VERSION "dbc-export 1 2026.26.6.5"

NS_ :

BS_:

BU_: ADSP APB APP APS APSB BB BMS CC CMP CMPD CP DAS DI DIF DIR DPB EPAS3P EPAS3S EPASTP EPASTS EPBL EPBR ESP EVSE FC GTW HCML HCMR HVP IBST ICR IDB LS OCS1P ODIN PARK PCS PCS2 PLG PM PMF PMR PNCD PTC RADC RCM RCM2 RCM3 RCU SCCM SCM SCS SDCR TAS TCU TCU2 TPMS TRCM UDS UI UIS UMC USM V2G VC VCBATT VCBATT0 VCBATT1 VCBATT2 VCCC VCFRONT VCFRONT1 VCFRONT2 VCLEFT VCRIGHT VCSEAT2L VCSEAT2R VCSEC VEH

BO_ 785 EPAS3S_info: 8 EPAS3S
 SG_ EPAS3S_infoIndex M : 0|8@1+ (1,0) [0|255] "" Vector__XXX
 SG_ EPAS3S_infoBuildType m10 : 8|8@1+ (1,0) [0|255] "" Vector__XXX
 SG_ EPAS3S_infoComponentID m10 : 48|16@1+ (1,0) [0|65535] "" Vector__XXX
 SG_ EPAS3S_infoPcbaID m11 : 16|8@1+ (1,0) [0|255] "" Vector__XXX
 SG_ EPAS3S_infoAssemblyID m11 : 24|8@1+ (1,0) [0|255] "" Vector__XXX
 SG_ EPAS3S_infoUsageID m11 : 32|16@1+ (1,0) [0|65535] "" Vector__XXX
 SG_ EPAS3S_infoApplicationCRC m13 : 32|32@1+ (1,0) [0|4294967295] "" Vector__XXX
 SG_ EPAS3S_infoBootUdsProtoVersion m20 : 8|8@1+ (1,0) [0|255] "" Vector__XXX
 SG_ EPAS3S_infoBootloaderCRC m20 : 32|32@1+ (1,0) [0|4294967295] "" Vector__XXX
 SG_ EPAS3S_infoSubcomponent2 m23 : 32|32@1+ (1,0) [0|4294967295] "" Vector__XXX

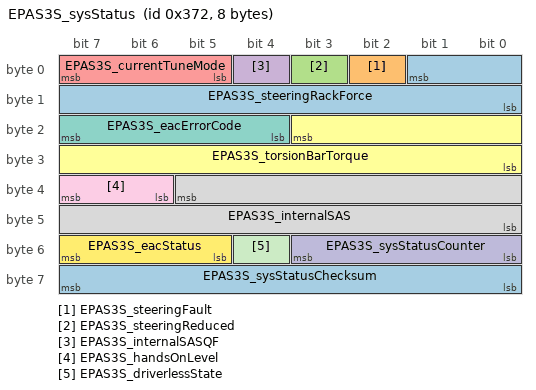
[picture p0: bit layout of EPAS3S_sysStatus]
BO_ 882 EPAS3S_sysStatus: 8 EPAS3S
 SG_ EPAS3S_steeringRackForce : 1|10@0+ (50,-25575) [-25575|25525] "N" Vector__XXX
 SG_ EPAS3S_steeringFault : 2|1@1+ (1,0) [0|1] "" Vector__XXX
 SG_ EPAS3S_steeringReduced : 3|1@1+ (1,0) [0|1] "" Vector__XXX
 SG_ EPAS3S_internalSASQF : 4|1@1+ (1,0) [0|1] "" Vector__XXX
 SG_ EPAS3S_currentTuneMode : 5|3@1+ (1,0) [0|7] "" Vector__XXX
 SG_ EPAS3S_torsionBarTorque : 19|12@0+ (0.01,-20.5) [-20.5|20.44] "Nm" Vector__XXX
 SG_ EPAS3S_eacErrorCode : 20|4@1+ (1,0) [0|14] "" Vector__XXX
 SG_ EPAS3S_internalSAS : 37|14@0+ (0.1,-819.2) [-819.2|819] "deg" Vector__XXX
 SG_ EPAS3S_handsOnLevel : 38|2@1+ (1,0) [0|3] "" Vector__XXX
 SG_ EPAS3S_sysStatusCounter : 48|4@1+ (1,0) [0|15] "" Vector__XXX
 SG_ EPAS3S_driverlessState : 52|1@1+ (1,0) [0|1] "" Vector__XXX
 SG_ EPAS3S_eacStatus : 53|3@1+ (1,0) [0|7] "" Vector__XXX
 SG_ EPAS3S_sysStatusChecksum : 56|8@1+ (1,0) [0|255] "" Vector__XXX

BO_ 1848 EPAS3S_udsResponse: 8 EPAS3S
 SG_ EPAS3S_udsResponseData : 7|64@0+ (1,0) [0|1.84467440737e+19] "" Vector__XXX

BO_ 1427 EPASTP_alertLog: 8 EPASTP
 SG_ EPASTP_alertID M : 0|9@1+ (1,0) [0|511] "" Vector__XXX
 SG_ EPASTP_alertState : 15|1@1+ (1,0) [0|1] "" Vector__XXX
 SG_ EPASTP_a001_debugInfo m1 : 16|48@1+ (1,0) [0|281474976710655] "" Vector__XXX
 SG_ EPASTP_a002_debugInfo m2 : 16|48@1+ (1,0) [0|281474976710655] "" Vector__XXX
 SG_ EPASTP_a003_debugInfo m3 : 16|48@1+ (1,0) [0|281474976710655] "" Vector__XXX
 SG_ EPASTP_a004_debugInfo m4 : 16|48@1+ (1,0) [0|281474976710655] "" Vector__XXX
 SG_ EPASTP_a005_debugInfo m5 : 16|48@1+ (1,0) [0|281474976710655] "" Vector__XXX
 SG_ EPASTP_a006_debugInfo m6 : 16|48@1+ (1,0) [0|281474976710655] "" Vector__XXX
 SG_ EPASTP_a007_debugInfo m7 : 16|48@1+ (1,0) [0|281474976710655] "" Vector__XXX
 SG_ EPASTP_a009_debugInfo m9 : 16|48@1+ (1,0) [0|281474976710655] "" Vector__XXX
 SG_ EPASTP_a010_debugInfo m10 : 16|48@1+ (1,0) [0|281474976710655] "" Vector__XXX
 SG_ EPASTP_a011_debugInfo m11 : 16|48@1+ (1,0) [0|281474976710655] "" Vector__XXX
 SG_ EPASTP_a012_debugInfo m12 : 16|48@1+ (1,0) [0|281474976710655] "" Vector__XXX
 SG_ EPASTP_a013_debugInfo m13 : 16|48@1+ (1,0) [0|281474976710655] "" Vector__XXX
 SG_ EPASTP_a014_debugInfo m14 : 16|48@1+ (1,0) [0|281474976710655] "" Vector__XXX
 SG_ EPASTP_a015_debugInfo m15 : 16|48@1+ (1,0) [0|281474976710655] "" Vector__XXX
 SG_ EPASTP_a016_debugInfo m16 : 16|48@1+ (1,0) [0|281474976710655] "" Vector__XXX
 SG_ EPASTP_a017_debugInfo m17 : 16|48@1+ (1,0) [0|281474976710655] "" Vector__XXX
 SG_ EPASTP_a018_debugInfo m18 : 16|48@1+ (1,0) [0|281474976710655] "" Vector__XXX
 SG_ EPASTP_a019_debugInfo m19 : 16|48@1+ (1,0) [0|281474976710655] "" Vector__XXX
 SG_ EPASTP_a020_debugInfo m20 : 16|48@1+ (1,0) [0|281474976710655] "" Vector__XXX
 SG_ EPASTP_a021_debugInfo m21 : 16|48@1+ (1,0) [0|281474976710655] "" Vector__XXX
 SG_ EPASTP_a022_debugInfo m22 : 16|48@1+ (1,0) [0|281474976710655] "" Vector__XXX
 SG_ EPASTP_a023_debugInfo m23 : 16|48@1+ (1,0) [0|281474976710655] "" Vector__XXX
 SG_ EPASTP_a024_debugInfo m24 : 16|48@1+ (1,0) [0|281474976710655] "" Vector__XXX
 SG_ EPASTP_a025_debugInfo m25 : 16|48@1+ (1,0) [0|281474976710655] "" Vector__XXX
 SG_ EPASTP_a026_debugInfo m26 : 16|48@1+ (1,0) [0|281474976710655] "" Vector__XXX
 SG_ EPASTP_a027_debugInfo m27 : 16|48@1+ (1,0) [0|281474976710655] "" Vector__XXX
 SG_ EPASTP_a028_debugInfo m28 : 16|48@1+ (1,0) [0|281474976710655] "" Vector__XXX
 SG_ EPASTP_a029_debugInfo m29 : 16|48@1+ (1,0) [0|281474976710655] "" Vector__XXX
 SG_ EPASTP_a030_debugInfo m30 : 16|48@1+ (1,0) [0|281474976710655] "" Vector__XXX
 SG_ EPASTP_a031_debugInfo m31 : 16|48@1+ (1,0) [0|281474976710655] "" Vector__XXX
 SG_ EPASTP_a032_debugInfo m32 : 16|48@1+ (1,0) [0|281474976710655] "" Vector__XXX
 SG_ EPASTP_a033_debugInfo m33 : 16|48@1+ (1,0) [0|281474976710655] "" Vector__XXX
 SG_ EPASTP_a034_debugInfo m34 : 16|48@1+ (1,0) [0|281474976710655] "" Vector__XXX
 SG_ EPASTP_a035_debugInfo m35 : 16|48@1+ (1,0) [0|281474976710655] "" Vector__XXX
 SG_ EPASTP_a036_debugInfo m36 : 16|48@1+ (1,0) [0|281474976710655] "" Vector__XXX
 SG_ EPASTP_a037_debugInfo m37 : 16|48@1+ (1,0) [0|281474976710655] "" Vector__XXX
 SG_ EPASTP_a038_debugInfo m38 : 16|48@1+ (1,0) [0|281474976710655] "" Vector__XXX
 SG_ EPASTP_a039_debugInfo m39 : 16|48@1+ (1,0) [0|281474976710655] "" Vector__XXX
 SG_ EPASTP_a040_debugInfo m40 : 16|48@1+ (1,0) [0|281474976710655] "" Vector__XXX
 SG_ EPASTP_a041_debugInfo m41 : 16|48@1+ (1,0) [0|281474976710655] "" Vector__XXX
 SG_ EPASTP_a042_debugInfo m42 : 16|48@1+ (1,0) [0|281474976710655] "" Vector__XXX
 SG_ EPASTP_a043_debugInfo m43 : 16|48@1+ (1,0) [0|281474976710655] "" Vector__XXX
 SG_ EPASTP_a044_debugInfo m44 : 16|48@1+ (1,0) [0|281474976710655] "" Vector__XXX
 SG_ EPASTP_a045_debugInfo m45 : 16|48@1+ (1,0) [0|281474976710655] "" Vector__XXX
 SG_ EPASTP_a046_debugInfo m46 : 16|48@1+ (1,0) [0|281474976710655] "" Vector__XXX
 SG_ EPASTP_a047_debugInfo m47 : 16|48@1+ (1,0) [0|281474976710655] "" Vector__XXX
 SG_ EPASTP_a048_debugInfo m48 : 16|48@1+ (1,0) [0|281474976710655] "" Vector__XXX
 SG_ EPASTP_a049_debugInfo m49 : 16|48@1+ (1,0) [0|281474976710655] "" Vector__XXX
 SG_ EPASTP_a050_debugInfo m50 : 16|48@1+ (1,0) [0|281474976710655] "" Vector__XXX
 SG_ EPASTP_a051_debugInfo m51 : 16|48@1+ (1,0) [0|281474976710655] "" Vector__XXX
 SG_ EPASTP_a052_debugInfo m52 : 16|48@1+ (1,0) [0|281474976710655] "" Vector__XXX
 SG_ EPASTP_a053_debugInfo m53 : 16|48@1+ (1,0) [0|281474976710655] "" Vector__XXX
 SG_ EPASTP_a054_debugInfo m54 : 16|48@1+ (1,0) [0|281474976710655] "" Vector__XXX
 SG_ EPASTP_a055_debugInfo m55 : 16|48@1+ (1,0) [0|281474976710655] "" Vector__XXX
 SG_ EPASTP_a056_debugInfo m56 : 16|48@1+ (1,0) [0|281474976710655] "" Vector__XXX
 SG_ EPASTP_a057_debugInfo m57 : 16|48@1+ (1,0) [0|281474976710655] "" Vector__XXX
 SG_ EPASTP_a058_debugInfo m58 : 16|48@1+ (1,0) [0|281474976710655] "" Vector__XXX
 SG_ EPASTP_a059_debugInfo m59 : 16|48@1+ (1,0) [0|281474976710655] "" Vector__XXX
 SG_ EPASTP_a060_debugInfo m60 : 16|48@1+ (1,0) [0|281474976710655] "" Vector__XXX
 SG_ EPASTP_a061_debugInfo m61 : 16|48@1+ (1,0) [0|281474976710655] "" Vector__XXX
 SG_ EPASTP_a062_debugInfo m62 : 16|48@1+ (1,0) [0|281474976710655] "" Vector__XXX
 SG_ EPASTP_a063_debugInfo m63 : 16|48@1+ (1,0) [0|281474976710655] "" Vector__XXX
 SG_ EPASTP_a064_debugInfo m64 : 16|48@1+ (1,0) [0|281474976710655] "" Vector__XXX
 SG_ EPASTP_a065_debugInfo m65 : 16|48@1+ (1,0) [0|281474976710655] "" Vector__XXX
 SG_ EPASTP_a066_debugInfo m66 : 16|48@1+ (1,0) [0|281474976710655] "" Vector__XXX
 SG_ EPASTP_a067_debugInfo m67 : 16|48@1+ (1,0) [0|281474976710655] "" Vector__XXX
 SG_ EPASTP_a068_debugInfo m68 : 16|48@1+ (1,0) [0|281474976710655] "" Vector__XXX
 SG_ EPASTP_a069_debugInfo m69 : 16|48@1+ (1,0) [0|281474976710655] "" Vector__XXX
 SG_ EPASTP_a070_debugInfo m70 : 16|48@1+ (1,0) [0|281474976710655] "" Vector__XXX
 SG_ EPASTP_a071_debugInfo m71 : 16|48@1+ (1,0) [0|281474976710655] "" Vector__XXX
 SG_ EPASTP_a072_debugInfo m72 : 16|48@1+ (1,0) [0|281474976710655] "" Vector__XXX
 SG_ EPASTP_a073_debugInfo m73 : 16|48@1+ (1,0) [0|281474976710655] "" Vector__XXX
 SG_ EPASTP_a074_debugInfo m74 : 16|48@1+ (1,0) [0|281474976710655] "" Vector__XXX
 SG_ EPASTP_a075_debugInfo m75 : 16|48@1+ (1,0) [0|281474976710655] "" Vector__XXX
 SG_ EPASTP_a076_debugInfo m76 : 16|48@1+ (1,0) [0|281474976710655] "" Vector__XXX
 SG_ EPASTP_a077_debugInfo m77 : 16|48@1+ (1,0) [0|281474976710655] "" Vector__XXX
 SG_ EPASTP_a078_debugInfo m78 : 16|48@1+ (1,0) [0|281474976710655] "" Vector__XXX
 SG_ EPASTP_a079_debugInfo m79 : 16|48@1+ (1,0) [0|281474976710655] "" Vector__XXX
 SG_ EPASTP_a080_debugInfo m80 : 16|48@1+ (1,0) [0|281474976710655] "" Vector__XXX
 SG_ EPASTP_a081_debugInfo m81 : 16|48@1+ (1,0) [0|281474976710655] "" Vector__XXX
 SG_ EPASTP_a082_debugInfo m82 : 16|48@1+ (1,0) [0|281474976710655] "" Vector__XXX
 SG_ EPASTP_a083_debugInfo m83 : 16|48@1+ (1,0) [0|281474976710655] "" Vector__XXX
 SG_ EPASTP_a084_debugInfo m84 : 16|48@1+ (1,0) [0|281474976710655] "" Vector__XXX
 SG_ EPASTP_a085_debugInfo m85 : 16|48@1+ (1,0) [0|281474976710655] "" Vector__XXX
 SG_ EPASTP_a086_debugInfo m86 : 16|48@1+ (1,0) [0|281474976710655] "" Vector__XXX
 SG_ EPASTP_a087_debugInfo m87 : 16|48@1+ (1,0) [0|281474976710655] "" Vector__XXX
 SG_ EPASTP_a088_debugInfo m88 : 16|48@1+ (1,0) [0|281474976710655] "" Vector__XXX
 SG_ EPASTP_a089_debugInfo m89 : 16|48@1+ (1,0) [0|281474976710655] "" Vector__XXX
 SG_ EPASTP_a090_debugInfo m90 : 16|48@1+ (1,0) [0|281474976710655] "" Vector__XXX
 SG_ EPASTP_a091_debugInfo m91 : 16|48@1+ (1,0) [0|281474976710655] "" Vector__XXX
 SG_ EPASTP_a092_debugInfo m92 : 16|48@1+ (1,0) [0|281474976710655] "" Vector__XXX
 SG_ EPASTP_a093_debugInfo m93 : 16|48@1+ (1,0) [0|281474976710655] "" Vector__XXX
 SG_ EPASTP_a094_debugInfo m94 : 16|48@1+ (1,0) [0|281474976710655] "" Vector__XXX
 SG_ EPASTP_a095_debugInfo m95 : 16|48@1+ (1,0) [0|281474976710655] "" Vector__XXX
 SG_ EPASTP_a096_debugInfo m96 : 16|48@1+ (1,0) [0|281474976710655] "" Vector__XXX
 SG_ EPASTP_a097_debugInfo m97 : 16|48@1+ (1,0) [0|281474976710655] "" Vector__XXX
 SG_ EPASTP_a098_debugInfo m98 : 16|48@1+ (1,0) [0|281474976710655] "" Vector__XXX
 SG_ EPASTP_a099_debugInfo m99 : 16|48@1+ (1,0) [0|281474976710655] "" Vector__XXX
 SG_ EPASTP_a100_debugInfo m100 : 16|48@1+ (1,0) [0|281474976710655] "" Vector__XXX
 SG_ EPASTP_a101_debugInfo m101 : 16|48@1+ (1,0) [0|281474976710655] "" Vector__XXX
 SG_ EPASTP_a102_debugInfo m102 : 16|48@1+ (1,0) [0|281474976710655] "" Vector__XXX
 SG_ EPASTP_a103_debugInfo m103 : 16|48@1+ (1,0) [0|281474976710655] "" Vector__XXX
 SG_ EPASTP_a104_debugInfo m104 : 16|48@1+ (1,0) [0|281474976710655] "" Vector__XXX
 SG_ EPASTP_a105_debugInfo m105 : 16|48@1+ (1,0) [0|281474976710655] "" Vector__XXX
 SG_ EPASTP_a106_debugInfo m106 : 16|48@1+ (1,0) [0|281474976710655] "" Vector__XXX
 SG_ EPASTP_a107_debugInfo m107 : 16|48@1+ (1,0) [0|281474976710655] "" Vector__XXX
 SG_ EPASTP_a108_debugInfo m108 : 16|48@1+ (1,0) [0|281474976710655] "" Vector__XXX
 SG_ EPASTP_a109_debugInfo m109 : 16|48@1+ (1,0) [0|281474976710655] "" Vector__XXX
 SG_ EPASTP_a110_debugInfo m110 : 16|48@1+ (1,0) [0|281474976710655] "" Vector__XXX
 SG_ EPASTP_a111_debugInfo m111 : 16|48@1+ (1,0) [0|281474976710655] "" Vector__XXX
 SG_ EPASTP_a112_debugInfo m112 : 16|48@1+ (1,0) [0|281474976710655] "" Vector__XXX
 SG_ EPASTP_a113_debugInfo m113 : 16|48@1+ (1,0) [0|281474976710655] "" Vector__XXX
 SG_ EPASTP_a114_debugInfo m114 : 16|48@1+ (1,0) [0|281474976710655] "" Vector__XXX
 SG_ EPASTP_a115_debugInfo m115 : 16|48@1+ (1,0) [0|281474976710655] "" Vector__XXX
 SG_ EPASTP_a116_debugInfo m116 : 16|48@1+ (1,0) [0|281474976710655] "" Vector__XXX
 SG_ EPASTP_a117_debugInfo m117 : 16|48@1+ (1,0) [0|281474976710655] "" Vector__XXX
 SG_ EPASTP_a118_debugInfo m118 : 16|48@1+ (1,0) [0|281474976710655] "" Vector__XXX
 SG_ EPASTP_a119_debugInfo m119 : 16|48@1+ (1,0) [0|281474976710655] "" Vector__XXX
 SG_ EPASTP_a120_debugInfo m120 : 16|48@1+ (1,0) [0|281474976710655] "" Vector__XXX
 SG_ EPASTP_a121_debugInfo m121 : 16|48@1+ (1,0) [0|281474976710655] "" Vector__XXX
 SG_ EPASTP_a122_debugInfo m122 : 16|48@1+ (1,0) [0|281474976710655] "" Vector__XXX
 SG_ EPASTP_a123_debugInfo m123 : 16|48@1+ (1,0) [0|281474976710655] "" Vector__XXX
 SG_ EPASTP_a124_debugInfo m124 : 16|48@1+ (1,0) [0|281474976710655] "" Vector__XXX
 SG_ EPASTP_a125_debugInfo m125 : 16|48@1+ (1,0) [0|281474976710655] "" Vector__XXX
 SG_ EPASTP_a126_debugInfo m126 : 16|48@1+ (1,0) [0|281474976710655] "" Vector__XXX
 SG_ EPASTP_a127_debugInfo m127 : 16|48@1+ (1,0) [0|281474976710655] "" Vector__XXX
 SG_ EPASTP_a128_debugInfo m128 : 16|48@1+ (1,0) [0|281474976710655] "" Vector__XXX
 SG_ EPASTP_a129_debugInfo m129 : 16|48@1+ (1,0) [0|281474976710655] "" Vector__XXX
 SG_ EPASTP_a130_debugInfo m130 : 16|48@1+ (1,0) [0|281474976710655] "" Vector__XXX
 SG_ EPASTP_a131_debugInfo m131 : 16|48@1+ (1,0) [0|281474976710655] "" Vector__XXX
 SG_ EPASTP_a132_debugInfo m132 : 16|48@1+ (1,0) [0|281474976710655] "" Vector__XXX
 SG_ EPASTP_a133_debugInfo m133 : 16|48@1+ (1,0) [0|281474976710655] "" Vector__XXX
 SG_ EPASTP_a134_debugInfo m134 : 16|48@1+ (1,0) [0|281474976710655] "" Vector__XXX
 SG_ EPASTP_a135_debugInfo m135 : 16|48@1+ (1,0) [0|281474976710655] "" Vector__XXX
 SG_ EPASTP_a136_debugInfo m136 : 16|48@1+ (1,0) [0|281474976710655] "" Vector__XXX
 SG_ EPASTP_a137_debugInfo m137 : 16|48@1+ (1,0) [0|281474976710655] "" Vector__XXX
 SG_ EPASTP_a138_debugInfo m138 : 16|48@1+ (1,0) [0|281474976710655] "" Vector__XXX
 SG_ EPASTP_a139_debugInfo m139 : 16|48@1+ (1,0) [0|281474976710655] "" Vector__XXX
 SG_ EPASTP_a140_debugInfo m140 : 16|48@1+ (1,0) [0|281474976710655] "" Vector__XXX
 SG_ EPASTP_a141_debugInfo m141 : 16|48@1+ (1,0) [0|281474976710655] "" Vector__XXX
 SG_ EPASTP_a142_debugInfo m142 : 16|48@1+ (1,0) [0|281474976710655] "" Vector__XXX
 SG_ EPASTP_a143_debugInfo m143 : 16|48@1+ (1,0) [0|281474976710655] "" Vector__XXX
 SG_ EPASTP_a144_debugInfo m144 : 16|48@1+ (1,0) [0|281474976710655] "" Vector__XXX
 SG_ EPASTP_a145_debugInfo m145 : 16|48@1+ (1,0) [0|281474976710655] "" Vector__XXX
 SG_ EPASTP_a146_debugInfo m146 : 16|48@1+ (1,0) [0|281474976710655] "" Vector__XXX
 SG_ EPASTP_a147_debugInfo m147 : 16|48@1+ (1,0) [0|281474976710655] "" Vector__XXX
 SG_ EPASTP_a148_debugInfo m148 : 16|48@1+ (1,0) [0|281474976710655] "" Vector__XXX
 SG_ EPASTP_a149_debugInfo m149 : 16|48@1+ (1,0) [0|281474976710655] "" Vector__XXX
 SG_ EPASTP_a150_debugInfo m150 : 16|48@1+ (1,0) [0|281474976710655] "" Vector__XXX
 SG_ EPASTP_a152_debugInfo m152 : 16|48@1+ (1,0) [0|281474976710655] "" Vector__XXX
 SG_ EPASTP_a153_debugInfo m153 : 16|48@1+ (1,0) [0|281474976710655] "" Vector__XXX
 SG_ EPASTP_a154_debugInfo m154 : 16|48@1+ (1,0) [0|281474976710655] "" Vector__XXX
 SG_ EPASTP_a155_debugInfo m155 : 16|48@1+ (1,0) [0|281474976710655] "" Vector__XXX
 SG_ EPASTP_a156_debugInfo m156 : 16|48@1+ (1,0) [0|281474976710655] "" Vector__XXX
 SG_ EPASTP_a157_debugInfo m157 : 16|48@1+ (1,0) [0|281474976710655] "" Vector__XXX
 SG_ EPASTP_a158_debugInfo m158 : 16|48@1+ (1,0) [0|281474976710655] "" Vector__XXX
 SG_ EPASTP_a159_debugInfo m159 : 16|48@1+ (1,0) [0|281474976710655] "" Vector__XXX
 SG_ EPASTP_a160_debugInfo m160 : 16|48@1+ (1,0) [0|281474976710655] "" Vector__XXX
 SG_ EPASTP_a161_debugInfo m161 : 16|48@1+ (1,0) [0|281474976710655] "" Vector__XXX
 SG_ EPASTP_a162_debugInfo m162 : 16|48@1+ (1,0) [0|281474976710655] "" Vector__XXX
 SG_ EPASTP_a163_debugInfo m163 : 16|48@1+ (1,0) [0|281474976710655] "" Vector__XXX
 SG_ EPASTP_a164_debugInfo m164 : 16|48@1+ (1,0) [0|281474976710655] "" Vector__XXX
 SG_ EPASTP_a165_debugInfo m165 : 16|48@1+ (1,0) [0|281474976710655] "" Vector__XXX
 SG_ EPASTP_a166_debugInfo m166 : 16|48@1+ (1,0) [0|281474976710655] "" Vector__XXX
 SG_ EPASTP_a167_debugInfo m167 : 16|48@1+ (1,0) [0|281474976710655] "" Vector__XXX
 SG_ EPASTP_a168_debugInfo m168 : 16|48@1+ (1,0) [0|281474976710655] "" Vector__XXX
 SG_ EPASTP_a169_debugInfo m169 : 16|48@1+ (1,0) [0|281474976710655] "" Vector__XXX
 SG_ EPASTP_a170_debugInfo m170 : 16|48@1+ (1,0) [0|281474976710655] "" Vector__XXX
 SG_ EPASTP_a171_debugInfo m171 : 16|48@1+ (1,0) [0|281474976710655] "" Vector__XXX
 SG_ EPASTP_a172_debugInfo m172 : 16|48@1+ (1,0) [0|281474976710655] "" Vector__XXX
 SG_ EPASTP_a173_debugInfo m173 : 16|48@1+ (1,0) [0|281474976710655] "" Vector__XXX
 SG_ EPASTP_a174_debugInfo m174 : 16|48@1+ (1,0) [0|281474976710655] "" Vector__XXX
 SG_ EPASTP_a175_debugInfo m175 : 16|48@1+ (1,0) [0|281474976710655] "" Vector__XXX
 SG_ EPASTP_a176_debugInfo m176 : 16|48@1+ (1,0) [0|281474976710655] "" Vector__XXX
 SG_ EPASTP_a177_debugInfo m177 : 16|48@1+ (1,0) [0|281474976710655] "" Vector__XXX
 SG_ EPASTP_a178_debugInfo m178 : 16|48@1+ (1,0) [0|281474976710655] "" Vector__XXX
 SG_ EPASTP_a179_debugInfo m179 : 16|48@1+ (1,0) [0|281474976710655] "" Vector__XXX
 SG_ EPASTP_a180_debugInfo m180 : 16|48@1+ (1,0) [0|281474976710655] "" Vector__XXX
 SG_ EPASTP_a181_debugInfo m181 : 16|48@1+ (1,0) [0|281474976710655] "" Vector__XXX
 SG_ EPASTP_a182_debugInfo m182 : 16|48@1+ (1,0) [0|281474976710655] "" Vector__XXX
 SG_ EPASTP_a183_debugInfo m183 : 16|48@1+ (1,0) [0|281474976710655] "" Vector__XXX
 SG_ EPASTP_a184_debugInfo m184 : 16|48@1+ (1,0) [0|281474976710655] "" Vector__XXX
 SG_ EPASTP_a185_debugInfo m185 : 16|48@1+ (1,0) [0|281474976710655] "" Vector__XXX
 SG_ EPASTP_a186_debugInfo m186 : 16|48@1+ (1,0) [0|281474976710655] "" Vector__XXX
 SG_ EPASTP_a188_debugInfo m188 : 16|48@1+ (1,0) [0|281474976710655] "" Vector__XXX
 SG_ EPASTP_a189_debugInfo m189 : 16|48@1+ (1,0) [0|281474976710655] "" Vector__XXX
 SG_ EPASTP_a190_debugInfo m190 : 16|48@1+ (1,0) [0|281474976710655] "" Vector__XXX
 SG_ EPASTP_a191_debugInfo m191 : 16|48@1+ (1,0) [0|281474976710655] "" Vector__XXX
 SG_ EPASTP_a192_debugInfo m192 : 16|48@1+ (1,0) [0|281474976710655] "" Vector__XXX
 SG_ EPASTP_a193_debugInfo m193 : 16|48@1+ (1,0) [0|281474976710655] "" Vector__XXX
 SG_ EPASTP_a194_debugInfo m194 : 16|48@1+ (1,0) [0|281474976710655] "" Vector__XXX
 SG_ EPASTP_a195_debugInfo m195 : 16|48@1+ (1,0) [0|281474976710655] "" Vector__XXX
 SG_ EPASTP_a196_debugInfo m196 : 16|48@1+ (1,0) [0|281474976710655] "" Vector__XXX
 SG_ EPASTP_a197_debugInfo m197 : 16|48@1+ (1,0) [0|281474976710655] "" Vector__XXX
 SG_ EPASTP_a198_debugInfo m198 : 16|48@1+ (1,0) [0|281474976710655] "" Vector__XXX
 SG_ EPASTP_a199_debugInfo m199 : 16|48@1+ (1,0) [0|281474976710655] "" Vector__XXX
 SG_ EPASTP_a200_debugInfo m200 : 16|48@1+ (1,0) [0|281474976710655] "" Vector__XXX
 SG_ EPASTP_a201_debugInfo m201 : 16|48@1+ (1,0) [0|281474976710655] "" Vector__XXX
 SG_ EPASTP_a202_debugInfo m202 : 16|48@1+ (1,0) [0|281474976710655] "" Vector__XXX
 SG_ EPASTP_a203_debugInfo m203 : 16|48@1+ (1,0) [0|281474976710655] "" Vector__XXX
 SG_ EPASTP_a204_debugInfo m204 : 16|48@1+ (1,0) [0|281474976710655] "" Vector__XXX
 SG_ EPASTP_a205_debugInfo m205 : 16|48@1+ (1,0) [0|281474976710655] "" Vector__XXX
 SG_ EPASTP_a206_debugInfo m206 : 16|48@1+ (1,0) [0|281474976710655] "" Vector__XXX
 SG_ EPASTP_a207_debugInfo m207 : 16|48@1+ (1,0) [0|281474976710655] "" Vector__XXX
 SG_ EPASTP_a208_debugInfo m208 : 16|48@1+ (1,0) [0|281474976710655] "" Vector__XXX
 SG_ EPASTP_a209_debugInfo m209 : 16|48@1+ (1,0) [0|281474976710655] "" Vector__XXX
 SG_ EPASTP_a210_debugInfo m210 : 16|48@1+ (1,0) [0|281474976710655] "" Vector__XXX
 SG_ EPASTP_a211_debugInfo m211 : 16|48@1+ (1,0) [0|281474976710655] "" Vector__XXX
 SG_ EPASTP_a212_debugInfo m212 : 16|48@1+ (1,0) [0|281474976710655] "" Vector__XXX
 SG_ EPASTP_a213_debugInfo m213 : 16|48@1+ (1,0) [0|281474976710655] "" Vector__XXX
 SG_ EPASTP_a214_debugInfo m214 : 16|48@1+ (1,0) [0|281474976710655] "" Vector__XXX
 SG_ EPASTP_a215_debugInfo m215 : 16|48@1+ (1,0) [0|281474976710655] "" Vector__XXX
 SG_ EPASTP_a216_debugInfo m216 : 16|48@1+ (1,0) [0|281474976710655] "" Vector__XXX
 SG_ EPASTP_a217_debugInfo m217 : 16|48@1+ (1,0) [0|281474976710655] "" Vector__XXX
 SG_ EPASTP_a218_debugInfo m218 : 16|48@1+ (1,0) [0|281474976710655] "" Vector__XXX
 SG_ EPASTP_a219_debugInfo m219 : 16|48@1+ (1,0) [0|281474976710655] "" Vector__XXX
 SG_ EPASTP_a221_debugInfo m221 : 16|48@1+ (1,0) [0|281474976710655] "" Vector__XXX
 SG_ EPASTP_a222_debugInfo m222 : 16|48@1+ (1,0) [0|281474976710655] "" Vector__XXX
 SG_ EPASTP_a223_debugInfo m223 : 16|48@1+ (1,0) [0|281474976710655] "" Vector__XXX
 SG_ EPASTP_a224_debugInfo m224 : 16|48@1+ (1,0) [0|281474976710655] "" Vector__XXX
 SG_ EPASTP_a225_debugInfo m225 : 16|48@1+ (1,0) [0|281474976710655] "" Vector__XXX
 SG_ EPASTP_a226_debugInfo m226 : 16|48@1+ (1,0) [0|281474976710655] "" Vector__XXX
 SG_ EPASTP_a227_debugInfo m227 : 16|48@1+ (1,0) [0|281474976710655] "" Vector__XXX
 SG_ EPASTP_a228_debugInfo m228 : 16|48@1+ (1,0) [0|281474976710655] "" Vector__XXX
 SG_ EPASTP_a229_debugInfo m229 : 16|48@1+ (1,0) [0|281474976710655] "" Vector__XXX
 SG_ EPASTP_a230_debugInfo m230 : 16|48@1+ (1,0) [0|281474976710655] "" Vector__XXX
 SG_ EPASTP_a231_debugInfo m231 : 16|48@1+ (1,0) [0|281474976710655] "" Vector__XXX
 SG_ EPASTP_a232_debugInfo m232 : 16|48@1+ (1,0) [0|281474976710655] "" Vector__XXX
 SG_ EPASTP_a233_debugInfo m233 : 16|48@1+ (1,0) [0|281474976710655] "" Vector__XXX
 SG_ EPASTP_a234_debugInfo m234 : 16|48@1+ (1,0) [0|281474976710655] "" Vector__XXX
 SG_ EPASTP_a235_debugInfo m235 : 16|48@1+ (1,0) [0|281474976710655] "" Vector__XXX
 SG_ EPASTP_a236_debugInfo m236 : 16|48@1+ (1,0) [0|281474976710655] "" Vector__XXX
 SG_ EPASTP_a237_debugInfo m237 : 16|48@1+ (1,0) [0|281474976710655] "" Vector__XXX
 SG_ EPASTP_a238_debugInfo m238 : 16|48@1+ (1,0) [0|281474976710655] "" Vector__XXX
 SG_ EPASTP_a239_debugInfo m239 : 16|48@1+ (1,0) [0|281474976710655] "" Vector__XXX
 SG_ EPASTP_a240_debugInfo m240 : 16|48@1+ (1,0) [0|281474976710655] "" Vector__XXX
 SG_ EPASTP_a241_debugInfo m241 : 16|48@1+ (1,0) [0|281474976710655] "" Vector__XXX
 SG_ EPASTP_a242_debugInfo m242 : 16|48@1+ (1,0) [0|281474976710655] "" Vector__XXX
 SG_ EPASTP_a243_debugInfo m243 : 16|48@1+ (1,0) [0|281474976710655] "" Vector__XXX
 SG_ EPASTP_a244_debugInfo m244 : 16|48@1+ (1,0) [0|281474976710655] "" Vector__XXX
 SG_ EPASTP_a245_debugInfo m245 : 16|48@1+ (1,0) [0|281474976710655] "" Vector__XXX
 SG_ EPASTP_a246_debugInfo m246 : 16|48@1+ (1,0) [0|281474976710655] "" Vector__XXX
 SG_ EPASTP_a247_debugInfo m247 : 16|48@1+ (1,0) [0|281474976710655] "" Vector__XXX
 SG_ EPASTP_a248_debugInfo m248 : 16|48@1+ (1,0) [0|281474976710655] "" Vector__XXX
 SG_ EPASTP_a249_debugInfo m249 : 16|48@1+ (1,0) [0|281474976710655] "" Vector__XXX
 SG_ EPASTP_a250_debugInfo m250 : 16|48@1+ (1,0) [0|281474976710655] "" Vector__XXX
 SG_ EPASTP_a252_debugInfo m252 : 16|48@1+ (1,0) [0|281474976710655] "" Vector__XXX
 SG_ EPASTP_a253_debugInfo m253 : 16|48@1+ (1,0) [0|281474976710655] "" Vector__XXX
 SG_ EPASTP_a254_debugInfo m254 : 16|48@1+ (1,0) [0|281474976710655] "" Vector__XXX
 SG_ EPASTP_a255_debugInfo m255 : 16|48@1+ (1,0) [0|281474976710655] "" Vector__XXX
 SG_ EPASTP_a256_debugInfo m256 : 16|48@1+ (1,0) [0|281474976710655] "" Vector__XXX
 SG_ EPASTP_a257_debugInfo m257 : 16|48@1+ (1,0) [0|281474976710655] "" Vector__XXX
 SG_ EPASTP_a258_debugInfo m258 : 16|48@1+ (1,0) [0|281474976710655] "" Vector__XXX
 SG_ EPASTP_a259_debugInfo m259 : 16|48@1+ (1,0) [0|281474976710655] "" Vector__XXX
 SG_ EPASTP_a260_debugInfo m260 : 16|48@1+ (1,0) [0|281474976710655] "" Vector__XXX
 SG_ EPASTP_a261_debugInfo m261 : 16|48@1+ (1,0) [0|281474976710655] "" Vector__XXX
 SG_ EPASTP_a262_debugInfo m262 : 16|48@1+ (1,0) [0|281474976710655] "" Vector__XXX
 SG_ EPASTP_a263_debugInfo m263 : 16|48@1+ (1,0) [0|281474976710655] "" Vector__XXX
 SG_ EPASTP_a264_degradedECU m264 : 16|8@1+ (1,0) [0|255] "" Vector__XXX
 SG_ EPASTP_a264_vehicleSpeed m264 : 24|16@1+ (0.1,0) [0|6553.5] "kph" Vector__XXX
 SG_ EPASTP_a264_powerRatio m264 : 40|8@1+ (1,0) [0|255] "percent" Vector__XXX
 SG_ EPASTP_a264_ownSideDegradationRe m264 : 48|8@1+ (1,0) [0|255] "" Vector__XXX
 SG_ EPASTP_a264_otherSideDegradation m264 : 56|8@1+ (1,0) [0|255] "" Vector__XXX
 SG_ EPASTP_a265_degradedECU m265 : 16|8@1+ (1,0) [0|255] "" Vector__XXX
 SG_ EPASTP_a265_vehicleSpeed m265 : 24|16@1+ (0.1,0) [0|6553.5] "kph" Vector__XXX
 SG_ EPASTP_a265_rawMcuTemperature m265 : 40|16@1+ (1,-100) [-100|65435] "C" Vector__XXX
 SG_ EPASTP_a265_degradedCurrentLimit m265 : 56|8@1+ (1,0) [0|255] "A" Vector__XXX
 SG_ EPASTP_a266_cdpAssistFactor m266 : 16|8@1+ (1,0) [0|255] "percent" Vector__XXX
 SG_ EPASTP_a266_vehicleSpeed m266 : 24|16@1+ (0.1,0) [0|6553.5] "kph" Vector__XXX
 SG_ EPASTP_a267_vehicleSpeed m267 : 16|16@1+ (0.1,0) [0|6553.5] "kph" Vector__XXX
 SG_ EPASTP_a267_velocityEstimatorSta m267 : 32|8@1+ (1,0) [0|255] "" Vector__XXX
 SG_ EPASTP_a269_vehicleSpeed m269 : 16|16@1+ (0.1,0) [0|6553.5] "kph" Vector__XXX
 SG_ EPASTP_a270_debugInfo m270 : 16|48@1+ (1,0) [0|281474976710655] "" Vector__XXX

BO_ 919 EPASTP_alertMatrix: 8 EPASTP
 SG_ EPASTP_matrixIndex M : 0|4@1+ (1,0) [0|15] "" Vector__XXX
 SG_ EPASTP_a001_adcCalibrationOrInit m0 : 4|1@1+ (1,0) [0|1] "" Vector__XXX
 SG_ EPASTP_a002_adcMuxErr m0 : 5|1@1+ (1,0) [0|1] "" Vector__XXX
 SG_ EPASTP_a003_pspInvalidParamset m0 : 6|1@1+ (1,0) [0|1] "" Vector__XXX
 SG_ EPASTP_a004_scpInputMia m0 : 7|1@1+ (1,0) [0|1] "" Vector__XXX
 SG_ EPASTP_a005_scpUnknownResetSourc m0 : 8|1@1+ (1,0) [0|1] "" Vector__XXX
 SG_ EPASTP_a006_swrhResetByInvalidEr m0 : 9|1@1+ (1,0) [0|1] "" Vector__XXX
 SG_ EPASTP_a007_tsmcCoreTempDiff m0 : 10|1@1+ (1,0) [0|1] "" Vector__XXX
 SG_ EPASTP_a008_psdcPlatformShutdown m0 : 11|1@1+ (1,0) [0|1] "" Vector__XXX
 SG_ EPASTP_a009_mcusscLbistPermanent m0 : 12|1@1+ (1,0) [0|1] "" Vector__XXX
 SG_ EPASTP_a010_svcIncompatibleSwVer m0 : 13|1@1+ (1,0) [0|1] "" Vector__XXX
 SG_ EPASTP_a011_mcusscMonbistErr m0 : 14|1@1+ (1,0) [0|1] "" Vector__XXX
 SG_ EPASTP_a012_mcusscMbistEccErr m0 : 15|1@1+ (1,0) [0|1] "" Vector__XXX
 SG_ EPASTP_a013_mcusscSffMonitoringF m0 : 16|1@1+ (1,0) [0|1] "" Vector__XXX
 SG_ EPASTP_a014_mcusscSffMonitoringM m0 : 17|1@1+ (1,0) [0|1] "" Vector__XXX
 SG_ EPASTP_a015_mcusscCsErrorCheckFa m0 : 18|1@1+ (1,0) [0|1] "" Vector__XXX
 SG_ EPASTP_a016_mcufcCsErrorCheckFai m0 : 19|1@1+ (1,0) [0|1] "" Vector__XXX
 SG_ EPASTP_a017_stmdStmPlausibilityC m0 : 20|1@1+ (1,0) [0|1] "" Vector__XXX
 SG_ EPASTP_a018_exchCsErrorCheck m0 : 21|1@1+ (1,0) [0|1] "" Vector__XXX
 SG_ EPASTP_a019_rsthHwResetInfoCorru m0 : 22|1@1+ (1,0) [0|1] "" Vector__XXX
 SG_ EPASTP_a020_mcusscEolEcuIdIntegr m0 : 23|1@1+ (1,0) [0|1] "" Vector__XXX
 SG_ EPASTP_a021_osehCsErrorCheck m0 : 24|1@1+ (1,0) [0|1] "" Vector__XXX
 SG_ EPASTP_a022_swrhSwResetInfoCorru m0 : 25|1@1+ (1,0) [0|1] "" Vector__XXX
 SG_ EPASTP_a023_btarcCorruptionCheck m0 : 26|1@1+ (1,0) [0|1] "" Vector__XXX
 SG_ EPASTP_a024_srhCsErrorCheckFail m0 : 27|1@1+ (1,0) [0|1] "" Vector__XXX
 SG_ EPASTP_a025_btarcCorruptionCheck m0 : 28|1@1+ (1,0) [0|1] "" Vector__XXX
 SG_ EPASTP_a026_mrccCsErrorCheckFail m0 : 29|1@1+ (1,0) [0|1] "" Vector__XXX
 SG_ EPASTP_a027_mcusscDmuHfErr m0 : 30|1@1+ (1,0) [0|1] "" Vector__XXX
 SG_ EPASTP_a028_smuhNonInitDataCorru m0 : 31|1@1+ (1,0) [0|1] "" Vector__XXX
 SG_ EPASTP_a029_smuhSmuCoreCntErrorT m0 : 32|1@1+ (1,0) [0|1] "" Vector__XXX
 SG_ EPASTP_a030_rsthClockReset m0 : 33|1@1+ (1,0) [0|1] "" Vector__XXX
 SG_ EPASTP_a031_pmsProductionModeFai m0 : 34|1@1+ (1,0) [0|1] "" Vector__XXX
 SG_ EPASTP_a032_eolpEolCheckFailed m0 : 35|1@1+ (1,0) [0|1] "" Vector__XXX
 SG_ EPASTP_a033_icsvcPswVersionMisma m0 : 36|1@1+ (1,0) [0|1] "" Vector__XXX
 SG_ EPASTP_a034_sbchReadbackRegFail m0 : 37|1@1+ (1,0) [0|1] "" Vector__XXX
 SG_ EPASTP_a035_sbchChipIdFail m0 : 38|1@1+ (1,0) [0|1] "" Vector__XXX
 SG_ EPASTP_a036_sbcmSbcBistFailed m0 : 39|1@1+ (1,0) [0|1] "" Vector__XXX
 SG_ EPASTP_a037_epmV5P2Fail m0 : 40|1@1+ (1,0) [0|1] "" Vector__XXX
 SG_ EPASTP_a038_csohCh1CsErrorErrAtR m0 : 41|1@1+ (1,0) [0|1] "" Vector__XXX
 SG_ EPASTP_a039_csohCh2CsErrorErrAtR m0 : 42|1@1+ (1,0) [0|1] "" Vector__XXX
 SG_ EPASTP_a040_swrhLimitedResetRetr m0 : 43|1@1+ (1,0) [0|1] "" Vector__XXX
 SG_ EPASTP_a041_imcmCoreConfiguratio m0 : 44|1@1+ (1,0) [0|1] "" Vector__XXX
 SG_ EPASTP_a042_wdhWdTestFail m0 : 45|1@1+ (1,0) [0|1] "" Vector__XXX
 SG_ EPASTP_a043_sbcmWdStateDisabled m0 : 46|1@1+ (1,0) [0|1] "" Vector__XXX
 SG_ EPASTP_a044_sbcmSbcEepromFail m0 : 47|1@1+ (1,0) [0|1] "" Vector__XXX
 SG_ EPASTP_a045_psumSbcBandgapVoltEr m0 : 48|1@1+ (1,0) [0|1] "" Vector__XXX
 SG_ EPASTP_a046_mcusscOscillatorNotR m0 : 49|1@1+ (1,0) [0|1] "" Vector__XXX
 SG_ EPASTP_a047_epmVregVoltFail m0 : 50|1@1+ (1,0) [0|1] "" Vector__XXX
 SG_ EPASTP_a048_epmVcpVoltFail m0 : 51|1@1+ (1,0) [0|1] "" Vector__XXX
 SG_ EPASTP_a049_epmLgFail m0 : 52|1@1+ (1,0) [0|1] "" Vector__XXX
 SG_ EPASTP_a050_erlErr m0 : 53|1@1+ (1,0) [0|1] "" Vector__XXX
 SG_ EPASTP_a051_ermMessageErr m0 : 54|1@1+ (1,0) [0|1] "" Vector__XXX
 SG_ EPASTP_a052_ermSdcInputBufferOve m0 : 55|1@1+ (1,0) [0|1] "" Vector__XXX
 SG_ EPASTP_a053_adcUnexpectedNumOfDa m0 : 56|1@1+ (1,0) [0|1] "" Vector__XXX
 SG_ EPASTP_a054_adcUnexpectedData m0 : 57|1@1+ (1,0) [0|1] "" Vector__XXX
 SG_ EPASTP_a055_amExtendedGduTest m0 : 58|1@1+ (1,0) [0|1] "" Vector__XXX
 SG_ EPASTP_a056_amGduConfigCsErrorCh m0 : 59|1@1+ (1,0) [0|1] "" Vector__XXX
 SG_ EPASTP_a057_amGduVds m0 : 60|1@1+ (1,0) [0|1] "" Vector__XXX
 SG_ EPASTP_a058_amIntVgsUndervtgErr m0 : 61|1@1+ (1,0) [0|1] "" Vector__XXX
 SG_ EPASTP_a059_amStartupTestFailed m0 : 62|1@1+ (1,0) [0|1] "" Vector__XXX
 SG_ EPASTP_a060_amGduFail m0 : 63|1@1+ (1,0) [0|1] "" Vector__XXX
 SG_ EPASTP_a061_amIntSerialErr m1 : 4|1@1+ (1,0) [0|1] "" Vector__XXX
 SG_ EPASTP_a062_amPhaseBridgeCheck m1 : 5|1@1+ (1,0) [0|1] "" Vector__XXX
 SG_ EPASTP_a063_amIntRegulatorErr m1 : 6|1@1+ (1,0) [0|1] "" Vector__XXX
 SG_ EPASTP_a064_amBridgeShort m1 : 7|1@1+ (1,0) [0|1] "" Vector__XXX
 SG_ EPASTP_a065_amGduJuncTemp m1 : 8|1@1+ (1,0) [0|1] "" Vector__XXX
 SG_ EPASTP_a066_amVoltQfErr m1 : 9|1@1+ (1,0) [0|1] "" Vector__XXX
 SG_ EPASTP_a067_tspmPowermoduleTempI m1 : 10|1@1+ (1,0) [0|1] "" Vector__XXX
 SG_ EPASTP_a068_rsthCoreRedundancyEr m1 : 11|1@1+ (1,0) [0|1] "" Vector__XXX
 SG_ EPASTP_a069_rsthCoreTempOutOfRan m1 : 12|1@1+ (1,0) [0|1] "" Vector__XXX
 SG_ EPASTP_a070_rsthInternalLowVolt m1 : 13|1@1+ (1,0) [0|1] "" Vector__XXX
 SG_ EPASTP_a071_rsthInternalHighVolt m1 : 14|1@1+ (1,0) [0|1] "" Vector__XXX
 SG_ EPASTP_a072_rsthFlashUncorrEccOr m1 : 15|1@1+ (1,0) [0|1] "" Vector__XXX
 SG_ EPASTP_a073_rsthOtherEdcEcc m1 : 16|1@1+ (1,0) [0|1] "" Vector__XXX
 SG_ EPASTP_a074_rsthUnexpectedAlarm m1 : 17|1@1+ (1,0) [0|1] "" Vector__XXX
 SG_ EPASTP_a075_rsthUnusedOtherModul m1 : 18|1@1+ (1,0) [0|1] "" Vector__XXX
 SG_ EPASTP_a076_exchGeneralException m1 : 19|1@1+ (1,0) [0|1] "" Vector__XXX
 SG_ EPASTP_a077_dmDeadlineViolation m1 : 20|1@1+ (1,0) [0|1] "" Vector__XXX
 SG_ EPASTP_a078_dmDeadlineViolation m1 : 21|1@1+ (1,0) [0|1] "" Vector__XXX
 SG_ EPASTP_a079_gduhComErr m1 : 22|1@1+ (1,0) [0|1] "" Vector__XXX
 SG_ EPASTP_a080_pwmTimerSyncCheck m1 : 23|1@1+ (1,0) [0|1] "" Vector__XXX
 SG_ EPASTP_a081_exchFloatingPointExc m1 : 24|1@1+ (1,0) [0|1] "" Vector__XXX
 SG_ EPASTP_a082_adcTriggerTimeChk m1 : 25|1@1+ (1,0) [0|1] "" Vector__XXX
 SG_ EPASTP_a083_tdaDclinkcapacitorTe m1 : 26|1@1+ (1,0) [0|1] "" Vector__XXX
 SG_ EPASTP_a084_adcTriggerCheck m1 : 27|1@1+ (1,0) [0|1] "" Vector__XXX
 SG_ EPASTP_a085_amGduSwitchOffTestBy m1 : 28|1@1+ (1,0) [0|1] "" Vector__XXX
 SG_ EPASTP_a086_rsthRamUncorrEcc m1 : 29|1@1+ (1,0) [0|1] "" Vector__XXX
 SG_ EPASTP_a087_rsthFlashConfigErr m1 : 30|1@1+ (1,0) [0|1] "" Vector__XXX
 SG_ EPASTP_a088_tedMainboardTempChec m1 : 31|1@1+ (1,0) [0|1] "" Vector__XXX
 SG_ EPASTP_a089_tedRevercebattfetjun m1 : 32|1@1+ (1,0) [0|1] "" Vector__XXX
 SG_ EPASTP_a090_etsmWarning m1 : 33|1@1+ (1,0) [0|1] "" Vector__XXX
 SG_ EPASTP_a091_bvpBattVoltCrossChkF m1 : 34|1@1+ (1,0) [0|1] "" Vector__XXX
 SG_ EPASTP_a092_amGduSwitchOffTestBy m1 : 35|1@1+ (1,0) [0|1] "" Vector__XXX
 SG_ EPASTP_a093_sctpTsuSingleStaticF m1 : 36|1@1+ (1,0) [0|1] "" Vector__XXX
 SG_ EPASTP_a094_sctpTsuMultipleStati m1 : 37|1@1+ (1,0) [0|1] "" Vector__XXX
 SG_ EPASTP_a095_mdModelBasedMotorInt m1 : 38|1@1+ (1,0) [0|1] "" Vector__XXX
 SG_ EPASTP_a096_rppRpsSingleStaticFa m1 : 39|1@1+ (1,0) [0|1] "" Vector__XXX
 SG_ EPASTP_a097_rppRpsMultipleStatic m1 : 40|1@1+ (1,0) [0|1] "" Vector__XXX
 SG_ EPASTP_a098_invErr m1 : 41|1@1+ (1,0) [0|1] "" Vector__XXX
 SG_ EPASTP_a099_mcdTorqueMismatchFau m1 : 42|1@1+ (1,0) [0|1] "" Vector__XXX
 SG_ EPASTP_a100_amVbrgLssFault m1 : 43|1@1+ (1,0) [0|1] "" Vector__XXX
 SG_ EPASTP_a101_sdrvSpcIdMismatch m1 : 44|1@1+ (1,0) [0|1] "" Vector__XXX
 SG_ EPASTP_a102_amPhasecurrentQosErr m1 : 45|1@1+ (1,0) [0|1] "" Vector__XXX
 SG_ EPASTP_a103_exhaUnusedInterruptC m1 : 46|1@1+ (1,0) [0|1] "" Vector__XXX
 SG_ EPASTP_a104_exhaBusMpuException m1 : 47|1@1+ (1,0) [0|1] "" Vector__XXX
 SG_ EPASTP_a105_exhaSriBusErrExcepti m1 : 48|1@1+ (1,0) [0|1] "" Vector__XXX
 SG_ EPASTP_a106_exhaSpbBusErrExcepti m1 : 49|1@1+ (1,0) [0|1] "" Vector__XXX
 SG_ EPASTP_a107_exhaOtherNmiExceptio m1 : 50|1@1+ (1,0) [0|1] "" Vector__XXX
 SG_ EPASTP_a108_exhaInternalProtecti m1 : 51|1@1+ (1,0) [0|1] "" Vector__XXX
 SG_ EPASTP_a109_exhaSysBusOrPeriphEr m1 : 52|1@1+ (1,0) [0|1] "" Vector__XXX
 SG_ EPASTP_a110_amPhaseRelaySwitchOf m1 : 53|1@1+ (1,0) [0|1] "" Vector__XXX
 SG_ EPASTP_a111_amCurrentSensingDisc m1 : 54|1@1+ (1,0) [0|1] "" Vector__XXX
 SG_ EPASTP_a112_rsthSafetyFlipflopEr m1 : 55|1@1+ (1,0) [0|1] "" Vector__XXX
 SG_ EPASTP_a113_rsthUncorrectableEnd m1 : 56|1@1+ (1,0) [0|1] "" Vector__XXX
 SG_ EPASTP_a114_osehOsErr m1 : 57|1@1+ (1,0) [0|1] "" Vector__XXX
 SG_ EPASTP_a115_mcusscLbistSingleFai m1 : 58|1@1+ (1,0) [0|1] "" Vector__XXX
 SG_ EPASTP_a116_mrccStartupRegCsErro m1 : 59|1@1+ (1,0) [0|1] "" Vector__XXX
 SG_ EPASTP_a117_mrccStartupRegCsErro m1 : 60|1@1+ (1,0) [0|1] "" Vector__XXX
 SG_ EPASTP_a118_mcusscFlashCsErrorEr m1 : 61|1@1+ (1,0) [0|1] "" Vector__XXX
 SG_ EPASTP_a119_mcusscFlashEccCritic m1 : 62|1@1+ (1,0) [0|1] "" Vector__XXX
 SG_ EPASTP_a120_mcusscFlashEccLatent m1 : 63|1@1+ (1,0) [0|1] "" Vector__XXX
 SG_ EPASTP_a121_mcusscMbistEccErr m2 : 4|1@1+ (1,0) [0|1] "" Vector__XXX
 SG_ EPASTP_a122_pcpBridgeFetShort m2 : 5|1@1+ (1,0) [0|1] "" Vector__XXX
 SG_ EPASTP_a123_imcmCommErr m2 : 6|1@1+ (1,0) [0|1] "" Vector__XXX
 SG_ EPASTP_a124_mcusscMbistEccTransi m2 : 7|1@1+ (1,0) [0|1] "" Vector__XXX
 SG_ EPASTP_a125_mcusscMbistMiaErr m2 : 8|1@1+ (1,0) [0|1] "" Vector__XXX
 SG_ EPASTP_a126_mcusscMonbistMiaErr m2 : 9|1@1+ (1,0) [0|1] "" Vector__XXX
 SG_ EPASTP_a127_exchAdditionalExcept m2 : 10|1@1+ (1,0) [0|1] "" Vector__XXX
 SG_ EPASTP_a128_exchExceptionStopRes m2 : 11|1@1+ (1,0) [0|1] "" Vector__XXX
 SG_ EPASTP_a129_exchAdditionalExcept m2 : 12|1@1+ (1,0) [0|1] "" Vector__XXX
 SG_ EPASTP_a130_mrccConfigCsErrorErr m2 : 13|1@1+ (1,0) [0|1] "" Vector__XXX
 SG_ EPASTP_a131_exchGuardedResetAfte m2 : 14|1@1+ (1,0) [0|1] "" Vector__XXX
 SG_ EPASTP_a132_mcusscNotSupportedMc m2 : 15|1@1+ (1,0) [0|1] "" Vector__XXX
 SG_ EPASTP_a133_mcusscLbistEcuIdIsNo m2 : 16|1@1+ (1,0) [0|1] "" Vector__XXX
 SG_ EPASTP_a134_osehGuardedResetAfte m2 : 17|1@1+ (1,0) [0|1] "" Vector__XXX
 SG_ EPASTP_a135_tmpsfetjCalculationO m2 : 18|1@1+ (1,0) [0|1] "" Vector__XXX
 SG_ EPASTP_a136_ftElectricalAngleQf m2 : 19|1@1+ (1,0) [0|1] "" Vector__XXX
 SG_ EPASTP_a137_osehErrWithoutImmedi m2 : 20|1@1+ (1,0) [0|1] "" Vector__XXX
 SG_ EPASTP_a138_osehAdditionalErrWit m2 : 21|1@1+ (1,0) [0|1] "" Vector__XXX
 SG_ EPASTP_a139_osehAdditionalOsErr m2 : 22|1@1+ (1,0) [0|1] "" Vector__XXX
 SG_ EPASTP_a140_imcmConfigurationErr m2 : 23|1@1+ (1,0) [0|1] "" Vector__XXX
 SG_ EPASTP_a141_amFetShortTest m2 : 24|1@1+ (1,0) [0|1] "" Vector__XXX
 SG_ EPASTP_a142_tedEmifilterDmcTempC m2 : 25|1@1+ (1,0) [0|1] "" Vector__XXX
 SG_ EPASTP_a143_tedEmifilterCmcTempC m2 : 26|1@1+ (1,0) [0|1] "" Vector__XXX
 SG_ EPASTP_a144_mriCoreRaminitFailed m2 : 27|1@1+ (1,0) [0|1] "" Vector__XXX
 SG_ EPASTP_a145_mriPeripheralRaminit m2 : 28|1@1+ (1,0) [0|1] "" Vector__XXX
 SG_ EPASTP_a146_btarcRcCircuitCheck m2 : 29|1@1+ (1,0) [0|1] "" Vector__XXX
 SG_ EPASTP_a147_amDcLinkShortedFail m2 : 30|1@1+ (1,0) [0|1] "" Vector__XXX
 SG_ EPASTP_a148_mrccExitFromStandbyD m2 : 31|1@1+ (1,0) [0|1] "" Vector__XXX
 SG_ EPASTP_a149_amReversibleEmergenc m2 : 32|1@1+ (1,0) [0|1] "" Vector__XXX
 SG_ EPASTP_a150_amExternalEmergencyO m2 : 33|1@1+ (1,0) [0|1] "" Vector__XXX
 SG_ EPASTP_a151_amPermanentEmergency m2 : 34|1@1+ (1,0) [0|1] "" Vector__XXX
 SG_ EPASTP_a152_exchFlashEccExceptio m2 : 35|1@1+ (1,0) [0|1] "" Vector__XXX
 SG_ EPASTP_a153_sdsmBlockSelectorInv m2 : 36|1@1+ (1,0) [0|1] "" Vector__XXX
 SG_ EPASTP_a154_sdsmCsErrorInvalidPr m2 : 37|1@1+ (1,0) [0|1] "" Vector__XXX
 SG_ EPASTP_a155_sdsmDataInvalidAll m2 : 38|1@1+ (1,0) [0|1] "" Vector__XXX
 SG_ EPASTP_a156_amIntSerialErrSafety m2 : 39|1@1+ (1,0) [0|1] "" Vector__XXX
 SG_ EPASTP_a157_mcudcpInvalidEcuId m2 : 40|1@1+ (1,0) [0|1] "" Vector__XXX
 SG_ EPASTP_a158_amGduFailDuringRecov m2 : 41|1@1+ (1,0) [0|1] "" Vector__XXX
 SG_ EPASTP_a159_exchFlashWordlineTra m2 : 42|1@1+ (1,0) [0|1] "" Vector__XXX
 SG_ EPASTP_a160_rsthCpu1UnexpectedAl m2 : 43|1@1+ (1,0) [0|1] "" Vector__XXX
 SG_ EPASTP_a161_tdaRelayfetjunctionT m2 : 44|1@1+ (1,0) [0|1] "" Vector__XXX
 SG_ EPASTP_a162_tdaBridgefetjunction m2 : 45|1@1+ (1,0) [0|1] "" Vector__XXX
 SG_ EPASTP_a163_tdaPowermoduleTempCh m2 : 46|1@1+ (1,0) [0|1] "" Vector__XXX
 SG_ EPASTP_a164_tdaBattfetjunctionTe m2 : 47|1@1+ (1,0) [0|1] "" Vector__XXX
 SG_ EPASTP_a165_tdaDcbusshuntTempChe m2 : 48|1@1+ (1,0) [0|1] "" Vector__XXX
 SG_ EPASTP_a166_tdaPhasecurrentshunt m2 : 49|1@1+ (1,0) [0|1] "" Vector__XXX
 SG_ EPASTP_a167_iccd1ErrQueueOverflo m2 : 50|1@1+ (1,0) [0|1] "" Vector__XXX
 SG_ EPASTP_a168_c1csInvalidC1App m2 : 51|1@1+ (1,0) [0|1] "" Vector__XXX
 SG_ EPASTP_a169_scpSafetyReset m2 : 52|1@1+ (1,0) [0|1] "" Vector__XXX
 SG_ EPASTP_a170_pmpDcvoltAge m2 : 53|1@1+ (1,0) [0|1] "" Vector__XXX
 SG_ EPASTP_a171_pmpKgvalueAge m2 : 54|1@1+ (1,0) [0|1] "" Vector__XXX
 SG_ EPASTP_a172_pmpElangMotorcurrent m2 : 55|1@1+ (1,0) [0|1] "" Vector__XXX
 SG_ EPASTP_a173_pmpRotorspeedAge m2 : 56|1@1+ (1,0) [0|1] "" Vector__XXX
 SG_ EPASTP_a174_pmpPhasecurrentAge m2 : 57|1@1+ (1,0) [0|1] "" Vector__XXX
 SG_ EPASTP_a175_exchFlashStoredConfi m2 : 58|1@1+ (1,0) [0|1] "" Vector__XXX
 SG_ EPASTP_a176_exchCpu1ExceptionRes m2 : 59|1@1+ (1,0) [0|1] "" Vector__XXX
 SG_ EPASTP_a177_etsrInvalidated m2 : 60|1@1+ (1,0) [0|1] "" Vector__XXX
 SG_ EPASTP_a178_exchWdtException m2 : 61|1@1+ (1,0) [0|1] "" Vector__XXX
 SG_ EPASTP_a179_tedMotorcoilTempChec m2 : 62|1@1+ (1,0) [0|1] "" Vector__XXX
 SG_ EPASTP_a180_dmDeadlineViolationC m2 : 63|1@1+ (1,0) [0|1] "" Vector__XXX
 SG_ EPASTP_a181_dmDeadlineViolationC m3 : 4|1@1+ (1,0) [0|1] "" Vector__XXX
 SG_ EPASTP_a182_mcdInputMia m3 : 5|1@1+ (1,0) [0|1] "" Vector__XXX
 SG_ EPASTP_a183_sbchCommErrSbcToMcu m3 : 6|1@1+ (1,0) [0|1] "" Vector__XXX
 SG_ EPASTP_a184_sbcmCommBufferOverfl m3 : 7|1@1+ (1,0) [0|1] "" Vector__XXX
 SG_ EPASTP_a185_sbcscpQAWatchdogRese m3 : 8|1@1+ (1,0) [0|1] "" Vector__XXX
 SG_ EPASTP_a186_wdhCommBufferOverflo m3 : 9|1@1+ (1,0) [0|1] "" Vector__XXX
 SG_ EPASTP_a187_epmVoltFail m3 : 10|1@1+ (1,0) [0|1] "" Vector__XXX
 SG_ EPASTP_a188_epmCommBufferOverflo m3 : 11|1@1+ (1,0) [0|1] "" Vector__XXX
 SG_ EPASTP_a189_sbchCommErrMcuToSbc m3 : 12|1@1+ (1,0) [0|1] "" Vector__XXX
 SG_ EPASTP_a190_sbchCommBufferOverfl m3 : 13|1@1+ (1,0) [0|1] "" Vector__XXX
 SG_ EPASTP_a191_sbcscpVcp2VucVoltFai m3 : 14|1@1+ (1,0) [0|1] "" Vector__XXX
 SG_ EPASTP_a192_osumC0CsaNearFull m3 : 15|1@1+ (1,0) [0|1] "" Vector__XXX
 SG_ EPASTP_a193_osumC0StackNearFull m3 : 16|1@1+ (1,0) [0|1] "" Vector__XXX
 SG_ EPASTP_a194_amNvdataLoss m3 : 17|1@1+ (1,0) [0|1] "" Vector__XXX
 SG_ EPASTP_a195_imcmCommErrC1 m3 : 18|1@1+ (1,0) [0|1] "" Vector__XXX
 SG_ EPASTP_a196_topEolTasOffsetInval m3 : 19|1@1+ (1,0) [0|1] "" Vector__XXX
 SG_ EPASTP_a197_difpDifactorInvalid m3 : 20|1@1+ (1,0) [0|1] "" Vector__XXX
 SG_ EPASTP_a198_osumC1CsaNearFull m3 : 21|1@1+ (1,0) [0|1] "" Vector__XXX
 SG_ EPASTP_a199_osumC1StackNearFull m3 : 22|1@1+ (1,0) [0|1] "" Vector__XXX
 SG_ EPASTP_a200_ammInputBufferOverfl m3 : 23|1@1+ (1,0) [0|1] "" Vector__XXX
 SG_ EPASTP_a201_ammOutputBufferOverf m3 : 24|1@1+ (1,0) [0|1] "" Vector__XXX
 SG_ EPASTP_a202_ohnvmpStoredOffsetLo m3 : 25|1@1+ (1,0) [0|1] "" Vector__XXX
 SG_ EPASTP_a203_ctcInterfaceErr m3 : 26|1@1+ (1,0) [0|1] "" Vector__XXX
 SG_ EPASTP_a204_fdpPrevTrqErr m3 : 27|1@1+ (1,0) [0|1] "" Vector__XXX
 SG_ EPASTP_a205_fdrOclFail m3 : 28|1@1+ (1,0) [0|1] "" Vector__XXX
 SG_ EPASTP_a206_fdrOclPartialBlockin m3 : 29|1@1+ (1,0) [0|1] "" Vector__XXX
 SG_ EPASTP_a207_fdrOclFreezing m3 : 30|1@1+ (1,0) [0|1] "" Vector__XXX
 SG_ EPASTP_a208_fdrLowSeverityBlocki m3 : 31|1@1+ (1,0) [0|1] "" Vector__XXX
 SG_ EPASTP_a209_fdrLowSeverityFreezi m3 : 32|1@1+ (1,0) [0|1] "" Vector__XXX
 SG_ EPASTP_a210_fdrTotalBlocking m3 : 33|1@1+ (1,0) [0|1] "" Vector__XXX
 SG_ EPASTP_a211_frmInternalErr m3 : 34|1@1+ (1,0) [0|1] "" Vector__XXX
 SG_ EPASTP_a212_frmDataLost m3 : 35|1@1+ (1,0) [0|1] "" Vector__XXX
 SG_ EPASTP_a213_frmHighFrictionDetec m3 : 36|1@1+ (1,0) [0|1] "" Vector__XXX
 SG_ EPASTP_a214_velInterfaceErr m3 : 37|1@1+ (1,0) [0|1] "" Vector__XXX
 SG_ EPASTP_a215_vsgSafeViolErr m3 : 38|1@1+ (1,0) [0|1] "" Vector__XXX
 SG_ EPASTP_a216_isdgImproperShutdown m3 : 39|1@1+ (1,0) [0|1] "" Vector__XXX
 SG_ EPASTP_a217_msdMasterSilentErr m3 : 40|1@1+ (1,0) [0|1] "" Vector__XXX
 SG_ EPASTP_a218_aadApplicationStateE m3 : 41|1@1+ (1,0) [0|1] "" Vector__XXX
 SG_ EPASTP_a219_frhFastRestartFailed m3 : 42|1@1+ (1,0) [0|1] "" Vector__XXX
 SG_ EPASTP_a221_apsCntError m3 : 43|1@1+ (1,0) [0|1] "" Vector__XXX
 SG_ EPASTP_a222_apsCsError m3 : 44|1@1+ (1,0) [0|1] "" Vector__XXX
 SG_ EPASTP_a223_apsMia m3 : 45|1@1+ (1,0) [0|1] "" Vector__XXX
 SG_ EPASTP_a224_dasCntError m3 : 46|1@1+ (1,0) [0|1] "" Vector__XXX
 SG_ EPASTP_a225_dasCsError m3 : 47|1@1+ (1,0) [0|1] "" Vector__XXX
 SG_ EPASTP_a226_dasMia m3 : 48|1@1+ (1,0) [0|1] "" Vector__XXX
 SG_ EPASTP_a227_dirTorqueCntError m3 : 49|1@1+ (1,0) [0|1] "" Vector__XXX
 SG_ EPASTP_a228_dirTorqueCsError m3 : 50|1@1+ (1,0) [0|1] "" Vector__XXX
 SG_ EPASTP_a229_dirTorqueMia m3 : 51|1@1+ (1,0) [0|1] "" Vector__XXX
 SG_ EPASTP_a230_diSpdCntError m3 : 52|1@1+ (1,0) [0|1] "" Vector__XXX
 SG_ EPASTP_a231_diSpdCsError m3 : 53|1@1+ (1,0) [0|1] "" Vector__XXX
 SG_ EPASTP_a232_diSpdMia m3 : 54|1@1+ (1,0) [0|1] "" Vector__XXX
 SG_ EPASTP_a233_ecu2StatCntError m3 : 55|1@1+ (1,0) [0|1] "" Vector__XXX
 SG_ EPASTP_a234_ecu2StatCsError m3 : 56|1@1+ (1,0) [0|1] "" Vector__XXX
 SG_ EPASTP_a235_ecu2StatMia m3 : 57|1@1+ (1,0) [0|1] "" Vector__XXX
 SG_ EPASTP_a236_espWrCntError m3 : 58|1@1+ (1,0) [0|1] "" Vector__XXX
 SG_ EPASTP_a237_espWrCsError m3 : 59|1@1+ (1,0) [0|1] "" Vector__XXX
 SG_ EPASTP_a238_espWrMia m3 : 60|1@1+ (1,0) [0|1] "" Vector__XXX
 SG_ EPASTP_a239_espWsCntError m3 : 61|1@1+ (1,0) [0|1] "" Vector__XXX
 SG_ EPASTP_a240_espWsCsError m3 : 62|1@1+ (1,0) [0|1] "" Vector__XXX
 SG_ EPASTP_a241_espWsMia m3 : 63|1@1+ (1,0) [0|1] "" Vector__XXX
 SG_ EPASTP_a242_gtwConfigMia m4 : 4|1@1+ (1,0) [0|1] "" Vector__XXX
 SG_ EPASTP_a243_rcmCntError m4 : 5|1@1+ (1,0) [0|1] "" Vector__XXX
 SG_ EPASTP_a244_rcmCsError m4 : 6|1@1+ (1,0) [0|1] "" Vector__XXX
 SG_ EPASTP_a245_rcmMia m4 : 7|1@1+ (1,0) [0|1] "" Vector__XXX
 SG_ EPASTP_a246_sccmCntError m4 : 8|1@1+ (1,0) [0|1] "" Vector__XXX
 SG_ EPASTP_a247_sccmCsError m4 : 9|1@1+ (1,0) [0|1] "" Vector__XXX
 SG_ EPASTP_a248_sccmMia m4 : 10|1@1+ (1,0) [0|1] "" Vector__XXX
 SG_ EPASTP_a249_uiTuneReqCntError m4 : 11|1@1+ (1,0) [0|1] "" Vector__XXX
 SG_ EPASTP_a250_uiTuneReqCsError m4 : 12|1@1+ (1,0) [0|1] "" Vector__XXX
 SG_ EPASTP_a251_uiTuneReqMia m4 : 13|1@1+ (1,0) [0|1] "" Vector__XXX
 SG_ EPASTP_a252_vcFrontCntError m4 : 14|1@1+ (1,0) [0|1] "" Vector__XXX
 SG_ EPASTP_a253_vcFrontCsError m4 : 15|1@1+ (1,0) [0|1] "" Vector__XXX
 SG_ EPASTP_a254_vcFrontMia m4 : 16|1@1+ (1,0) [0|1] "" Vector__XXX
 SG_ EPASTP_a255_pmState2Mia m4 : 17|1@1+ (1,0) [0|1] "" Vector__XXX
 SG_ EPASTP_a256_dcvmOverVolt m4 : 18|1@1+ (1,0) [0|1] "" Vector__XXX
 SG_ EPASTP_a257_dcvmUnderVolt m4 : 19|1@1+ (1,0) [0|1] "" Vector__XXX
 SG_ EPASTP_a258_pspInvalidProjectPar m4 : 20|1@1+ (1,0) [0|1] "" Vector__XXX
 SG_ EPASTP_a259_scoCanBusOff m4 : 21|1@1+ (1,0) [0|1] "" Vector__XXX
 SG_ EPASTP_a260_scoPrivateBusOff m4 : 22|1@1+ (1,0) [0|1] "" Vector__XXX
 SG_ EPASTP_a261_sccmStatusError m4 : 23|1@1+ (1,0) [0|1] "" Vector__XXX
 SG_ EPASTP_a262_yawRateStatus m4 : 24|1@1+ (1,0) [0|1] "" Vector__XXX
 SG_ EPASTP_a263_espWsStatus m4 : 25|1@1+ (1,0) [0|1] "" Vector__XXX
 SG_ EPASTP_a264_assistTorqueLimited m4 : 26|1@1+ (1,0) [0|1] "" Vector__XXX
 SG_ EPASTP_a265_overheatProtect m4 : 27|1@1+ (1,0) [0|1] "" Vector__XXX
 SG_ EPASTP_a266_overloadProtect m4 : 28|1@1+ (1,0) [0|1] "" Vector__XXX
 SG_ EPASTP_a267_safeSpeedAssist m4 : 29|1@1+ (1,0) [0|1] "" Vector__XXX
 SG_ EPASTP_a268_eacCancelled m4 : 30|1@1+ (1,0) [0|1] "" Vector__XXX
 SG_ EPASTP_a269_assistTorqueDisabled m4 : 31|1@1+ (1,0) [0|1] "" Vector__XXX
 SG_ EPASTP_a270_oscillationCompTrqLi m4 : 32|1@1+ (1,0) [0|1] "" Vector__XXX

BO_ 1428 EPASTS_alertLog: 8 EPASTS
 SG_ EPASTS_alertID M : 0|9@1+ (1,0) [0|511] "" Vector__XXX
 SG_ EPASTS_alertState : 15|1@1+ (1,0) [0|1] "" Vector__XXX
 SG_ EPASTS_a001_debugInfo m1 : 16|48@1+ (1,0) [0|281474976710655] "" Vector__XXX
 SG_ EPASTS_a002_debugInfo m2 : 16|48@1+ (1,0) [0|281474976710655] "" Vector__XXX
 SG_ EPASTS_a003_debugInfo m3 : 16|48@1+ (1,0) [0|281474976710655] "" Vector__XXX
 SG_ EPASTS_a004_debugInfo m4 : 16|48@1+ (1,0) [0|281474976710655] "" Vector__XXX
 SG_ EPASTS_a005_debugInfo m5 : 16|48@1+ (1,0) [0|281474976710655] "" Vector__XXX
 SG_ EPASTS_a006_debugInfo m6 : 16|48@1+ (1,0) [0|281474976710655] "" Vector__XXX
 SG_ EPASTS_a007_debugInfo m7 : 16|48@1+ (1,0) [0|281474976710655] "" Vector__XXX
 SG_ EPASTS_a009_debugInfo m9 : 16|48@1+ (1,0) [0|281474976710655] "" Vector__XXX
 SG_ EPASTS_a010_debugInfo m10 : 16|48@1+ (1,0) [0|281474976710655] "" Vector__XXX
 SG_ EPASTS_a011_debugInfo m11 : 16|48@1+ (1,0) [0|281474976710655] "" Vector__XXX
 SG_ EPASTS_a012_debugInfo m12 : 16|48@1+ (1,0) [0|281474976710655] "" Vector__XXX
 SG_ EPASTS_a013_debugInfo m13 : 16|48@1+ (1,0) [0|281474976710655] "" Vector__XXX
 SG_ EPASTS_a014_debugInfo m14 : 16|48@1+ (1,0) [0|281474976710655] "" Vector__XXX
 SG_ EPASTS_a015_debugInfo m15 : 16|48@1+ (1,0) [0|281474976710655] "" Vector__XXX
 SG_ EPASTS_a016_debugInfo m16 : 16|48@1+ (1,0) [0|281474976710655] "" Vector__XXX
 SG_ EPASTS_a017_debugInfo m17 : 16|48@1+ (1,0) [0|281474976710655] "" Vector__XXX
 SG_ EPASTS_a018_debugInfo m18 : 16|48@1+ (1,0) [0|281474976710655] "" Vector__XXX
 SG_ EPASTS_a019_debugInfo m19 : 16|48@1+ (1,0) [0|281474976710655] "" Vector__XXX
 SG_ EPASTS_a020_debugInfo m20 : 16|48@1+ (1,0) [0|281474976710655] "" Vector__XXX
 SG_ EPASTS_a021_debugInfo m21 : 16|48@1+ (1,0) [0|281474976710655] "" Vector__XXX
 SG_ EPASTS_a022_debugInfo m22 : 16|48@1+ (1,0) [0|281474976710655] "" Vector__XXX
 SG_ EPASTS_a023_debugInfo m23 : 16|48@1+ (1,0) [0|281474976710655] "" Vector__XXX
 SG_ EPASTS_a024_debugInfo m24 : 16|48@1+ (1,0) [0|281474976710655] "" Vector__XXX
 SG_ EPASTS_a025_debugInfo m25 : 16|48@1+ (1,0) [0|281474976710655] "" Vector__XXX
 SG_ EPASTS_a026_debugInfo m26 : 16|48@1+ (1,0) [0|281474976710655] "" Vector__XXX
 SG_ EPASTS_a027_debugInfo m27 : 16|48@1+ (1,0) [0|281474976710655] "" Vector__XXX
 SG_ EPASTS_a028_debugInfo m28 : 16|48@1+ (1,0) [0|281474976710655] "" Vector__XXX
 SG_ EPASTS_a029_debugInfo m29 : 16|48@1+ (1,0) [0|281474976710655] "" Vector__XXX
 SG_ EPASTS_a030_debugInfo m30 : 16|48@1+ (1,0) [0|281474976710655] "" Vector__XXX
 SG_ EPASTS_a031_debugInfo m31 : 16|48@1+ (1,0) [0|281474976710655] "" Vector__XXX
 SG_ EPASTS_a032_debugInfo m32 : 16|48@1+ (1,0) [0|281474976710655] "" Vector__XXX
 SG_ EPASTS_a033_debugInfo m33 : 16|48@1+ (1,0) [0|281474976710655] "" Vector__XXX
 SG_ EPASTS_a034_debugInfo m34 : 16|48@1+ (1,0) [0|281474976710655] "" Vector__XXX
 SG_ EPASTS_a035_debugInfo m35 : 16|48@1+ (1,0) [0|281474976710655] "" Vector__XXX
 SG_ EPASTS_a036_debugInfo m36 : 16|48@1+ (1,0) [0|281474976710655] "" Vector__XXX
 SG_ EPASTS_a037_debugInfo m37 : 16|48@1+ (1,0) [0|281474976710655] "" Vector__XXX
 SG_ EPASTS_a038_debugInfo m38 : 16|48@1+ (1,0) [0|281474976710655] "" Vector__XXX
 SG_ EPASTS_a039_debugInfo m39 : 16|48@1+ (1,0) [0|281474976710655] "" Vector__XXX
 SG_ EPASTS_a040_debugInfo m40 : 16|48@1+ (1,0) [0|281474976710655] "" Vector__XXX
 SG_ EPASTS_a041_debugInfo m41 : 16|48@1+ (1,0) [0|281474976710655] "" Vector__XXX
 SG_ EPASTS_a042_debugInfo m42 : 16|48@1+ (1,0) [0|281474976710655] "" Vector__XXX
 SG_ EPASTS_a043_debugInfo m43 : 16|48@1+ (1,0) [0|281474976710655] "" Vector__XXX
 SG_ EPASTS_a044_debugInfo m44 : 16|48@1+ (1,0) [0|281474976710655] "" Vector__XXX
 SG_ EPASTS_a045_debugInfo m45 : 16|48@1+ (1,0) [0|281474976710655] "" Vector__XXX
 SG_ EPASTS_a046_debugInfo m46 : 16|48@1+ (1,0) [0|281474976710655] "" Vector__XXX
 SG_ EPASTS_a047_debugInfo m47 : 16|48@1+ (1,0) [0|281474976710655] "" Vector__XXX
 SG_ EPASTS_a048_debugInfo m48 : 16|48@1+ (1,0) [0|281474976710655] "" Vector__XXX
 SG_ EPASTS_a049_debugInfo m49 : 16|48@1+ (1,0) [0|281474976710655] "" Vector__XXX
 SG_ EPASTS_a050_debugInfo m50 : 16|48@1+ (1,0) [0|281474976710655] "" Vector__XXX
 SG_ EPASTS_a051_debugInfo m51 : 16|48@1+ (1,0) [0|281474976710655] "" Vector__XXX
 SG_ EPASTS_a052_debugInfo m52 : 16|48@1+ (1,0) [0|281474976710655] "" Vector__XXX
 SG_ EPASTS_a053_debugInfo m53 : 16|48@1+ (1,0) [0|281474976710655] "" Vector__XXX
 SG_ EPASTS_a054_debugInfo m54 : 16|48@1+ (1,0) [0|281474976710655] "" Vector__XXX
 SG_ EPASTS_a055_debugInfo m55 : 16|48@1+ (1,0) [0|281474976710655] "" Vector__XXX
 SG_ EPASTS_a056_debugInfo m56 : 16|48@1+ (1,0) [0|281474976710655] "" Vector__XXX
 SG_ EPASTS_a057_debugInfo m57 : 16|48@1+ (1,0) [0|281474976710655] "" Vector__XXX
 SG_ EPASTS_a058_debugInfo m58 : 16|48@1+ (1,0) [0|281474976710655] "" Vector__XXX
 SG_ EPASTS_a059_debugInfo m59 : 16|48@1+ (1,0) [0|281474976710655] "" Vector__XXX
 SG_ EPASTS_a060_debugInfo m60 : 16|48@1+ (1,0) [0|281474976710655] "" Vector__XXX
 SG_ EPASTS_a061_debugInfo m61 : 16|48@1+ (1,0) [0|281474976710655] "" Vector__XXX
 SG_ EPASTS_a062_debugInfo m62 : 16|48@1+ (1,0) [0|281474976710655] "" Vector__XXX
 SG_ EPASTS_a063_debugInfo m63 : 16|48@1+ (1,0) [0|281474976710655] "" Vector__XXX
 SG_ EPASTS_a064_debugInfo m64 : 16|48@1+ (1,0) [0|281474976710655] "" Vector__XXX
 SG_ EPASTS_a065_debugInfo m65 : 16|48@1+ (1,0) [0|281474976710655] "" Vector__XXX
 SG_ EPASTS_a066_debugInfo m66 : 16|48@1+ (1,0) [0|281474976710655] "" Vector__XXX
 SG_ EPASTS_a067_debugInfo m67 : 16|48@1+ (1,0) [0|281474976710655] "" Vector__XXX
 SG_ EPASTS_a068_debugInfo m68 : 16|48@1+ (1,0) [0|281474976710655] "" Vector__XXX
 SG_ EPASTS_a069_debugInfo m69 : 16|48@1+ (1,0) [0|281474976710655] "" Vector__XXX
 SG_ EPASTS_a070_debugInfo m70 : 16|48@1+ (1,0) [0|281474976710655] "" Vector__XXX
 SG_ EPASTS_a071_debugInfo m71 : 16|48@1+ (1,0) [0|281474976710655] "" Vector__XXX
 SG_ EPASTS_a072_debugInfo m72 : 16|48@1+ (1,0) [0|281474976710655] "" Vector__XXX
 SG_ EPASTS_a073_debugInfo m73 : 16|48@1+ (1,0) [0|281474976710655] "" Vector__XXX
 SG_ EPASTS_a074_debugInfo m74 : 16|48@1+ (1,0) [0|281474976710655] "" Vector__XXX
 SG_ EPASTS_a075_debugInfo m75 : 16|48@1+ (1,0) [0|281474976710655] "" Vector__XXX
 SG_ EPASTS_a076_debugInfo m76 : 16|48@1+ (1,0) [0|281474976710655] "" Vector__XXX
 SG_ EPASTS_a077_debugInfo m77 : 16|48@1+ (1,0) [0|281474976710655] "" Vector__XXX
 SG_ EPASTS_a078_debugInfo m78 : 16|48@1+ (1,0) [0|281474976710655] "" Vector__XXX
 SG_ EPASTS_a079_debugInfo m79 : 16|48@1+ (1,0) [0|281474976710655] "" Vector__XXX
 SG_ EPASTS_a080_debugInfo m80 : 16|48@1+ (1,0) [0|281474976710655] "" Vector__XXX
 SG_ EPASTS_a081_debugInfo m81 : 16|48@1+ (1,0) [0|281474976710655] "" Vector__XXX
 SG_ EPASTS_a082_debugInfo m82 : 16|48@1+ (1,0) [0|281474976710655] "" Vector__XXX
 SG_ EPASTS_a083_debugInfo m83 : 16|48@1+ (1,0) [0|281474976710655] "" Vector__XXX
 SG_ EPASTS_a084_debugInfo m84 : 16|48@1+ (1,0) [0|281474976710655] "" Vector__XXX
 SG_ EPASTS_a085_debugInfo m85 : 16|48@1+ (1,0) [0|281474976710655] "" Vector__XXX
 SG_ EPASTS_a086_debugInfo m86 : 16|48@1+ (1,0) [0|281474976710655] "" Vector__XXX
 SG_ EPASTS_a087_debugInfo m87 : 16|48@1+ (1,0) [0|281474976710655] "" Vector__XXX
 SG_ EPASTS_a088_debugInfo m88 : 16|48@1+ (1,0) [0|281474976710655] "" Vector__XXX
 SG_ EPASTS_a089_debugInfo m89 : 16|48@1+ (1,0) [0|281474976710655] "" Vector__XXX
 SG_ EPASTS_a090_debugInfo m90 : 16|48@1+ (1,0) [0|281474976710655] "" Vector__XXX
 SG_ EPASTS_a091_debugInfo m91 : 16|48@1+ (1,0) [0|281474976710655] "" Vector__XXX
 SG_ EPASTS_a092_debugInfo m92 : 16|48@1+ (1,0) [0|281474976710655] "" Vector__XXX
 SG_ EPASTS_a093_debugInfo m93 : 16|48@1+ (1,0) [0|281474976710655] "" Vector__XXX
 SG_ EPASTS_a094_debugInfo m94 : 16|48@1+ (1,0) [0|281474976710655] "" Vector__XXX
 SG_ EPASTS_a095_debugInfo m95 : 16|48@1+ (1,0) [0|281474976710655] "" Vector__XXX
 SG_ EPASTS_a096_debugInfo m96 : 16|48@1+ (1,0) [0|281474976710655] "" Vector__XXX
 SG_ EPASTS_a097_debugInfo m97 : 16|48@1+ (1,0) [0|281474976710655] "" Vector__XXX
 SG_ EPASTS_a098_debugInfo m98 : 16|48@1+ (1,0) [0|281474976710655] "" Vector__XXX
 SG_ EPASTS_a099_debugInfo m99 : 16|48@1+ (1,0) [0|281474976710655] "" Vector__XXX
 SG_ EPASTS_a100_debugInfo m100 : 16|48@1+ (1,0) [0|281474976710655] "" Vector__XXX
 SG_ EPASTS_a101_debugInfo m101 : 16|48@1+ (1,0) [0|281474976710655] "" Vector__XXX
 SG_ EPASTS_a102_debugInfo m102 : 16|48@1+ (1,0) [0|281474976710655] "" Vector__XXX
 SG_ EPASTS_a103_debugInfo m103 : 16|48@1+ (1,0) [0|281474976710655] "" Vector__XXX
 SG_ EPASTS_a104_debugInfo m104 : 16|48@1+ (1,0) [0|281474976710655] "" Vector__XXX
 SG_ EPASTS_a105_debugInfo m105 : 16|48@1+ (1,0) [0|281474976710655] "" Vector__XXX
 SG_ EPASTS_a106_debugInfo m106 : 16|48@1+ (1,0) [0|281474976710655] "" Vector__XXX
 SG_ EPASTS_a107_debugInfo m107 : 16|48@1+ (1,0) [0|281474976710655] "" Vector__XXX
 SG_ EPASTS_a108_debugInfo m108 : 16|48@1+ (1,0) [0|281474976710655] "" Vector__XXX
 SG_ EPASTS_a109_debugInfo m109 : 16|48@1+ (1,0) [0|281474976710655] "" Vector__XXX
 SG_ EPASTS_a110_debugInfo m110 : 16|48@1+ (1,0) [0|281474976710655] "" Vector__XXX
 SG_ EPASTS_a111_debugInfo m111 : 16|48@1+ (1,0) [0|281474976710655] "" Vector__XXX
 SG_ EPASTS_a112_debugInfo m112 : 16|48@1+ (1,0) [0|281474976710655] "" Vector__XXX
 SG_ EPASTS_a113_debugInfo m113 : 16|48@1+ (1,0) [0|281474976710655] "" Vector__XXX
 SG_ EPASTS_a114_debugInfo m114 : 16|48@1+ (1,0) [0|281474976710655] "" Vector__XXX
 SG_ EPASTS_a115_debugInfo m115 : 16|48@1+ (1,0) [0|281474976710655] "" Vector__XXX
 SG_ EPASTS_a116_debugInfo m116 : 16|48@1+ (1,0) [0|281474976710655] "" Vector__XXX
 SG_ EPASTS_a117_debugInfo m117 : 16|48@1+ (1,0) [0|281474976710655] "" Vector__XXX
 SG_ EPASTS_a118_debugInfo m118 : 16|48@1+ (1,0) [0|281474976710655] "" Vector__XXX
 SG_ EPASTS_a119_debugInfo m119 : 16|48@1+ (1,0) [0|281474976710655] "" Vector__XXX
 SG_ EPASTS_a120_debugInfo m120 : 16|48@1+ (1,0) [0|281474976710655] "" Vector__XXX
 SG_ EPASTS_a121_debugInfo m121 : 16|48@1+ (1,0) [0|281474976710655] "" Vector__XXX
 SG_ EPASTS_a122_debugInfo m122 : 16|48@1+ (1,0) [0|281474976710655] "" Vector__XXX
 SG_ EPASTS_a123_debugInfo m123 : 16|48@1+ (1,0) [0|281474976710655] "" Vector__XXX
 SG_ EPASTS_a124_debugInfo m124 : 16|48@1+ (1,0) [0|281474976710655] "" Vector__XXX
 SG_ EPASTS_a125_debugInfo m125 : 16|48@1+ (1,0) [0|281474976710655] "" Vector__XXX
 SG_ EPASTS_a126_debugInfo m126 : 16|48@1+ (1,0) [0|281474976710655] "" Vector__XXX
 SG_ EPASTS_a127_debugInfo m127 : 16|48@1+ (1,0) [0|281474976710655] "" Vector__XXX
 SG_ EPASTS_a128_debugInfo m128 : 16|48@1+ (1,0) [0|281474976710655] "" Vector__XXX
 SG_ EPASTS_a129_debugInfo m129 : 16|48@1+ (1,0) [0|281474976710655] "" Vector__XXX
 SG_ EPASTS_a130_debugInfo m130 : 16|48@1+ (1,0) [0|281474976710655] "" Vector__XXX
 SG_ EPASTS_a131_debugInfo m131 : 16|48@1+ (1,0) [0|281474976710655] "" Vector__XXX
 SG_ EPASTS_a132_debugInfo m132 : 16|48@1+ (1,0) [0|281474976710655] "" Vector__XXX
 SG_ EPASTS_a133_debugInfo m133 : 16|48@1+ (1,0) [0|281474976710655] "" Vector__XXX
 SG_ EPASTS_a134_debugInfo m134 : 16|48@1+ (1,0) [0|281474976710655] "" Vector__XXX
 SG_ EPASTS_a135_debugInfo m135 : 16|48@1+ (1,0) [0|281474976710655] "" Vector__XXX
 SG_ EPASTS_a136_debugInfo m136 : 16|48@1+ (1,0) [0|281474976710655] "" Vector__XXX
 SG_ EPASTS_a137_debugInfo m137 : 16|48@1+ (1,0) [0|281474976710655] "" Vector__XXX
 SG_ EPASTS_a138_debugInfo m138 : 16|48@1+ (1,0) [0|281474976710655] "" Vector__XXX
 SG_ EPASTS_a139_debugInfo m139 : 16|48@1+ (1,0) [0|281474976710655] "" Vector__XXX
 SG_ EPASTS_a140_debugInfo m140 : 16|48@1+ (1,0) [0|281474976710655] "" Vector__XXX
 SG_ EPASTS_a141_debugInfo m141 : 16|48@1+ (1,0) [0|281474976710655] "" Vector__XXX
 SG_ EPASTS_a142_debugInfo m142 : 16|48@1+ (1,0) [0|281474976710655] "" Vector__XXX
 SG_ EPASTS_a143_debugInfo m143 : 16|48@1+ (1,0) [0|281474976710655] "" Vector__XXX
 SG_ EPASTS_a144_debugInfo m144 : 16|48@1+ (1,0) [0|281474976710655] "" Vector__XXX
 SG_ EPASTS_a145_debugInfo m145 : 16|48@1+ (1,0) [0|281474976710655] "" Vector__XXX
 SG_ EPASTS_a146_debugInfo m146 : 16|48@1+ (1,0) [0|281474976710655] "" Vector__XXX
 SG_ EPASTS_a147_debugInfo m147 : 16|48@1+ (1,0) [0|281474976710655] "" Vector__XXX
 SG_ EPASTS_a148_debugInfo m148 : 16|48@1+ (1,0) [0|281474976710655] "" Vector__XXX
 SG_ EPASTS_a149_debugInfo m149 : 16|48@1+ (1,0) [0|281474976710655] "" Vector__XXX
 SG_ EPASTS_a150_debugInfo m150 : 16|48@1+ (1,0) [0|281474976710655] "" Vector__XXX
 SG_ EPASTS_a152_debugInfo m152 : 16|48@1+ (1,0) [0|281474976710655] "" Vector__XXX
 SG_ EPASTS_a153_debugInfo m153 : 16|48@1+ (1,0) [0|281474976710655] "" Vector__XXX
 SG_ EPASTS_a154_debugInfo m154 : 16|48@1+ (1,0) [0|281474976710655] "" Vector__XXX
 SG_ EPASTS_a155_debugInfo m155 : 16|48@1+ (1,0) [0|281474976710655] "" Vector__XXX
 SG_ EPASTS_a156_debugInfo m156 : 16|48@1+ (1,0) [0|281474976710655] "" Vector__XXX
 SG_ EPASTS_a157_debugInfo m157 : 16|48@1+ (1,0) [0|281474976710655] "" Vector__XXX
 SG_ EPASTS_a158_debugInfo m158 : 16|48@1+ (1,0) [0|281474976710655] "" Vector__XXX
 SG_ EPASTS_a159_debugInfo m159 : 16|48@1+ (1,0) [0|281474976710655] "" Vector__XXX
 SG_ EPASTS_a160_debugInfo m160 : 16|48@1+ (1,0) [0|281474976710655] "" Vector__XXX
 SG_ EPASTS_a161_debugInfo m161 : 16|48@1+ (1,0) [0|281474976710655] "" Vector__XXX
 SG_ EPASTS_a162_debugInfo m162 : 16|48@1+ (1,0) [0|281474976710655] "" Vector__XXX
 SG_ EPASTS_a163_debugInfo m163 : 16|48@1+ (1,0) [0|281474976710655] "" Vector__XXX
 SG_ EPASTS_a164_debugInfo m164 : 16|48@1+ (1,0) [0|281474976710655] "" Vector__XXX
 SG_ EPASTS_a165_debugInfo m165 : 16|48@1+ (1,0) [0|281474976710655] "" Vector__XXX
 SG_ EPASTS_a166_debugInfo m166 : 16|48@1+ (1,0) [0|281474976710655] "" Vector__XXX
 SG_ EPASTS_a167_debugInfo m167 : 16|48@1+ (1,0) [0|281474976710655] "" Vector__XXX
 SG_ EPASTS_a168_debugInfo m168 : 16|48@1+ (1,0) [0|281474976710655] "" Vector__XXX
 SG_ EPASTS_a169_debugInfo m169 : 16|48@1+ (1,0) [0|281474976710655] "" Vector__XXX
 SG_ EPASTS_a170_debugInfo m170 : 16|48@1+ (1,0) [0|281474976710655] "" Vector__XXX
 SG_ EPASTS_a171_debugInfo m171 : 16|48@1+ (1,0) [0|281474976710655] "" Vector__XXX
 SG_ EPASTS_a172_debugInfo m172 : 16|48@1+ (1,0) [0|281474976710655] "" Vector__XXX
 SG_ EPASTS_a173_debugInfo m173 : 16|48@1+ (1,0) [0|281474976710655] "" Vector__XXX
 SG_ EPASTS_a174_debugInfo m174 : 16|48@1+ (1,0) [0|281474976710655] "" Vector__XXX
 SG_ EPASTS_a175_debugInfo m175 : 16|48@1+ (1,0) [0|281474976710655] "" Vector__XXX
 SG_ EPASTS_a176_debugInfo m176 : 16|48@1+ (1,0) [0|281474976710655] "" Vector__XXX
 SG_ EPASTS_a177_debugInfo m177 : 16|48@1+ (1,0) [0|281474976710655] "" Vector__XXX
 SG_ EPASTS_a178_debugInfo m178 : 16|48@1+ (1,0) [0|281474976710655] "" Vector__XXX
 SG_ EPASTS_a179_debugInfo m179 : 16|48@1+ (1,0) [0|281474976710655] "" Vector__XXX
 SG_ EPASTS_a180_debugInfo m180 : 16|48@1+ (1,0) [0|281474976710655] "" Vector__XXX
 SG_ EPASTS_a181_debugInfo m181 : 16|48@1+ (1,0) [0|281474976710655] "" Vector__XXX
 SG_ EPASTS_a182_debugInfo m182 : 16|48@1+ (1,0) [0|281474976710655] "" Vector__XXX
 SG_ EPASTS_a183_debugInfo m183 : 16|48@1+ (1,0) [0|281474976710655] "" Vector__XXX
 SG_ EPASTS_a184_debugInfo m184 : 16|48@1+ (1,0) [0|281474976710655] "" Vector__XXX
 SG_ EPASTS_a185_debugInfo m185 : 16|48@1+ (1,0) [0|281474976710655] "" Vector__XXX
 SG_ EPASTS_a186_debugInfo m186 : 16|48@1+ (1,0) [0|281474976710655] "" Vector__XXX
 SG_ EPASTS_a188_debugInfo m188 : 16|48@1+ (1,0) [0|281474976710655] "" Vector__XXX
 SG_ EPASTS_a189_debugInfo m189 : 16|48@1+ (1,0) [0|281474976710655] "" Vector__XXX
 SG_ EPASTS_a190_debugInfo m190 : 16|48@1+ (1,0) [0|281474976710655] "" Vector__XXX
 SG_ EPASTS_a191_debugInfo m191 : 16|48@1+ (1,0) [0|281474976710655] "" Vector__XXX
 SG_ EPASTS_a192_debugInfo m192 : 16|48@1+ (1,0) [0|281474976710655] "" Vector__XXX
 SG_ EPASTS_a193_debugInfo m193 : 16|48@1+ (1,0) [0|281474976710655] "" Vector__XXX
 SG_ EPASTS_a194_debugInfo m194 : 16|48@1+ (1,0) [0|281474976710655] "" Vector__XXX
 SG_ EPASTS_a195_debugInfo m195 : 16|48@1+ (1,0) [0|281474976710655] "" Vector__XXX
 SG_ EPASTS_a196_debugInfo m196 : 16|48@1+ (1,0) [0|281474976710655] "" Vector__XXX
 SG_ EPASTS_a197_debugInfo m197 : 16|48@1+ (1,0) [0|281474976710655] "" Vector__XXX
 SG_ EPASTS_a198_debugInfo m198 : 16|48@1+ (1,0) [0|281474976710655] "" Vector__XXX
 SG_ EPASTS_a199_debugInfo m199 : 16|48@1+ (1,0) [0|281474976710655] "" Vector__XXX
 SG_ EPASTS_a200_debugInfo m200 : 16|48@1+ (1,0) [0|281474976710655] "" Vector__XXX
 SG_ EPASTS_a201_debugInfo m201 : 16|48@1+ (1,0) [0|281474976710655] "" Vector__XXX
 SG_ EPASTS_a202_debugInfo m202 : 16|48@1+ (1,0) [0|281474976710655] "" Vector__XXX
 SG_ EPASTS_a203_debugInfo m203 : 16|48@1+ (1,0) [0|281474976710655] "" Vector__XXX
 SG_ EPASTS_a204_debugInfo m204 : 16|48@1+ (1,0) [0|281474976710655] "" Vector__XXX
 SG_ EPASTS_a205_debugInfo m205 : 16|48@1+ (1,0) [0|281474976710655] "" Vector__XXX
 SG_ EPASTS_a206_debugInfo m206 : 16|48@1+ (1,0) [0|281474976710655] "" Vector__XXX
 SG_ EPASTS_a207_debugInfo m207 : 16|48@1+ (1,0) [0|281474976710655] "" Vector__XXX
 SG_ EPASTS_a208_debugInfo m208 : 16|48@1+ (1,0) [0|281474976710655] "" Vector__XXX
 SG_ EPASTS_a209_debugInfo m209 : 16|48@1+ (1,0) [0|281474976710655] "" Vector__XXX
 SG_ EPASTS_a210_debugInfo m210 : 16|48@1+ (1,0) [0|281474976710655] "" Vector__XXX
 SG_ EPASTS_a211_debugInfo m211 : 16|48@1+ (1,0) [0|281474976710655] "" Vector__XXX
 SG_ EPASTS_a212_debugInfo m212 : 16|48@1+ (1,0) [0|281474976710655] "" Vector__XXX
 SG_ EPASTS_a213_debugInfo m213 : 16|48@1+ (1,0) [0|281474976710655] "" Vector__XXX
 SG_ EPASTS_a214_debugInfo m214 : 16|48@1+ (1,0) [0|281474976710655] "" Vector__XXX
 SG_ EPASTS_a215_debugInfo m215 : 16|48@1+ (1,0) [0|281474976710655] "" Vector__XXX
 SG_ EPASTS_a216_debugInfo m216 : 16|48@1+ (1,0) [0|281474976710655] "" Vector__XXX
 SG_ EPASTS_a217_debugInfo m217 : 16|48@1+ (1,0) [0|281474976710655] "" Vector__XXX
 SG_ EPASTS_a218_debugInfo m218 : 16|48@1+ (1,0) [0|281474976710655] "" Vector__XXX
 SG_ EPASTS_a219_debugInfo m219 : 16|48@1+ (1,0) [0|281474976710655] "" Vector__XXX
 SG_ EPASTS_a220_debugInfo m220 : 16|48@1+ (1,0) [0|281474976710655] "" Vector__XXX
 SG_ EPASTS_a221_debugInfo m221 : 16|48@1+ (1,0) [0|281474976710655] "" Vector__XXX
 SG_ EPASTS_a222_debugInfo m222 : 16|48@1+ (1,0) [0|281474976710655] "" Vector__XXX
 SG_ EPASTS_a223_debugInfo m223 : 16|48@1+ (1,0) [0|281474976710655] "" Vector__XXX
 SG_ EPASTS_a224_debugInfo m224 : 16|48@1+ (1,0) [0|281474976710655] "" Vector__XXX
 SG_ EPASTS_a225_debugInfo m225 : 16|48@1+ (1,0) [0|281474976710655] "" Vector__XXX
 SG_ EPASTS_a226_debugInfo m226 : 16|48@1+ (1,0) [0|281474976710655] "" Vector__XXX
 SG_ EPASTS_a227_debugInfo m227 : 16|48@1+ (1,0) [0|281474976710655] "" Vector__XXX
 SG_ EPASTS_a228_debugInfo m228 : 16|48@1+ (1,0) [0|281474976710655] "" Vector__XXX
 SG_ EPASTS_a229_debugInfo m229 : 16|48@1+ (1,0) [0|281474976710655] "" Vector__XXX
 SG_ EPASTS_a230_debugInfo m230 : 16|48@1+ (1,0) [0|281474976710655] "" Vector__XXX
 SG_ EPASTS_a231_debugInfo m231 : 16|48@1+ (1,0) [0|281474976710655] "" Vector__XXX
 SG_ EPASTS_a232_debugInfo m232 : 16|48@1+ (1,0) [0|281474976710655] "" Vector__XXX
 SG_ EPASTS_a233_debugInfo m233 : 16|48@1+ (1,0) [0|281474976710655] "" Vector__XXX
 SG_ EPASTS_a234_debugInfo m234 : 16|48@1+ (1,0) [0|281474976710655] "" Vector__XXX
 SG_ EPASTS_a235_debugInfo m235 : 16|48@1+ (1,0) [0|281474976710655] "" Vector__XXX
 SG_ EPASTS_a236_debugInfo m236 : 16|48@1+ (1,0) [0|281474976710655] "" Vector__XXX
 SG_ EPASTS_a237_debugInfo m237 : 16|48@1+ (1,0) [0|281474976710655] "" Vector__XXX
 SG_ EPASTS_a238_debugInfo m238 : 16|48@1+ (1,0) [0|281474976710655] "" Vector__XXX
 SG_ EPASTS_a239_debugInfo m239 : 16|48@1+ (1,0) [0|281474976710655] "" Vector__XXX
 SG_ EPASTS_a240_debugInfo m240 : 16|48@1+ (1,0) [0|281474976710655] "" Vector__XXX
 SG_ EPASTS_a241_debugInfo m241 : 16|48@1+ (1,0) [0|281474976710655] "" Vector__XXX
 SG_ EPASTS_a242_debugInfo m242 : 16|48@1+ (1,0) [0|281474976710655] "" Vector__XXX
 SG_ EPASTS_a243_debugInfo m243 : 16|48@1+ (1,0) [0|281474976710655] "" Vector__XXX
 SG_ EPASTS_a244_debugInfo m244 : 16|48@1+ (1,0) [0|281474976710655] "" Vector__XXX
 SG_ EPASTS_a245_debugInfo m245 : 16|48@1+ (1,0) [0|281474976710655] "" Vector__XXX
 SG_ EPASTS_a246_debugInfo m246 : 16|48@1+ (1,0) [0|281474976710655] "" Vector__XXX
 SG_ EPASTS_a247_debugInfo m247 : 16|48@1+ (1,0) [0|281474976710655] "" Vector__XXX
 SG_ EPASTS_a248_debugInfo m248 : 16|48@1+ (1,0) [0|281474976710655] "" Vector__XXX
 SG_ EPASTS_a249_debugInfo m249 : 16|48@1+ (1,0) [0|281474976710655] "" Vector__XXX
 SG_ EPASTS_a250_debugInfo m250 : 16|48@1+ (1,0) [0|281474976710655] "" Vector__XXX
 SG_ EPASTS_a252_debugInfo m252 : 16|48@1+ (1,0) [0|281474976710655] "" Vector__XXX
 SG_ EPASTS_a253_debugInfo m253 : 16|48@1+ (1,0) [0|281474976710655] "" Vector__XXX
 SG_ EPASTS_a254_debugInfo m254 : 16|48@1+ (1,0) [0|281474976710655] "" Vector__XXX
 SG_ EPASTS_a255_debugInfo m255 : 16|48@1+ (1,0) [0|281474976710655] "" Vector__XXX
 SG_ EPASTS_a256_debugInfo m256 : 16|48@1+ (1,0) [0|281474976710655] "" Vector__XXX
 SG_ EPASTS_a257_debugInfo m257 : 16|48@1+ (1,0) [0|281474976710655] "" Vector__XXX
 SG_ EPASTS_a258_debugInfo m258 : 16|48@1+ (1,0) [0|281474976710655] "" Vector__XXX
 SG_ EPASTS_a259_debugInfo m259 : 16|48@1+ (1,0) [0|281474976710655] "" Vector__XXX
 SG_ EPASTS_a260_debugInfo m260 : 16|48@1+ (1,0) [0|281474976710655] "" Vector__XXX
 SG_ EPASTS_a261_debugInfo m261 : 16|48@1+ (1,0) [0|281474976710655] "" Vector__XXX
 SG_ EPASTS_a262_debugInfo m262 : 16|48@1+ (1,0) [0|281474976710655] "" Vector__XXX
 SG_ EPASTS_a263_debugInfo m263 : 16|48@1+ (1,0) [0|281474976710655] "" Vector__XXX
 SG_ EPASTS_a264_degradedECU m264 : 16|8@1+ (1,0) [0|255] "" Vector__XXX
 SG_ EPASTS_a264_vehicleSpeed m264 : 24|16@1+ (0.1,0) [0|6553.5] "kph" Vector__XXX
 SG_ EPASTS_a264_powerRatio m264 : 40|8@1+ (1,0) [0|255] "percent" Vector__XXX
 SG_ EPASTS_a264_ownSideDegradationRe m264 : 48|8@1+ (1,0) [0|255] "" Vector__XXX
 SG_ EPASTS_a264_otherSideDegradation m264 : 56|8@1+ (1,0) [0|255] "" Vector__XXX
 SG_ EPASTS_a265_degradedECU m265 : 16|8@1+ (1,0) [0|255] "" Vector__XXX
 SG_ EPASTS_a265_vehicleSpeed m265 : 24|16@1+ (0.1,0) [0|6553.5] "kph" Vector__XXX
 SG_ EPASTS_a265_rawMcuTemperature m265 : 40|16@1+ (1,-100) [-100|65435] "C" Vector__XXX
 SG_ EPASTS_a265_degradedCurrentLimit m265 : 56|8@1+ (1,0) [0|255] "A" Vector__XXX
 SG_ EPASTS_a266_cdpAssistFactor m266 : 16|8@1+ (1,0) [0|255] "percent" Vector__XXX
 SG_ EPASTS_a266_vehicleSpeed m266 : 24|16@1+ (0.1,0) [0|6553.5] "kph" Vector__XXX
 SG_ EPASTS_a267_vehicleSpeed m267 : 16|16@1+ (0.1,0) [0|6553.5] "kph" Vector__XXX
 SG_ EPASTS_a267_velocityEstimatorSta m267 : 32|8@1+ (1,0) [0|255] "" Vector__XXX
 SG_ EPASTS_a269_vehicleSpeed m269 : 16|16@1+ (0.1,0) [0|6553.5] "kph" Vector__XXX
 SG_ EPASTS_a270_debugInfo m270 : 16|48@1+ (1,0) [0|281474976710655] "" Vector__XXX

BO_TX_BU_ 785 : EPAS3S;
BO_TX_BU_ 882 : EPAS3S;
BO_TX_BU_ 1848 : EPAS3S;
BO_TX_BU_ 1427 : EPASTP;
BO_TX_BU_ 919 : EPASTP;
BO_TX_BU_ 1428 : EPASTS;
CM_ BO_ 785 "Electric power steering (secondary) message: info";
CM_ SG_ 785 EPAS3S_infoIndex "Electric power steering (secondary): info index";
CM_ SG_ 785 EPAS3S_infoBuildType "Electric power steering (secondary): info build type";
CM_ SG_ 785 EPAS3S_infoComponentID "Electric power steering (secondary): info component ID";
CM_ SG_ 785 EPAS3S_infoPcbaID "Electric power steering (secondary): info pcba ID";
CM_ SG_ 785 EPAS3S_infoAssemblyID "Electric power steering (secondary): info assembly ID";
CM_ SG_ 785 EPAS3S_infoUsageID "Electric power steering (secondary): info usage ID";
CM_ SG_ 785 EPAS3S_infoApplicationCRC "Electric power steering (secondary): info application CRC";
CM_ SG_ 785 EPAS3S_infoBootUdsProtoVersion "Electric power steering (secondary): info boot uds proto version";
CM_ SG_ 785 EPAS3S_infoBootloaderCRC "Electric power steering (secondary): info bootloader CRC";
CM_ SG_ 785 EPAS3S_infoSubcomponent2 "Electric power steering (secondary): info subcomponent2";
CM_ BO_ 882 "Electric power steering (secondary) message: sys status";
CM_ SG_ 882 EPAS3S_steeringRackForce "The real time, estimated force applied by the steering rack to the tie rods; raw 1023 = signal not available (SNA)";
CM_ SG_ 882 EPAS3S_steeringFault "Electric power steering (secondary): steering fault";
CM_ SG_ 882 EPAS3S_steeringReduced "Electric power steering (secondary): steering reduced";
CM_ SG_ 882 EPAS3S_internalSASQF "This signal identifies the validity of the EPAS3P_internalSAS signal.";
CM_ SG_ 882 EPAS3S_currentTuneMode "Electric power steering (secondary): current tune mode";
CM_ SG_ 882 EPAS3S_torsionBarTorque "The measurement of the steering wheel torque input. If the value is positive the steering wheel torque is applied in the clockwise direction; raw 4095 = signal not available (SNA)";
CM_ SG_ 882 EPAS3S_eacErrorCode "Electric power steering (secondary): eac error code; raw 15 = signal not available (SNA)";
CM_ SG_ 882 EPAS3S_internalSAS "The measurement of the steering wheel angle that is calculated by electronic power steering assist steering. Clockwise positive.";
CM_ SG_ 882 EPAS3S_handsOnLevel "Electric power steering (secondary): hands on level";
CM_ SG_ 882 EPAS3S_sysStatusCounter "Electric power steering (secondary): sys status counter";
CM_ SG_ 882 EPAS3S_driverlessState "Electric power steering (secondary): driverless state";
CM_ SG_ 882 EPAS3S_eacStatus "Electric power steering (secondary): eac status";
CM_ SG_ 882 EPAS3S_sysStatusChecksum "Electric power steering (secondary): sys status checksum";
CM_ BO_ 1848 "Electric power steering (secondary) message: uds response";
CM_ SG_ 1848 EPAS3S_udsResponseData "Electric power steering (secondary): uds response data";
CM_ BO_ 1427 "EPASTP ECU message: alert log";
CM_ SG_ 1427 EPASTP_alertID "EPASTP ECU: alert ID";
CM_ SG_ 1427 EPASTP_alertState "EPASTP ECU: alert state";
CM_ SG_ 1427 EPASTP_a001_debugInfo "EPASTP ECU: a001 debug info";
CM_ SG_ 1427 EPASTP_a002_debugInfo "EPASTP ECU: a002 debug info";
CM_ SG_ 1427 EPASTP_a003_debugInfo "EPASTP ECU: a003 debug info";
CM_ SG_ 1427 EPASTP_a004_debugInfo "EPASTP ECU: a004 debug info";
CM_ SG_ 1427 EPASTP_a005_debugInfo "EPASTP ECU: a005 debug info";
CM_ SG_ 1427 EPASTP_a006_debugInfo "EPASTP ECU: a006 debug info";
CM_ SG_ 1427 EPASTP_a007_debugInfo "EPASTP ECU: a007 debug info";
CM_ SG_ 1427 EPASTP_a009_debugInfo "EPASTP ECU: a009 debug info";
CM_ SG_ 1427 EPASTP_a010_debugInfo "EPASTP ECU: a010 debug info";
CM_ SG_ 1427 EPASTP_a011_debugInfo "EPASTP ECU: a011 debug info";
CM_ SG_ 1427 EPASTP_a012_debugInfo "EPASTP ECU: a012 debug info";
CM_ SG_ 1427 EPASTP_a013_debugInfo "EPASTP ECU: a013 debug info";
CM_ SG_ 1427 EPASTP_a014_debugInfo "EPASTP ECU: a014 debug info";
CM_ SG_ 1427 EPASTP_a015_debugInfo "EPASTP ECU: a015 debug info";
CM_ SG_ 1427 EPASTP_a016_debugInfo "EPASTP ECU: a016 debug info";
CM_ SG_ 1427 EPASTP_a017_debugInfo "EPASTP ECU: a017 debug info";
CM_ SG_ 1427 EPASTP_a018_debugInfo "EPASTP ECU: a018 debug info";
CM_ SG_ 1427 EPASTP_a019_debugInfo "EPASTP ECU: a019 debug info";
CM_ SG_ 1427 EPASTP_a020_debugInfo "EPASTP ECU: a020 debug info";
CM_ SG_ 1427 EPASTP_a021_debugInfo "EPASTP ECU: a021 debug info";
CM_ SG_ 1427 EPASTP_a022_debugInfo "EPASTP ECU: a022 debug info";
CM_ SG_ 1427 EPASTP_a023_debugInfo "EPASTP ECU: a023 debug info";
CM_ SG_ 1427 EPASTP_a024_debugInfo "EPASTP ECU: a024 debug info";
CM_ SG_ 1427 EPASTP_a025_debugInfo "EPASTP ECU: a025 debug info";
CM_ SG_ 1427 EPASTP_a026_debugInfo "EPASTP ECU: a026 debug info";
CM_ SG_ 1427 EPASTP_a027_debugInfo "EPASTP ECU: a027 debug info";
CM_ SG_ 1427 EPASTP_a028_debugInfo "EPASTP ECU: a028 debug info";
CM_ SG_ 1427 EPASTP_a029_debugInfo "EPASTP ECU: a029 debug info";
CM_ SG_ 1427 EPASTP_a030_debugInfo "EPASTP ECU: a030 debug info";
CM_ SG_ 1427 EPASTP_a031_debugInfo "EPASTP ECU: a031 debug info";
CM_ SG_ 1427 EPASTP_a032_debugInfo "EPASTP ECU: a032 debug info";
CM_ SG_ 1427 EPASTP_a033_debugInfo "EPASTP ECU: a033 debug info";
CM_ SG_ 1427 EPASTP_a034_debugInfo "EPASTP ECU: a034 debug info";
CM_ SG_ 1427 EPASTP_a035_debugInfo "EPASTP ECU: a035 debug info";
CM_ SG_ 1427 EPASTP_a036_debugInfo "EPASTP ECU: a036 debug info";
CM_ SG_ 1427 EPASTP_a037_debugInfo "EPASTP ECU: a037 debug info";
CM_ SG_ 1427 EPASTP_a038_debugInfo "EPASTP ECU: a038 debug info";
CM_ SG_ 1427 EPASTP_a039_debugInfo "EPASTP ECU: a039 debug info";
CM_ SG_ 1427 EPASTP_a040_debugInfo "EPASTP ECU: a040 debug info";
CM_ SG_ 1427 EPASTP_a041_debugInfo "EPASTP ECU: a041 debug info";
CM_ SG_ 1427 EPASTP_a042_debugInfo "EPASTP ECU: a042 debug info";
CM_ SG_ 1427 EPASTP_a043_debugInfo "EPASTP ECU: a043 debug info";
CM_ SG_ 1427 EPASTP_a044_debugInfo "EPASTP ECU: a044 debug info";
CM_ SG_ 1427 EPASTP_a045_debugInfo "EPASTP ECU: a045 debug info";
CM_ SG_ 1427 EPASTP_a046_debugInfo "EPASTP ECU: a046 debug info";
CM_ SG_ 1427 EPASTP_a047_debugInfo "EPASTP ECU: a047 debug info";
CM_ SG_ 1427 EPASTP_a048_debugInfo "EPASTP ECU: a048 debug info";
CM_ SG_ 1427 EPASTP_a049_debugInfo "EPASTP ECU: a049 debug info";
CM_ SG_ 1427 EPASTP_a050_debugInfo "EPASTP ECU: a050 debug info";
CM_ SG_ 1427 EPASTP_a051_debugInfo "EPASTP ECU: a051 debug info";
CM_ SG_ 1427 EPASTP_a052_debugInfo "EPASTP ECU: a052 debug info";
CM_ SG_ 1427 EPASTP_a053_debugInfo "EPASTP ECU: a053 debug info";
CM_ SG_ 1427 EPASTP_a054_debugInfo "EPASTP ECU: a054 debug info";
CM_ SG_ 1427 EPASTP_a055_debugInfo "EPASTP ECU: a055 debug info";
CM_ SG_ 1427 EPASTP_a056_debugInfo "EPASTP ECU: a056 debug info";
CM_ SG_ 1427 EPASTP_a057_debugInfo "EPASTP ECU: a057 debug info";
CM_ SG_ 1427 EPASTP_a058_debugInfo "EPASTP ECU: a058 debug info";
CM_ SG_ 1427 EPASTP_a059_debugInfo "EPASTP ECU: a059 debug info";
CM_ SG_ 1427 EPASTP_a060_debugInfo "EPASTP ECU: a060 debug info";
CM_ SG_ 1427 EPASTP_a061_debugInfo "EPASTP ECU: a061 debug info";
CM_ SG_ 1427 EPASTP_a062_debugInfo "EPASTP ECU: a062 debug info";
CM_ SG_ 1427 EPASTP_a063_debugInfo "EPASTP ECU: a063 debug info";
CM_ SG_ 1427 EPASTP_a064_debugInfo "EPASTP ECU: a064 debug info";
CM_ SG_ 1427 EPASTP_a065_debugInfo "EPASTP ECU: a065 debug info";
CM_ SG_ 1427 EPASTP_a066_debugInfo "EPASTP ECU: a066 debug info";
CM_ SG_ 1427 EPASTP_a067_debugInfo "EPASTP ECU: a067 debug info";
CM_ SG_ 1427 EPASTP_a068_debugInfo "EPASTP ECU: a068 debug info";
CM_ SG_ 1427 EPASTP_a069_debugInfo "EPASTP ECU: a069 debug info";
CM_ SG_ 1427 EPASTP_a070_debugInfo "EPASTP ECU: a070 debug info";
CM_ SG_ 1427 EPASTP_a071_debugInfo "EPASTP ECU: a071 debug info";
CM_ SG_ 1427 EPASTP_a072_debugInfo "EPASTP ECU: a072 debug info";
CM_ SG_ 1427 EPASTP_a073_debugInfo "EPASTP ECU: a073 debug info";
CM_ SG_ 1427 EPASTP_a074_debugInfo "EPASTP ECU: a074 debug info";
CM_ SG_ 1427 EPASTP_a075_debugInfo "EPASTP ECU: a075 debug info";
CM_ SG_ 1427 EPASTP_a076_debugInfo "EPASTP ECU: a076 debug info";
CM_ SG_ 1427 EPASTP_a077_debugInfo "EPASTP ECU: a077 debug info";
CM_ SG_ 1427 EPASTP_a078_debugInfo "EPASTP ECU: a078 debug info";
CM_ SG_ 1427 EPASTP_a079_debugInfo "EPASTP ECU: a079 debug info";
CM_ SG_ 1427 EPASTP_a080_debugInfo "EPASTP ECU: a080 debug info";
CM_ SG_ 1427 EPASTP_a081_debugInfo "EPASTP ECU: a081 debug info";
CM_ SG_ 1427 EPASTP_a082_debugInfo "EPASTP ECU: a082 debug info";
CM_ SG_ 1427 EPASTP_a083_debugInfo "EPASTP ECU: a083 debug info";
CM_ SG_ 1427 EPASTP_a084_debugInfo "EPASTP ECU: a084 debug info";
CM_ SG_ 1427 EPASTP_a085_debugInfo "EPASTP ECU: a085 debug info";
CM_ SG_ 1427 EPASTP_a086_debugInfo "EPASTP ECU: a086 debug info";
CM_ SG_ 1427 EPASTP_a087_debugInfo "EPASTP ECU: a087 debug info";
CM_ SG_ 1427 EPASTP_a088_debugInfo "EPASTP ECU: a088 debug info";
CM_ SG_ 1427 EPASTP_a089_debugInfo "EPASTP ECU: a089 debug info";
CM_ SG_ 1427 EPASTP_a090_debugInfo "EPASTP ECU: a090 debug info";
CM_ SG_ 1427 EPASTP_a091_debugInfo "EPASTP ECU: a091 debug info";
CM_ SG_ 1427 EPASTP_a092_debugInfo "EPASTP ECU: a092 debug info";
CM_ SG_ 1427 EPASTP_a093_debugInfo "EPASTP ECU: a093 debug info";
CM_ SG_ 1427 EPASTP_a094_debugInfo "EPASTP ECU: a094 debug info";
CM_ SG_ 1427 EPASTP_a095_debugInfo "EPASTP ECU: a095 debug info";
CM_ SG_ 1427 EPASTP_a096_debugInfo "EPASTP ECU: a096 debug info";
CM_ SG_ 1427 EPASTP_a097_debugInfo "EPASTP ECU: a097 debug info";
CM_ SG_ 1427 EPASTP_a098_debugInfo "EPASTP ECU: a098 debug info";
CM_ SG_ 1427 EPASTP_a099_debugInfo "EPASTP ECU: a099 debug info";
CM_ SG_ 1427 EPASTP_a100_debugInfo "EPASTP ECU: a100 debug info";
CM_ SG_ 1427 EPASTP_a101_debugInfo "EPASTP ECU: a101 debug info";
CM_ SG_ 1427 EPASTP_a102_debugInfo "EPASTP ECU: a102 debug info";
CM_ SG_ 1427 EPASTP_a103_debugInfo "EPASTP ECU: a103 debug info";
CM_ SG_ 1427 EPASTP_a104_debugInfo "EPASTP ECU: a104 debug info";
CM_ SG_ 1427 EPASTP_a105_debugInfo "EPASTP ECU: a105 debug info";
CM_ SG_ 1427 EPASTP_a106_debugInfo "EPASTP ECU: a106 debug info";
CM_ SG_ 1427 EPASTP_a107_debugInfo "EPASTP ECU: a107 debug info";
CM_ SG_ 1427 EPASTP_a108_debugInfo "EPASTP ECU: a108 debug info";
CM_ SG_ 1427 EPASTP_a109_debugInfo "EPASTP ECU: a109 debug info";
CM_ SG_ 1427 EPASTP_a110_debugInfo "EPASTP ECU: a110 debug info";
CM_ SG_ 1427 EPASTP_a111_debugInfo "EPASTP ECU: a111 debug info";
CM_ SG_ 1427 EPASTP_a112_debugInfo "EPASTP ECU: a112 debug info";
CM_ SG_ 1427 EPASTP_a113_debugInfo "EPASTP ECU: a113 debug info";
CM_ SG_ 1427 EPASTP_a114_debugInfo "EPASTP ECU: a114 debug info";
CM_ SG_ 1427 EPASTP_a115_debugInfo "EPASTP ECU: a115 debug info";
CM_ SG_ 1427 EPASTP_a116_debugInfo "EPASTP ECU: a116 debug info";
CM_ SG_ 1427 EPASTP_a117_debugInfo "EPASTP ECU: a117 debug info";
CM_ SG_ 1427 EPASTP_a118_debugInfo "EPASTP ECU: a118 debug info";
CM_ SG_ 1427 EPASTP_a119_debugInfo "EPASTP ECU: a119 debug info";
CM_ SG_ 1427 EPASTP_a120_debugInfo "EPASTP ECU: a120 debug info";
CM_ SG_ 1427 EPASTP_a121_debugInfo "EPASTP ECU: a121 debug info";
CM_ SG_ 1427 EPASTP_a122_debugInfo "EPASTP ECU: a122 debug info";
CM_ SG_ 1427 EPASTP_a123_debugInfo "EPASTP ECU: a123 debug info";
CM_ SG_ 1427 EPASTP_a124_debugInfo "EPASTP ECU: a124 debug info";
CM_ SG_ 1427 EPASTP_a125_debugInfo "EPASTP ECU: a125 debug info";
CM_ SG_ 1427 EPASTP_a126_debugInfo "EPASTP ECU: a126 debug info";
CM_ SG_ 1427 EPASTP_a127_debugInfo "EPASTP ECU: a127 debug info";
CM_ SG_ 1427 EPASTP_a128_debugInfo "EPASTP ECU: a128 debug info";
CM_ SG_ 1427 EPASTP_a129_debugInfo "EPASTP ECU: a129 debug info";
CM_ SG_ 1427 EPASTP_a130_debugInfo "EPASTP ECU: a130 debug info";
CM_ SG_ 1427 EPASTP_a131_debugInfo "EPASTP ECU: a131 debug info";
CM_ SG_ 1427 EPASTP_a132_debugInfo "EPASTP ECU: a132 debug info";
CM_ SG_ 1427 EPASTP_a133_debugInfo "EPASTP ECU: a133 debug info";
CM_ SG_ 1427 EPASTP_a134_debugInfo "EPASTP ECU: a134 debug info";
CM_ SG_ 1427 EPASTP_a135_debugInfo "EPASTP ECU: a135 debug info";
CM_ SG_ 1427 EPASTP_a136_debugInfo "EPASTP ECU: a136 debug info";
CM_ SG_ 1427 EPASTP_a137_debugInfo "EPASTP ECU: a137 debug info";
CM_ SG_ 1427 EPASTP_a138_debugInfo "EPASTP ECU: a138 debug info";
CM_ SG_ 1427 EPASTP_a139_debugInfo "EPASTP ECU: a139 debug info";
CM_ SG_ 1427 EPASTP_a140_debugInfo "EPASTP ECU: a140 debug info";
CM_ SG_ 1427 EPASTP_a141_debugInfo "EPASTP ECU: a141 debug info";
CM_ SG_ 1427 EPASTP_a142_debugInfo "EPASTP ECU: a142 debug info";
CM_ SG_ 1427 EPASTP_a143_debugInfo "EPASTP ECU: a143 debug info";
CM_ SG_ 1427 EPASTP_a144_debugInfo "EPASTP ECU: a144 debug info";
CM_ SG_ 1427 EPASTP_a145_debugInfo "EPASTP ECU: a145 debug info";
CM_ SG_ 1427 EPASTP_a146_debugInfo "EPASTP ECU: a146 debug info";
CM_ SG_ 1427 EPASTP_a147_debugInfo "EPASTP ECU: a147 debug info";
CM_ SG_ 1427 EPASTP_a148_debugInfo "EPASTP ECU: a148 debug info";
CM_ SG_ 1427 EPASTP_a149_debugInfo "EPASTP ECU: a149 debug info";
CM_ SG_ 1427 EPASTP_a150_debugInfo "EPASTP ECU: a150 debug info";
CM_ SG_ 1427 EPASTP_a152_debugInfo "EPASTP ECU: a152 debug info";
CM_ SG_ 1427 EPASTP_a153_debugInfo "EPASTP ECU: a153 debug info";
CM_ SG_ 1427 EPASTP_a154_debugInfo "EPASTP ECU: a154 debug info";
CM_ SG_ 1427 EPASTP_a155_debugInfo "EPASTP ECU: a155 debug info";
CM_ SG_ 1427 EPASTP_a156_debugInfo "EPASTP ECU: a156 debug info";
CM_ SG_ 1427 EPASTP_a157_debugInfo "EPASTP ECU: a157 debug info";
CM_ SG_ 1427 EPASTP_a158_debugInfo "EPASTP ECU: a158 debug info";
CM_ SG_ 1427 EPASTP_a159_debugInfo "EPASTP ECU: a159 debug info";
CM_ SG_ 1427 EPASTP_a160_debugInfo "EPASTP ECU: a160 debug info";
CM_ SG_ 1427 EPASTP_a161_debugInfo "EPASTP ECU: a161 debug info";
CM_ SG_ 1427 EPASTP_a162_debugInfo "EPASTP ECU: a162 debug info";
CM_ SG_ 1427 EPASTP_a163_debugInfo "EPASTP ECU: a163 debug info";
CM_ SG_ 1427 EPASTP_a164_debugInfo "EPASTP ECU: a164 debug info";
CM_ SG_ 1427 EPASTP_a165_debugInfo "EPASTP ECU: a165 debug info";
CM_ SG_ 1427 EPASTP_a166_debugInfo "EPASTP ECU: a166 debug info";
CM_ SG_ 1427 EPASTP_a167_debugInfo "EPASTP ECU: a167 debug info";
CM_ SG_ 1427 EPASTP_a168_debugInfo "EPASTP ECU: a168 debug info";
CM_ SG_ 1427 EPASTP_a169_debugInfo "EPASTP ECU: a169 debug info";
CM_ SG_ 1427 EPASTP_a170_debugInfo "EPASTP ECU: a170 debug info";
CM_ SG_ 1427 EPASTP_a171_debugInfo "EPASTP ECU: a171 debug info";
CM_ SG_ 1427 EPASTP_a172_debugInfo "EPASTP ECU: a172 debug info";
CM_ SG_ 1427 EPASTP_a173_debugInfo "EPASTP ECU: a173 debug info";
CM_ SG_ 1427 EPASTP_a174_debugInfo "EPASTP ECU: a174 debug info";
CM_ SG_ 1427 EPASTP_a175_debugInfo "EPASTP ECU: a175 debug info";
CM_ SG_ 1427 EPASTP_a176_debugInfo "EPASTP ECU: a176 debug info";
CM_ SG_ 1427 EPASTP_a177_debugInfo "EPASTP ECU: a177 debug info";
CM_ SG_ 1427 EPASTP_a178_debugInfo "EPASTP ECU: a178 debug info";
CM_ SG_ 1427 EPASTP_a179_debugInfo "EPASTP ECU: a179 debug info";
CM_ SG_ 1427 EPASTP_a180_debugInfo "EPASTP ECU: a180 debug info";
CM_ SG_ 1427 EPASTP_a181_debugInfo "EPASTP ECU: a181 debug info";
CM_ SG_ 1427 EPASTP_a182_debugInfo "EPASTP ECU: a182 debug info";
CM_ SG_ 1427 EPASTP_a183_debugInfo "EPASTP ECU: a183 debug info";
CM_ SG_ 1427 EPASTP_a184_debugInfo "EPASTP ECU: a184 debug info";
CM_ SG_ 1427 EPASTP_a185_debugInfo "EPASTP ECU: a185 debug info";
CM_ SG_ 1427 EPASTP_a186_debugInfo "EPASTP ECU: a186 debug info";
CM_ SG_ 1427 EPASTP_a188_debugInfo "EPASTP ECU: a188 debug info";
CM_ SG_ 1427 EPASTP_a189_debugInfo "EPASTP ECU: a189 debug info";
CM_ SG_ 1427 EPASTP_a190_debugInfo "EPASTP ECU: a190 debug info";
CM_ SG_ 1427 EPASTP_a191_debugInfo "EPASTP ECU: a191 debug info";
CM_ SG_ 1427 EPASTP_a192_debugInfo "EPASTP ECU: a192 debug info";
CM_ SG_ 1427 EPASTP_a193_debugInfo "EPASTP ECU: a193 debug info";
CM_ SG_ 1427 EPASTP_a194_debugInfo "EPASTP ECU: a194 debug info";
CM_ SG_ 1427 EPASTP_a195_debugInfo "EPASTP ECU: a195 debug info";
CM_ SG_ 1427 EPASTP_a196_debugInfo "EPASTP ECU: a196 debug info";
CM_ SG_ 1427 EPASTP_a197_debugInfo "EPASTP ECU: a197 debug info";
CM_ SG_ 1427 EPASTP_a198_debugInfo "EPASTP ECU: a198 debug info";
CM_ SG_ 1427 EPASTP_a199_debugInfo "EPASTP ECU: a199 debug info";
CM_ SG_ 1427 EPASTP_a200_debugInfo "EPASTP ECU: a200 debug info";
CM_ SG_ 1427 EPASTP_a201_debugInfo "EPASTP ECU: a201 debug info";
CM_ SG_ 1427 EPASTP_a202_debugInfo "EPASTP ECU: a202 debug info";
CM_ SG_ 1427 EPASTP_a203_debugInfo "EPASTP ECU: a203 debug info";
CM_ SG_ 1427 EPASTP_a204_debugInfo "EPASTP ECU: a204 debug info";
CM_ SG_ 1427 EPASTP_a205_debugInfo "EPASTP ECU: a205 debug info";
CM_ SG_ 1427 EPASTP_a206_debugInfo "EPASTP ECU: a206 debug info";
CM_ SG_ 1427 EPASTP_a207_debugInfo "EPASTP ECU: a207 debug info";
CM_ SG_ 1427 EPASTP_a208_debugInfo "EPASTP ECU: a208 debug info";
CM_ SG_ 1427 EPASTP_a209_debugInfo "EPASTP ECU: a209 debug info";
CM_ SG_ 1427 EPASTP_a210_debugInfo "EPASTP ECU: a210 debug info";
CM_ SG_ 1427 EPASTP_a211_debugInfo "EPASTP ECU: a211 debug info";
CM_ SG_ 1427 EPASTP_a212_debugInfo "EPASTP ECU: a212 debug info";
CM_ SG_ 1427 EPASTP_a213_debugInfo "EPASTP ECU: a213 debug info";
CM_ SG_ 1427 EPASTP_a214_debugInfo "EPASTP ECU: a214 debug info";
CM_ SG_ 1427 EPASTP_a215_debugInfo "EPASTP ECU: a215 debug info";
CM_ SG_ 1427 EPASTP_a216_debugInfo "EPASTP ECU: a216 debug info";
CM_ SG_ 1427 EPASTP_a217_debugInfo "EPASTP ECU: a217 debug info";
CM_ SG_ 1427 EPASTP_a218_debugInfo "EPASTP ECU: a218 debug info";
CM_ SG_ 1427 EPASTP_a219_debugInfo "EPASTP ECU: a219 debug info";
CM_ SG_ 1427 EPASTP_a221_debugInfo "EPASTP ECU: a221 debug info";
CM_ SG_ 1427 EPASTP_a222_debugInfo "EPASTP ECU: a222 debug info";
CM_ SG_ 1427 EPASTP_a223_debugInfo "EPASTP ECU: a223 debug info";
CM_ SG_ 1427 EPASTP_a224_debugInfo "EPASTP ECU: a224 debug info";
CM_ SG_ 1427 EPASTP_a225_debugInfo "EPASTP ECU: a225 debug info";
CM_ SG_ 1427 EPASTP_a226_debugInfo "EPASTP ECU: a226 debug info";
CM_ SG_ 1427 EPASTP_a227_debugInfo "EPASTP ECU: a227 debug info";
CM_ SG_ 1427 EPASTP_a228_debugInfo "EPASTP ECU: a228 debug info";
CM_ SG_ 1427 EPASTP_a229_debugInfo "EPASTP ECU: a229 debug info";
CM_ SG_ 1427 EPASTP_a230_debugInfo "EPASTP ECU: a230 debug info";
CM_ SG_ 1427 EPASTP_a231_debugInfo "EPASTP ECU: a231 debug info";
CM_ SG_ 1427 EPASTP_a232_debugInfo "EPASTP ECU: a232 debug info";
CM_ SG_ 1427 EPASTP_a233_debugInfo "EPASTP ECU: a233 debug info";
CM_ SG_ 1427 EPASTP_a234_debugInfo "EPASTP ECU: a234 debug info";
CM_ SG_ 1427 EPASTP_a235_debugInfo "EPASTP ECU: a235 debug info";
CM_ SG_ 1427 EPASTP_a236_debugInfo "EPASTP ECU: a236 debug info";
CM_ SG_ 1427 EPASTP_a237_debugInfo "EPASTP ECU: a237 debug info";
CM_ SG_ 1427 EPASTP_a238_debugInfo "EPASTP ECU: a238 debug info";
CM_ SG_ 1427 EPASTP_a239_debugInfo "EPASTP ECU: a239 debug info";
CM_ SG_ 1427 EPASTP_a240_debugInfo "EPASTP ECU: a240 debug info";
CM_ SG_ 1427 EPASTP_a241_debugInfo "EPASTP ECU: a241 debug info";
CM_ SG_ 1427 EPASTP_a242_debugInfo "EPASTP ECU: a242 debug info";
CM_ SG_ 1427 EPASTP_a243_debugInfo "EPASTP ECU: a243 debug info";
CM_ SG_ 1427 EPASTP_a244_debugInfo "EPASTP ECU: a244 debug info";
CM_ SG_ 1427 EPASTP_a245_debugInfo "EPASTP ECU: a245 debug info";
CM_ SG_ 1427 EPASTP_a246_debugInfo "EPASTP ECU: a246 debug info";
CM_ SG_ 1427 EPASTP_a247_debugInfo "EPASTP ECU: a247 debug info";
CM_ SG_ 1427 EPASTP_a248_debugInfo "EPASTP ECU: a248 debug info";
CM_ SG_ 1427 EPASTP_a249_debugInfo "EPASTP ECU: a249 debug info";
CM_ SG_ 1427 EPASTP_a250_debugInfo "EPASTP ECU: a250 debug info";
CM_ SG_ 1427 EPASTP_a252_debugInfo "EPASTP ECU: a252 debug info";
CM_ SG_ 1427 EPASTP_a253_debugInfo "EPASTP ECU: a253 debug info";
CM_ SG_ 1427 EPASTP_a254_debugInfo "EPASTP ECU: a254 debug info";
CM_ SG_ 1427 EPASTP_a255_debugInfo "EPASTP ECU: a255 debug info";
CM_ SG_ 1427 EPASTP_a256_debugInfo "EPASTP ECU: a256 debug info";
CM_ SG_ 1427 EPASTP_a257_debugInfo "EPASTP ECU: a257 debug info";
CM_ SG_ 1427 EPASTP_a258_debugInfo "EPASTP ECU: a258 debug info";
CM_ SG_ 1427 EPASTP_a259_debugInfo "EPASTP ECU: a259 debug info";
CM_ SG_ 1427 EPASTP_a260_debugInfo "EPASTP ECU: a260 debug info";
CM_ SG_ 1427 EPASTP_a261_debugInfo "EPASTP ECU: a261 debug info";
CM_ SG_ 1427 EPASTP_a262_debugInfo "EPASTP ECU: a262 debug info";
CM_ SG_ 1427 EPASTP_a263_debugInfo "EPASTP ECU: a263 debug info";
CM_ SG_ 1427 EPASTP_a264_degradedECU "EPASTP ECU: a264 degraded ECU";
CM_ SG_ 1427 EPASTP_a264_vehicleSpeed "EPASTP ECU: a264 vehicle speed";
CM_ SG_ 1427 EPASTP_a264_powerRatio "EPASTP ECU: a264 power ratio";
CM_ SG_ 1427 EPASTP_a264_ownSideDegradationRe "EPASTP ECU: a264 own side degradation reason";
CM_ SG_ 1427 EPASTP_a264_otherSideDegradation "EPASTP ECU: a264 other side degradation reason";
CM_ SG_ 1427 EPASTP_a265_degradedECU "EPASTP ECU: a265 degraded ECU";
CM_ SG_ 1427 EPASTP_a265_vehicleSpeed "EPASTP ECU: a265 vehicle speed";
CM_ SG_ 1427 EPASTP_a265_rawMcuTemperature "EPASTP ECU: a265 raw mcu temperature";
CM_ SG_ 1427 EPASTP_a265_degradedCurrentLimit "EPASTP ECU: a265 degraded current limit";
CM_ SG_ 1427 EPASTP_a266_cdpAssistFactor "EPASTP ECU: a266 cdp assist factor";
CM_ SG_ 1427 EPASTP_a266_vehicleSpeed "EPASTP ECU: a266 vehicle speed";
CM_ SG_ 1427 EPASTP_a267_vehicleSpeed "EPASTP ECU: a267 vehicle speed";
CM_ SG_ 1427 EPASTP_a267_velocityEstimatorSta "EPASTP ECU: a267 velocity estimator state";
CM_ SG_ 1427 EPASTP_a269_vehicleSpeed "EPASTP ECU: a269 vehicle speed";
CM_ SG_ 1427 EPASTP_a270_debugInfo "EPASTP ECU: a270 debug info";
CM_ BO_ 919 "EPASTP ECU message: alert matrix";
CM_ SG_ 919 EPASTP_matrixIndex "EPASTP ECU: matrix index";
CM_ SG_ 919 EPASTP_a001_adcCalibrationOrInit "EPASTP ECU: a001 adc calibration or init fail";
CM_ SG_ 919 EPASTP_a002_adcMuxErr "EPASTP ECU: a002 adc mux err";
CM_ SG_ 919 EPASTP_a003_pspInvalidParamset "EPASTP ECU: a003 psp invalid paramset";
CM_ SG_ 919 EPASTP_a004_scpInputMia "EPASTP ECU: a004 scp input mia";
CM_ SG_ 919 EPASTP_a005_scpUnknownResetSourc "EPASTP ECU: a005 scp unknown reset source";
CM_ SG_ 919 EPASTP_a006_swrhResetByInvalidEr "EPASTP ECU: a006 swrh reset by invalid errid";
CM_ SG_ 919 EPASTP_a007_tsmcCoreTempDiff "EPASTP ECU: a007 tsmc core temp diff";
CM_ SG_ 919 EPASTP_a008_psdcPlatformShutdown "EPASTP ECU: a008 psdc platform shutdown";
CM_ SG_ 919 EPASTP_a009_mcusscLbistPermanent "EPASTP ECU: a009 mcussc lbist permanent fail";
CM_ SG_ 919 EPASTP_a010_svcIncompatibleSwVer "EPASTP ECU: a010 svc incompatible sw versions";
CM_ SG_ 919 EPASTP_a011_mcusscMonbistErr "EPASTP ECU: a011 mcussc monbist err";
CM_ SG_ 919 EPASTP_a012_mcusscMbistEccErr "EPASTP ECU: a012 mcussc mbist ecc err";
CM_ SG_ 919 EPASTP_a013_mcusscSffMonitoringF "EPASTP ECU: a013 mcussc sff monitoring failed";
CM_ SG_ 919 EPASTP_a014_mcusscSffMonitoringM "EPASTP ECU: a014 mcussc sff monitoring mia";
CM_ SG_ 919 EPASTP_a015_mcusscCsErrorCheckFa "EPASTP ECU: a015 mcussc cs error check fail";
CM_ SG_ 919 EPASTP_a016_mcufcCsErrorCheckFai "EPASTP ECU: a016 mcufc cs error check fail";
CM_ SG_ 919 EPASTP_a017_stmdStmPlausibilityC "EPASTP ECU: a017 stmd stm plausibility check err";
CM_ SG_ 919 EPASTP_a018_exchCsErrorCheck "EPASTP ECU: a018 exch cs error check";
CM_ SG_ 919 EPASTP_a019_rsthHwResetInfoCorru "EPASTP ECU: a019 rsth hw reset info corruption check";
CM_ SG_ 919 EPASTP_a020_mcusscEolEcuIdIntegr "EPASTP ECU: a020 mcussc eol ecu id integritiy fail";
CM_ SG_ 919 EPASTP_a021_osehCsErrorCheck "EPASTP ECU: a021 oseh cs error check";
CM_ SG_ 919 EPASTP_a022_swrhSwResetInfoCorru "EPASTP ECU: a022 swrh sw reset info corruption check";
CM_ SG_ 919 EPASTP_a023_btarcCorruptionCheck "EPASTP ECU: a023 btarc corruption check";
CM_ SG_ 919 EPASTP_a024_srhCsErrorCheckFail "EPASTP ECU: a024 srh cs error check fail";
CM_ SG_ 919 EPASTP_a025_btarcCorruptionCheck "EPASTP ECU: a025 btarc corruption check";
CM_ SG_ 919 EPASTP_a026_mrccCsErrorCheckFail "EPASTP ECU: a026 mrcc cs error check fail";
CM_ SG_ 919 EPASTP_a027_mcusscDmuHfErr "EPASTP ECU: a027 mcussc dmu hf err";
CM_ SG_ 919 EPASTP_a028_smuhNonInitDataCorru "EPASTP ECU: a028 smuh non init data corruption";
CM_ SG_ 919 EPASTP_a029_smuhSmuCoreCntErrorT "EPASTP ECU: a029 smuh smu core cnt error test fail";
CM_ SG_ 919 EPASTP_a030_rsthClockReset "EPASTP ECU: a030 rsth clock reset";
CM_ SG_ 919 EPASTP_a031_pmsProductionModeFai "EPASTP ECU: a031 pms production mode failed";
CM_ SG_ 919 EPASTP_a032_eolpEolCheckFailed "EPASTP ECU: a032 eolp eol check failed";
CM_ SG_ 919 EPASTP_a033_icsvcPswVersionMisma "EPASTP ECU: a033 icsvc psw version mismatch";
CM_ SG_ 919 EPASTP_a034_sbchReadbackRegFail "EPASTP ECU: a034 sbch readback reg fail";
CM_ SG_ 919 EPASTP_a035_sbchChipIdFail "EPASTP ECU: a035 sbch chip id fail";
CM_ SG_ 919 EPASTP_a036_sbcmSbcBistFailed "EPASTP ECU: a036 sbcm sbc bist failed";
CM_ SG_ 919 EPASTP_a037_epmV5P2Fail "EPASTP ECU: a037 epm V5 P2 fail";
CM_ SG_ 919 EPASTP_a038_csohCh1CsErrorErrAtR "EPASTP ECU: a038 csoh ch1 cs error err at reset";
CM_ SG_ 919 EPASTP_a039_csohCh2CsErrorErrAtR "EPASTP ECU: a039 csoh ch2 cs error err at reset";
CM_ SG_ 919 EPASTP_a040_swrhLimitedResetRetr "EPASTP ECU: a040 swrh limited reset retries expired";
CM_ SG_ 919 EPASTP_a041_imcmCoreConfiguratio "EPASTP ECU: a041 imcm core configuration mismatch";
CM_ SG_ 919 EPASTP_a042_wdhWdTestFail "EPASTP ECU: a042 wdh wd test fail";
CM_ SG_ 919 EPASTP_a043_sbcmWdStateDisabled "EPASTP ECU: a043 sbcm wd state disabled";
CM_ SG_ 919 EPASTP_a044_sbcmSbcEepromFail "EPASTP ECU: a044 sbcm sbc eeprom fail";
CM_ SG_ 919 EPASTP_a045_psumSbcBandgapVoltEr "EPASTP ECU: a045 psum sbc bandgap volt err";
CM_ SG_ 919 EPASTP_a046_mcusscOscillatorNotR "EPASTP ECU: a046 mcussc oscillator not reliable";
CM_ SG_ 919 EPASTP_a047_epmVregVoltFail "EPASTP ECU: a047 epm vreg volt fail";
CM_ SG_ 919 EPASTP_a048_epmVcpVoltFail "EPASTP ECU: a048 epm vcp volt fail";
CM_ SG_ 919 EPASTP_a049_epmLgFail "EPASTP ECU: a049 epm lg fail";
CM_ SG_ 919 EPASTP_a050_erlErr "EPASTP ECU: a050 erl err";
CM_ SG_ 919 EPASTP_a051_ermMessageErr "EPASTP ECU: a051 erm message err";
CM_ SG_ 919 EPASTP_a052_ermSdcInputBufferOve "EPASTP ECU: a052 erm sdc input buffer overflow";
CM_ SG_ 919 EPASTP_a053_adcUnexpectedNumOfDa "EPASTP ECU: a053 adc unexpected num of data";
CM_ SG_ 919 EPASTP_a054_adcUnexpectedData "EPASTP ECU: a054 adc unexpected data";
CM_ SG_ 919 EPASTP_a055_amExtendedGduTest "EPASTP ECU: a055 am extended gdu test";
CM_ SG_ 919 EPASTP_a056_amGduConfigCsErrorCh "EPASTP ECU: a056 am gdu config cs error check";
CM_ SG_ 919 EPASTP_a057_amGduVds "EPASTP ECU: a057 am gdu vds";
CM_ SG_ 919 EPASTP_a058_amIntVgsUndervtgErr "EPASTP ECU: a058 am int vgs undervtg err";
CM_ SG_ 919 EPASTP_a059_amStartupTestFailed "EPASTP ECU: a059 am startup test failed";
CM_ SG_ 919 EPASTP_a060_amGduFail "EPASTP ECU: a060 am gdu fail";
CM_ SG_ 919 EPASTP_a061_amIntSerialErr "EPASTP ECU: a061 am int serial err";
CM_ SG_ 919 EPASTP_a062_amPhaseBridgeCheck "EPASTP ECU: a062 am phase bridge check";
CM_ SG_ 919 EPASTP_a063_amIntRegulatorErr "EPASTP ECU: a063 am int regulator err";
CM_ SG_ 919 EPASTP_a064_amBridgeShort "EPASTP ECU: a064 am bridge short";
CM_ SG_ 919 EPASTP_a065_amGduJuncTemp "EPASTP ECU: a065 am gdu junc temp";
CM_ SG_ 919 EPASTP_a066_amVoltQfErr "EPASTP ECU: a066 am volt qf err";
CM_ SG_ 919 EPASTP_a067_tspmPowermoduleTempI "EPASTP ECU: a067 tspm powermodule temp implausible";
CM_ SG_ 919 EPASTP_a068_rsthCoreRedundancyEr "EPASTP ECU: a068 rsth core redundancy err";
CM_ SG_ 919 EPASTP_a069_rsthCoreTempOutOfRan "EPASTP ECU: a069 rsth core temp out of range hw check";
CM_ SG_ 919 EPASTP_a070_rsthInternalLowVolt "EPASTP ECU: a070 rsth internal low volt";
CM_ SG_ 919 EPASTP_a071_rsthInternalHighVolt "EPASTP ECU: a071 rsth internal high volt";
CM_ SG_ 919 EPASTP_a072_rsthFlashUncorrEccOr "EPASTP ECU: a072 rsth flash uncorr ecc or ovfl";
CM_ SG_ 919 EPASTP_a073_rsthOtherEdcEcc "EPASTP ECU: a073 rsth other edc ecc";
CM_ SG_ 919 EPASTP_a074_rsthUnexpectedAlarm "EPASTP ECU: a074 rsth unexpected alarm";
CM_ SG_ 919 EPASTP_a075_rsthUnusedOtherModul "EPASTP ECU: a075 rsth unused other module alarm";
CM_ SG_ 919 EPASTP_a076_exchGeneralException "EPASTP ECU: a076 exch general exception";
CM_ SG_ 919 EPASTP_a077_dmDeadlineViolation "EPASTP ECU: a077 dm deadline violation";
CM_ SG_ 919 EPASTP_a078_dmDeadlineViolation "EPASTP ECU: a078 dm deadline violation";
CM_ SG_ 919 EPASTP_a079_gduhComErr "EPASTP ECU: a079 gduh com err";
CM_ SG_ 919 EPASTP_a080_pwmTimerSyncCheck "EPASTP ECU: a080 pwm timer sync check";
CM_ SG_ 919 EPASTP_a081_exchFloatingPointExc "EPASTP ECU: a081 exch floating point exception";
CM_ SG_ 919 EPASTP_a082_adcTriggerTimeChk "EPASTP ECU: a082 adc trigger time chk";
CM_ SG_ 919 EPASTP_a083_tdaDclinkcapacitorTe "EPASTP ECU: a083 tda dclinkcapacitor temp checker";
CM_ SG_ 919 EPASTP_a084_adcTriggerCheck "EPASTP ECU: a084 adc trigger check";
CM_ SG_ 919 EPASTP_a085_amGduSwitchOffTestBy "EPASTP ECU: a085 am gdu switch off test by mcu";
CM_ SG_ 919 EPASTP_a086_rsthRamUncorrEcc "EPASTP ECU: a086 rsth ram uncorr ecc";
CM_ SG_ 919 EPASTP_a087_rsthFlashConfigErr "EPASTP ECU: a087 rsth flash config err";
CM_ SG_ 919 EPASTP_a088_tedMainboardTempChec "EPASTP ECU: a088 ted mainboard temp checker";
CM_ SG_ 919 EPASTP_a089_tedRevercebattfetjun "EPASTP ECU: a089 ted revercebattfetjunction temp checker";
CM_ SG_ 919 EPASTP_a090_etsmWarning "EPASTP ECU: a090 etsm warning";
CM_ SG_ 919 EPASTP_a091_bvpBattVoltCrossChkF "EPASTP ECU: a091 bvp batt volt cross chk failed";
CM_ SG_ 919 EPASTP_a092_amGduSwitchOffTestBy "EPASTP ECU: a092 am gdu switch off test by sbc";
CM_ SG_ 919 EPASTP_a093_sctpTsuSingleStaticF "EPASTP ECU: a093 sctp tsu single static fail";
CM_ SG_ 919 EPASTP_a094_sctpTsuMultipleStati "EPASTP ECU: a094 sctp tsu multiple static fail";
CM_ SG_ 919 EPASTP_a095_mdModelBasedMotorInt "EPASTP ECU: a095 md model based motor integrity check";
CM_ SG_ 919 EPASTP_a096_rppRpsSingleStaticFa "EPASTP ECU: a096 rpp rps single static fail";
CM_ SG_ 919 EPASTP_a097_rppRpsMultipleStatic "EPASTP ECU: a097 rpp rps multiple static fail";
CM_ SG_ 919 EPASTP_a098_invErr "EPASTP ECU: a098 inv err";
CM_ SG_ 919 EPASTP_a099_mcdTorqueMismatchFau "EPASTP ECU: a099 mcd torque mismatch fault";
CM_ SG_ 919 EPASTP_a100_amVbrgLssFault "EPASTP ECU: a100 am vbrg lss fault";
CM_ SG_ 919 EPASTP_a101_sdrvSpcIdMismatch "EPASTP ECU: a101 sdrv spc id mismatch";
CM_ SG_ 919 EPASTP_a102_amPhasecurrentQosErr "EPASTP ECU: a102 am phasecurrent qos err";
CM_ SG_ 919 EPASTP_a103_exhaUnusedInterruptC "EPASTP ECU: a103 exha unused interrupt call exception";
CM_ SG_ 919 EPASTP_a104_exhaBusMpuException "EPASTP ECU: a104 exha bus mpu exception";
CM_ SG_ 919 EPASTP_a105_exhaSriBusErrExcepti "EPASTP ECU: a105 exha sri bus err exception";
CM_ SG_ 919 EPASTP_a106_exhaSpbBusErrExcepti "EPASTP ECU: a106 exha spb bus err exception";
CM_ SG_ 919 EPASTP_a107_exhaOtherNmiExceptio "EPASTP ECU: a107 exha other nmi exception";
CM_ SG_ 919 EPASTP_a108_exhaInternalProtecti "EPASTP ECU: a108 exha internal protection exception";
CM_ SG_ 919 EPASTP_a109_exhaSysBusOrPeriphEr "EPASTP ECU: a109 exha sys bus or periph err exception";
CM_ SG_ 919 EPASTP_a110_amPhaseRelaySwitchOf "EPASTP ECU: a110 am phase relay switch off test";
CM_ SG_ 919 EPASTP_a111_amCurrentSensingDisc "EPASTP ECU: a111 am current sensing disconnection";
CM_ SG_ 919 EPASTP_a112_rsthSafetyFlipflopEr "EPASTP ECU: a112 rsth safety flipflop err";
CM_ SG_ 919 EPASTP_a113_rsthUncorrectableEnd "EPASTP ECU: a113 rsth uncorrectable end to end bus err";
CM_ SG_ 919 EPASTP_a114_osehOsErr "EPASTP ECU: a114 oseh os err";
CM_ SG_ 919 EPASTP_a115_mcusscLbistSingleFai "EPASTP ECU: a115 mcussc lbist single fail";
CM_ SG_ 919 EPASTP_a116_mrccStartupRegCsErro "EPASTP ECU: a116 mrcc startup reg cs error static err";
CM_ SG_ 919 EPASTP_a117_mrccStartupRegCsErro "EPASTP ECU: a117 mrcc startup reg cs error transient err";
CM_ SG_ 919 EPASTP_a118_mcusscFlashCsErrorEr "EPASTP ECU: a118 mcussc flash cs error err";
CM_ SG_ 919 EPASTP_a119_mcusscFlashEccCritic "EPASTP ECU: a119 mcussc flash ecc critical err";
CM_ SG_ 919 EPASTP_a120_mcusscFlashEccLatent "EPASTP ECU: a120 mcussc flash ecc latent err";
CM_ SG_ 919 EPASTP_a121_mcusscMbistEccErr "EPASTP ECU: a121 mcussc mbist ecc err";
CM_ SG_ 919 EPASTP_a122_pcpBridgeFetShort "EPASTP ECU: a122 pcp bridge fet short";
CM_ SG_ 919 EPASTP_a123_imcmCommErr "EPASTP ECU: a123 imcm comm err";
CM_ SG_ 919 EPASTP_a124_mcusscMbistEccTransi "EPASTP ECU: a124 mcussc mbist ecc transient err";
CM_ SG_ 919 EPASTP_a125_mcusscMbistMiaErr "EPASTP ECU: a125 mcussc mbist mia err";
CM_ SG_ 919 EPASTP_a126_mcusscMonbistMiaErr "EPASTP ECU: a126 mcussc monbist mia err";
CM_ SG_ 919 EPASTP_a127_exchAdditionalExcept "EPASTP ECU: a127 exch additional exception after rst";
CM_ SG_ 919 EPASTP_a128_exchExceptionStopRes "EPASTP ECU: a128 exch exception stop restart";
CM_ SG_ 919 EPASTP_a129_exchAdditionalExcept "EPASTP ECU: a129 exch additional exception stop restart";
CM_ SG_ 919 EPASTP_a130_mrccConfigCsErrorErr "EPASTP ECU: a130 mrcc config cs error err";
CM_ SG_ 919 EPASTP_a131_exchGuardedResetAfte "EPASTP ECU: a131 exch guarded reset after partition stop";
CM_ SG_ 919 EPASTP_a132_mcusscNotSupportedMc "EPASTP ECU: a132 mcussc not supported mcu";
CM_ SG_ 919 EPASTP_a133_mcusscLbistEcuIdIsNo "EPASTP ECU: a133 mcussc lbist ecu id is not supported";
CM_ SG_ 919 EPASTP_a134_osehGuardedResetAfte "EPASTP ECU: a134 oseh guarded reset after err without reset";
CM_ SG_ 919 EPASTP_a135_tmpsfetjCalculationO "EPASTP ECU: a135 tmpsfetj calculation overflow err";
CM_ SG_ 919 EPASTP_a136_ftElectricalAngleQf "EPASTP ECU: a136 ft electrical angle qf";
CM_ SG_ 919 EPASTP_a137_osehErrWithoutImmedi "EPASTP ECU: a137 oseh err without immediate reset";
CM_ SG_ 919 EPASTP_a138_osehAdditionalErrWit "EPASTP ECU: a138 oseh additional err without imm reset";
CM_ SG_ 919 EPASTP_a139_osehAdditionalOsErr "EPASTP ECU: a139 oseh additional os err";
CM_ SG_ 919 EPASTP_a140_imcmConfigurationErr "EPASTP ECU: a140 imcm configuration err";
CM_ SG_ 919 EPASTP_a141_amFetShortTest "EPASTP ECU: a141 am fet short test";
CM_ SG_ 919 EPASTP_a142_tedEmifilterDmcTempC "EPASTP ECU: a142 ted emifilter dmc temp checker";
CM_ SG_ 919 EPASTP_a143_tedEmifilterCmcTempC "EPASTP ECU: a143 ted emifilter cmc temp checker";
CM_ SG_ 919 EPASTP_a144_mriCoreRaminitFailed "EPASTP ECU: a144 mri core raminit failed";
CM_ SG_ 919 EPASTP_a145_mriPeripheralRaminit "EPASTP ECU: a145 mri peripheral raminit failed";
CM_ SG_ 919 EPASTP_a146_btarcRcCircuitCheck "EPASTP ECU: a146 btarc rc circuit check";
CM_ SG_ 919 EPASTP_a147_amDcLinkShortedFail "EPASTP ECU: a147 am dc link shorted fail";
CM_ SG_ 919 EPASTP_a148_mrccExitFromStandbyD "EPASTP ECU: a148 mrcc exit from standby detected";
CM_ SG_ 919 EPASTP_a149_amReversibleEmergenc "EPASTP ECU: a149 am reversible emergency off requested";
CM_ SG_ 919 EPASTP_a150_amExternalEmergencyO "EPASTP ECU: a150 am external emergency off requested";
CM_ SG_ 919 EPASTP_a151_amPermanentEmergency "EPASTP ECU: a151 am permanent emergency off requested";
CM_ SG_ 919 EPASTP_a152_exchFlashEccExceptio "EPASTP ECU: a152 exch flash ecc exception";
CM_ SG_ 919 EPASTP_a153_sdsmBlockSelectorInv "EPASTP ECU: a153 sdsm block selector invalid";
CM_ SG_ 919 EPASTP_a154_sdsmCsErrorInvalidPr "EPASTP ECU: a154 sdsm cs error invalid primary";
CM_ SG_ 919 EPASTP_a155_sdsmDataInvalidAll "EPASTP ECU: a155 sdsm data invalid all";
CM_ SG_ 919 EPASTP_a156_amIntSerialErrSafety "EPASTP ECU: a156 am int serial err safety reset";
CM_ SG_ 919 EPASTP_a157_mcudcpInvalidEcuId "EPASTP ECU: a157 mcudcp invalid ecu id";
CM_ SG_ 919 EPASTP_a158_amGduFailDuringRecov "EPASTP ECU: a158 am gdu fail during recovery";
CM_ SG_ 919 EPASTP_a159_exchFlashWordlineTra "EPASTP ECU: a159 exch flash wordline transient err";
CM_ SG_ 919 EPASTP_a160_rsthCpu1UnexpectedAl "EPASTP ECU: a160 rsth cpu1 unexpected alarm";
CM_ SG_ 919 EPASTP_a161_tdaRelayfetjunctionT "EPASTP ECU: a161 tda relayfetjunction temp checker";
CM_ SG_ 919 EPASTP_a162_tdaBridgefetjunction "EPASTP ECU: a162 tda bridgefetjunction temp checker";
CM_ SG_ 919 EPASTP_a163_tdaPowermoduleTempCh "EPASTP ECU: a163 tda powermodule temp checker";
CM_ SG_ 919 EPASTP_a164_tdaBattfetjunctionTe "EPASTP ECU: a164 tda battfetjunction temp checker";
CM_ SG_ 919 EPASTP_a165_tdaDcbusshuntTempChe "EPASTP ECU: a165 tda dcbusshunt temp checker";
CM_ SG_ 919 EPASTP_a166_tdaPhasecurrentshunt "EPASTP ECU: a166 tda phasecurrentshunt temp checker";
CM_ SG_ 919 EPASTP_a167_iccd1ErrQueueOverflo "EPASTP ECU: a167 iccd1 err queue overflow";
CM_ SG_ 919 EPASTP_a168_c1csInvalidC1App "EPASTP ECU: a168 c1cs invalid C1 app";
CM_ SG_ 919 EPASTP_a169_scpSafetyReset "EPASTP ECU: a169 scp safety reset";
CM_ SG_ 919 EPASTP_a170_pmpDcvoltAge "EPASTP ECU: a170 pmp dcvolt age";
CM_ SG_ 919 EPASTP_a171_pmpKgvalueAge "EPASTP ECU: a171 pmp kgvalue age";
CM_ SG_ 919 EPASTP_a172_pmpElangMotorcurrent "EPASTP ECU: a172 pmp elang motorcurrent age";
CM_ SG_ 919 EPASTP_a173_pmpRotorspeedAge "EPASTP ECU: a173 pmp rotorspeed age";
CM_ SG_ 919 EPASTP_a174_pmpPhasecurrentAge "EPASTP ECU: a174 pmp phasecurrent age";
CM_ SG_ 919 EPASTP_a175_exchFlashStoredConfi "EPASTP ECU: a175 exch flash stored config err";
CM_ SG_ 919 EPASTP_a176_exchCpu1ExceptionRes "EPASTP ECU: a176 exch cpu1 exception reset";
CM_ SG_ 919 EPASTP_a177_etsrInvalidated "EPASTP ECU: a177 etsr invalidated";
CM_ SG_ 919 EPASTP_a178_exchWdtException "EPASTP ECU: a178 exch wdt exception";
CM_ SG_ 919 EPASTP_a179_tedMotorcoilTempChec "EPASTP ECU: a179 ted motorcoil temp checker";
CM_ SG_ 919 EPASTP_a180_dmDeadlineViolationC "EPASTP ECU: a180 dm deadline violation C1";
CM_ SG_ 919 EPASTP_a181_dmDeadlineViolationC "EPASTP ECU: a181 dm deadline violation C1";
CM_ SG_ 919 EPASTP_a182_mcdInputMia "EPASTP ECU: a182 mcd input mia";
CM_ SG_ 919 EPASTP_a183_sbchCommErrSbcToMcu "EPASTP ECU: a183 sbch comm err sbc to mcu";
CM_ SG_ 919 EPASTP_a184_sbcmCommBufferOverfl "EPASTP ECU: a184 sbcm comm buffer overflow";
CM_ SG_ 919 EPASTP_a185_sbcscpQAWatchdogRese "EPASTP ECU: a185 sbcscp QA watchdog reset";
CM_ SG_ 919 EPASTP_a186_wdhCommBufferOverflo "EPASTP ECU: a186 wdh comm buffer overflow";
CM_ SG_ 919 EPASTP_a187_epmVoltFail "EPASTP ECU: a187 epm volt fail";
CM_ SG_ 919 EPASTP_a188_epmCommBufferOverflo "EPASTP ECU: a188 epm comm buffer overflow";
CM_ SG_ 919 EPASTP_a189_sbchCommErrMcuToSbc "EPASTP ECU: a189 sbch comm err mcu to sbc";
CM_ SG_ 919 EPASTP_a190_sbchCommBufferOverfl "EPASTP ECU: a190 sbch comm buffer overflow";
CM_ SG_ 919 EPASTP_a191_sbcscpVcp2VucVoltFai "EPASTP ECU: a191 sbcscp vcp2 vuc volt fail";
CM_ SG_ 919 EPASTP_a192_osumC0CsaNearFull "EPASTP ECU: a192 osum C0 csa near full";
CM_ SG_ 919 EPASTP_a193_osumC0StackNearFull "EPASTP ECU: a193 osum C0 stack near full";
CM_ SG_ 919 EPASTP_a194_amNvdataLoss "EPASTP ECU: a194 am nvdata loss";
CM_ SG_ 919 EPASTP_a195_imcmCommErrC1 "EPASTP ECU: a195 imcm comm err C1";
CM_ SG_ 919 EPASTP_a196_topEolTasOffsetInval "EPASTP ECU: a196 top eol tas offset invalid";
CM_ SG_ 919 EPASTP_a197_difpDifactorInvalid "EPASTP ECU: a197 difp difactor invalid";
CM_ SG_ 919 EPASTP_a198_osumC1CsaNearFull "EPASTP ECU: a198 osum C1 csa near full";
CM_ SG_ 919 EPASTP_a199_osumC1StackNearFull "EPASTP ECU: a199 osum C1 stack near full";
CM_ SG_ 919 EPASTP_a200_ammInputBufferOverfl "EPASTP ECU: a200 amm input buffer overflow";
CM_ SG_ 919 EPASTP_a201_ammOutputBufferOverf "EPASTP ECU: a201 amm output buffer overflow";
CM_ SG_ 919 EPASTP_a202_ohnvmpStoredOffsetLo "EPASTP ECU: a202 ohnvmp stored offset lost";
CM_ SG_ 919 EPASTP_a203_ctcInterfaceErr "EPASTP ECU: a203 ctc interface err";
CM_ SG_ 919 EPASTP_a204_fdpPrevTrqErr "EPASTP ECU: a204 fdp prev trq err";
CM_ SG_ 919 EPASTP_a205_fdrOclFail "EPASTP ECU: a205 fdr ocl fail";
CM_ SG_ 919 EPASTP_a206_fdrOclPartialBlockin "EPASTP ECU: a206 fdr ocl partial blocking";
CM_ SG_ 919 EPASTP_a207_fdrOclFreezing "EPASTP ECU: a207 fdr ocl freezing";
CM_ SG_ 919 EPASTP_a208_fdrLowSeverityBlocki "EPASTP ECU: a208 fdr low severity blocking";
CM_ SG_ 919 EPASTP_a209_fdrLowSeverityFreezi "EPASTP ECU: a209 fdr low severity freezing";
CM_ SG_ 919 EPASTP_a210_fdrTotalBlocking "EPASTP ECU: a210 fdr total blocking";
CM_ SG_ 919 EPASTP_a211_frmInternalErr "EPASTP ECU: a211 frm internal err";
CM_ SG_ 919 EPASTP_a212_frmDataLost "EPASTP ECU: a212 frm data lost";
CM_ SG_ 919 EPASTP_a213_frmHighFrictionDetec "EPASTP ECU: a213 frm high friction detected";
CM_ SG_ 919 EPASTP_a214_velInterfaceErr "EPASTP ECU: a214 vel interface err";
CM_ SG_ 919 EPASTP_a215_vsgSafeViolErr "EPASTP ECU: a215 vsg safe viol err";
CM_ SG_ 919 EPASTP_a216_isdgImproperShutdown "EPASTP ECU: a216 isdg improper shutdown";
CM_ SG_ 919 EPASTP_a217_msdMasterSilentErr "EPASTP ECU: a217 msd master silent err";
CM_ SG_ 919 EPASTP_a218_aadApplicationStateE "EPASTP ECU: a218 aad application state err";
CM_ SG_ 919 EPASTP_a219_frhFastRestartFailed "EPASTP ECU: a219 frh fast restart failed";
CM_ SG_ 919 EPASTP_a221_apsCntError "EPASTP ECU: a221 aps cnt error";
CM_ SG_ 919 EPASTP_a222_apsCsError "EPASTP ECU: a222 aps cs error";
CM_ SG_ 919 EPASTP_a223_apsMia "EPASTP ECU: a223 aps mia";
CM_ SG_ 919 EPASTP_a224_dasCntError "EPASTP ECU: a224 das cnt error";
CM_ SG_ 919 EPASTP_a225_dasCsError "EPASTP ECU: a225 das cs error";
CM_ SG_ 919 EPASTP_a226_dasMia "EPASTP ECU: a226 das mia";
CM_ SG_ 919 EPASTP_a227_dirTorqueCntError "EPASTP ECU: a227 dir torque cnt error";
CM_ SG_ 919 EPASTP_a228_dirTorqueCsError "EPASTP ECU: a228 dir torque cs error";
CM_ SG_ 919 EPASTP_a229_dirTorqueMia "EPASTP ECU: a229 dir torque mia";
CM_ SG_ 919 EPASTP_a230_diSpdCntError "EPASTP ECU: a230 di spd cnt error";
CM_ SG_ 919 EPASTP_a231_diSpdCsError "EPASTP ECU: a231 di spd cs error";
CM_ SG_ 919 EPASTP_a232_diSpdMia "EPASTP ECU: a232 di spd mia";
CM_ SG_ 919 EPASTP_a233_ecu2StatCntError "EPASTP ECU: a233 ecu2 stat cnt error";
CM_ SG_ 919 EPASTP_a234_ecu2StatCsError "EPASTP ECU: a234 ecu2 stat cs error";
CM_ SG_ 919 EPASTP_a235_ecu2StatMia "EPASTP ECU: a235 ecu2 stat mia";
CM_ SG_ 919 EPASTP_a236_espWrCntError "EPASTP ECU: a236 esp wr cnt error";
CM_ SG_ 919 EPASTP_a237_espWrCsError "EPASTP ECU: a237 esp wr cs error";
CM_ SG_ 919 EPASTP_a238_espWrMia "EPASTP ECU: a238 esp wr mia";
CM_ SG_ 919 EPASTP_a239_espWsCntError "EPASTP ECU: a239 esp ws cnt error";
CM_ SG_ 919 EPASTP_a240_espWsCsError "EPASTP ECU: a240 esp ws cs error";
CM_ SG_ 919 EPASTP_a241_espWsMia "EPASTP ECU: a241 esp ws mia";
CM_ SG_ 919 EPASTP_a242_gtwConfigMia "EPASTP ECU: a242 gtw config mia";
CM_ SG_ 919 EPASTP_a243_rcmCntError "EPASTP ECU: a243 rcm cnt error";
CM_ SG_ 919 EPASTP_a244_rcmCsError "EPASTP ECU: a244 rcm cs error";
CM_ SG_ 919 EPASTP_a245_rcmMia "EPASTP ECU: a245 rcm mia";
CM_ SG_ 919 EPASTP_a246_sccmCntError "EPASTP ECU: a246 sccm cnt error";
CM_ SG_ 919 EPASTP_a247_sccmCsError "EPASTP ECU: a247 sccm cs error";
CM_ SG_ 919 EPASTP_a248_sccmMia "EPASTP ECU: a248 sccm mia";
CM_ SG_ 919 EPASTP_a249_uiTuneReqCntError "EPASTP ECU: a249 ui tune req cnt error";
CM_ SG_ 919 EPASTP_a250_uiTuneReqCsError "EPASTP ECU: a250 ui tune req cs error";
CM_ SG_ 919 EPASTP_a251_uiTuneReqMia "EPASTP ECU: a251 ui tune req mia";
CM_ SG_ 919 EPASTP_a252_vcFrontCntError "EPASTP ECU: a252 vc front cnt error";
CM_ SG_ 919 EPASTP_a253_vcFrontCsError "EPASTP ECU: a253 vc front cs error";
CM_ SG_ 919 EPASTP_a254_vcFrontMia "EPASTP ECU: a254 vc front mia";
CM_ SG_ 919 EPASTP_a255_pmState2Mia "EPASTP ECU: a255 pm state2 mia";
CM_ SG_ 919 EPASTP_a256_dcvmOverVolt "EPASTP ECU: a256 dcvm over volt";
CM_ SG_ 919 EPASTP_a257_dcvmUnderVolt "EPASTP ECU: a257 dcvm under volt";
CM_ SG_ 919 EPASTP_a258_pspInvalidProjectPar "EPASTP ECU: a258 psp invalid project paramset";
CM_ SG_ 919 EPASTP_a259_scoCanBusOff "EPASTP ECU: a259 sco can bus off";
CM_ SG_ 919 EPASTP_a260_scoPrivateBusOff "EPASTP ECU: a260 sco private bus off";
CM_ SG_ 919 EPASTP_a261_sccmStatusError "EPASTP ECU: a261 sccm status error";
CM_ SG_ 919 EPASTP_a262_yawRateStatus "EPASTP ECU: a262 yaw rate status";
CM_ SG_ 919 EPASTP_a263_espWsStatus "EPASTP ECU: a263 esp ws status";
CM_ SG_ 919 EPASTP_a264_assistTorqueLimited "EPASTP ECU: a264 assist torque limited";
CM_ SG_ 919 EPASTP_a265_overheatProtect "EPASTP ECU: a265 overheat protect";
CM_ SG_ 919 EPASTP_a266_overloadProtect "EPASTP ECU: a266 overload protect";
CM_ SG_ 919 EPASTP_a267_safeSpeedAssist "EPASTP ECU: a267 safe speed assist";
CM_ SG_ 919 EPASTP_a268_eacCancelled "EPASTP ECU: a268 eac cancelled";
CM_ SG_ 919 EPASTP_a269_assistTorqueDisabled "EPASTP ECU: a269 assist torque disabled";
CM_ SG_ 919 EPASTP_a270_oscillationCompTrqLi "EPASTP ECU: a270 oscillation comp trq lim reached";
CM_ BO_ 1428 "EPASTS ECU message: alert log";
CM_ SG_ 1428 EPASTS_alertID "EPASTS ECU: alert ID";
CM_ SG_ 1428 EPASTS_alertState "EPASTS ECU: alert state";
CM_ SG_ 1428 EPASTS_a001_debugInfo "EPASTS ECU: a001 debug info";
CM_ SG_ 1428 EPASTS_a002_debugInfo "EPASTS ECU: a002 debug info";
CM_ SG_ 1428 EPASTS_a003_debugInfo "EPASTS ECU: a003 debug info";
CM_ SG_ 1428 EPASTS_a004_debugInfo "EPASTS ECU: a004 debug info";
CM_ SG_ 1428 EPASTS_a005_debugInfo "EPASTS ECU: a005 debug info";
CM_ SG_ 1428 EPASTS_a006_debugInfo "EPASTS ECU: a006 debug info";
CM_ SG_ 1428 EPASTS_a007_debugInfo "EPASTS ECU: a007 debug info";
CM_ SG_ 1428 EPASTS_a009_debugInfo "EPASTS ECU: a009 debug info";
CM_ SG_ 1428 EPASTS_a010_debugInfo "EPASTS ECU: a010 debug info";
CM_ SG_ 1428 EPASTS_a011_debugInfo "EPASTS ECU: a011 debug info";
CM_ SG_ 1428 EPASTS_a012_debugInfo "EPASTS ECU: a012 debug info";
CM_ SG_ 1428 EPASTS_a013_debugInfo "EPASTS ECU: a013 debug info";
CM_ SG_ 1428 EPASTS_a014_debugInfo "EPASTS ECU: a014 debug info";
CM_ SG_ 1428 EPASTS_a015_debugInfo "EPASTS ECU: a015 debug info";
CM_ SG_ 1428 EPASTS_a016_debugInfo "EPASTS ECU: a016 debug info";
CM_ SG_ 1428 EPASTS_a017_debugInfo "EPASTS ECU: a017 debug info";
CM_ SG_ 1428 EPASTS_a018_debugInfo "EPASTS ECU: a018 debug info";
CM_ SG_ 1428 EPASTS_a019_debugInfo "EPASTS ECU: a019 debug info";
CM_ SG_ 1428 EPASTS_a020_debugInfo "EPASTS ECU: a020 debug info";
CM_ SG_ 1428 EPASTS_a021_debugInfo "EPASTS ECU: a021 debug info";
CM_ SG_ 1428 EPASTS_a022_debugInfo "EPASTS ECU: a022 debug info";
CM_ SG_ 1428 EPASTS_a023_debugInfo "EPASTS ECU: a023 debug info";
CM_ SG_ 1428 EPASTS_a024_debugInfo "EPASTS ECU: a024 debug info";
CM_ SG_ 1428 EPASTS_a025_debugInfo "EPASTS ECU: a025 debug info";
CM_ SG_ 1428 EPASTS_a026_debugInfo "EPASTS ECU: a026 debug info";
CM_ SG_ 1428 EPASTS_a027_debugInfo "EPASTS ECU: a027 debug info";
CM_ SG_ 1428 EPASTS_a028_debugInfo "EPASTS ECU: a028 debug info";
CM_ SG_ 1428 EPASTS_a029_debugInfo "EPASTS ECU: a029 debug info";
CM_ SG_ 1428 EPASTS_a030_debugInfo "EPASTS ECU: a030 debug info";
CM_ SG_ 1428 EPASTS_a031_debugInfo "EPASTS ECU: a031 debug info";
CM_ SG_ 1428 EPASTS_a032_debugInfo "EPASTS ECU: a032 debug info";
CM_ SG_ 1428 EPASTS_a033_debugInfo "EPASTS ECU: a033 debug info";
CM_ SG_ 1428 EPASTS_a034_debugInfo "EPASTS ECU: a034 debug info";
CM_ SG_ 1428 EPASTS_a035_debugInfo "EPASTS ECU: a035 debug info";
CM_ SG_ 1428 EPASTS_a036_debugInfo "EPASTS ECU: a036 debug info";
CM_ SG_ 1428 EPASTS_a037_debugInfo "EPASTS ECU: a037 debug info";
CM_ SG_ 1428 EPASTS_a038_debugInfo "EPASTS ECU: a038 debug info";
CM_ SG_ 1428 EPASTS_a039_debugInfo "EPASTS ECU: a039 debug info";
CM_ SG_ 1428 EPASTS_a040_debugInfo "EPASTS ECU: a040 debug info";
CM_ SG_ 1428 EPASTS_a041_debugInfo "EPASTS ECU: a041 debug info";
CM_ SG_ 1428 EPASTS_a042_debugInfo "EPASTS ECU: a042 debug info";
CM_ SG_ 1428 EPASTS_a043_debugInfo "EPASTS ECU: a043 debug info";
CM_ SG_ 1428 EPASTS_a044_debugInfo "EPASTS ECU: a044 debug info";
CM_ SG_ 1428 EPASTS_a045_debugInfo "EPASTS ECU: a045 debug info";
CM_ SG_ 1428 EPASTS_a046_debugInfo "EPASTS ECU: a046 debug info";
CM_ SG_ 1428 EPASTS_a047_debugInfo "EPASTS ECU: a047 debug info";
CM_ SG_ 1428 EPASTS_a048_debugInfo "EPASTS ECU: a048 debug info";
CM_ SG_ 1428 EPASTS_a049_debugInfo "EPASTS ECU: a049 debug info";
CM_ SG_ 1428 EPASTS_a050_debugInfo "EPASTS ECU: a050 debug info";
CM_ SG_ 1428 EPASTS_a051_debugInfo "EPASTS ECU: a051 debug info";
CM_ SG_ 1428 EPASTS_a052_debugInfo "EPASTS ECU: a052 debug info";
CM_ SG_ 1428 EPASTS_a053_debugInfo "EPASTS ECU: a053 debug info";
CM_ SG_ 1428 EPASTS_a054_debugInfo "EPASTS ECU: a054 debug info";
CM_ SG_ 1428 EPASTS_a055_debugInfo "EPASTS ECU: a055 debug info";
CM_ SG_ 1428 EPASTS_a056_debugInfo "EPASTS ECU: a056 debug info";
CM_ SG_ 1428 EPASTS_a057_debugInfo "EPASTS ECU: a057 debug info";
CM_ SG_ 1428 EPASTS_a058_debugInfo "EPASTS ECU: a058 debug info";
CM_ SG_ 1428 EPASTS_a059_debugInfo "EPASTS ECU: a059 debug info";
CM_ SG_ 1428 EPASTS_a060_debugInfo "EPASTS ECU: a060 debug info";
CM_ SG_ 1428 EPASTS_a061_debugInfo "EPASTS ECU: a061 debug info";
CM_ SG_ 1428 EPASTS_a062_debugInfo "EPASTS ECU: a062 debug info";
CM_ SG_ 1428 EPASTS_a063_debugInfo "EPASTS ECU: a063 debug info";
CM_ SG_ 1428 EPASTS_a064_debugInfo "EPASTS ECU: a064 debug info";
CM_ SG_ 1428 EPASTS_a065_debugInfo "EPASTS ECU: a065 debug info";
CM_ SG_ 1428 EPASTS_a066_debugInfo "EPASTS ECU: a066 debug info";
CM_ SG_ 1428 EPASTS_a067_debugInfo "EPASTS ECU: a067 debug info";
CM_ SG_ 1428 EPASTS_a068_debugInfo "EPASTS ECU: a068 debug info";
CM_ SG_ 1428 EPASTS_a069_debugInfo "EPASTS ECU: a069 debug info";
CM_ SG_ 1428 EPASTS_a070_debugInfo "EPASTS ECU: a070 debug info";
CM_ SG_ 1428 EPASTS_a071_debugInfo "EPASTS ECU: a071 debug info";
CM_ SG_ 1428 EPASTS_a072_debugInfo "EPASTS ECU: a072 debug info";
CM_ SG_ 1428 EPASTS_a073_debugInfo "EPASTS ECU: a073 debug info";
CM_ SG_ 1428 EPASTS_a074_debugInfo "EPASTS ECU: a074 debug info";
CM_ SG_ 1428 EPASTS_a075_debugInfo "EPASTS ECU: a075 debug info";
CM_ SG_ 1428 EPASTS_a076_debugInfo "EPASTS ECU: a076 debug info";
CM_ SG_ 1428 EPASTS_a077_debugInfo "EPASTS ECU: a077 debug info";
CM_ SG_ 1428 EPASTS_a078_debugInfo "EPASTS ECU: a078 debug info";
CM_ SG_ 1428 EPASTS_a079_debugInfo "EPASTS ECU: a079 debug info";
CM_ SG_ 1428 EPASTS_a080_debugInfo "EPASTS ECU: a080 debug info";
CM_ SG_ 1428 EPASTS_a081_debugInfo "EPASTS ECU: a081 debug info";
CM_ SG_ 1428 EPASTS_a082_debugInfo "EPASTS ECU: a082 debug info";
CM_ SG_ 1428 EPASTS_a083_debugInfo "EPASTS ECU: a083 debug info";
CM_ SG_ 1428 EPASTS_a084_debugInfo "EPASTS ECU: a084 debug info";
CM_ SG_ 1428 EPASTS_a085_debugInfo "EPASTS ECU: a085 debug info";
CM_ SG_ 1428 EPASTS_a086_debugInfo "EPASTS ECU: a086 debug info";
CM_ SG_ 1428 EPASTS_a087_debugInfo "EPASTS ECU: a087 debug info";
CM_ SG_ 1428 EPASTS_a088_debugInfo "EPASTS ECU: a088 debug info";
CM_ SG_ 1428 EPASTS_a089_debugInfo "EPASTS ECU: a089 debug info";
CM_ SG_ 1428 EPASTS_a090_debugInfo "EPASTS ECU: a090 debug info";
CM_ SG_ 1428 EPASTS_a091_debugInfo "EPASTS ECU: a091 debug info";
CM_ SG_ 1428 EPASTS_a092_debugInfo "EPASTS ECU: a092 debug info";
CM_ SG_ 1428 EPASTS_a093_debugInfo "EPASTS ECU: a093 debug info";
CM_ SG_ 1428 EPASTS_a094_debugInfo "EPASTS ECU: a094 debug info";
CM_ SG_ 1428 EPASTS_a095_debugInfo "EPASTS ECU: a095 debug info";
CM_ SG_ 1428 EPASTS_a096_debugInfo "EPASTS ECU: a096 debug info";
CM_ SG_ 1428 EPASTS_a097_debugInfo "EPASTS ECU: a097 debug info";
CM_ SG_ 1428 EPASTS_a098_debugInfo "EPASTS ECU: a098 debug info";
CM_ SG_ 1428 EPASTS_a099_debugInfo "EPASTS ECU: a099 debug info";
CM_ SG_ 1428 EPASTS_a100_debugInfo "EPASTS ECU: a100 debug info";
CM_ SG_ 1428 EPASTS_a101_debugInfo "EPASTS ECU: a101 debug info";
CM_ SG_ 1428 EPASTS_a102_debugInfo "EPASTS ECU: a102 debug info";
CM_ SG_ 1428 EPASTS_a103_debugInfo "EPASTS ECU: a103 debug info";
CM_ SG_ 1428 EPASTS_a104_debugInfo "EPASTS ECU: a104 debug info";
CM_ SG_ 1428 EPASTS_a105_debugInfo "EPASTS ECU: a105 debug info";
CM_ SG_ 1428 EPASTS_a106_debugInfo "EPASTS ECU: a106 debug info";
CM_ SG_ 1428 EPASTS_a107_debugInfo "EPASTS ECU: a107 debug info";
CM_ SG_ 1428 EPASTS_a108_debugInfo "EPASTS ECU: a108 debug info";
CM_ SG_ 1428 EPASTS_a109_debugInfo "EPASTS ECU: a109 debug info";
CM_ SG_ 1428 EPASTS_a110_debugInfo "EPASTS ECU: a110 debug info";
CM_ SG_ 1428 EPASTS_a111_debugInfo "EPASTS ECU: a111 debug info";
CM_ SG_ 1428 EPASTS_a112_debugInfo "EPASTS ECU: a112 debug info";
CM_ SG_ 1428 EPASTS_a113_debugInfo "EPASTS ECU: a113 debug info";
CM_ SG_ 1428 EPASTS_a114_debugInfo "EPASTS ECU: a114 debug info";
CM_ SG_ 1428 EPASTS_a115_debugInfo "EPASTS ECU: a115 debug info";
CM_ SG_ 1428 EPASTS_a116_debugInfo "EPASTS ECU: a116 debug info";
CM_ SG_ 1428 EPASTS_a117_debugInfo "EPASTS ECU: a117 debug info";
CM_ SG_ 1428 EPASTS_a118_debugInfo "EPASTS ECU: a118 debug info";
CM_ SG_ 1428 EPASTS_a119_debugInfo "EPASTS ECU: a119 debug info";
CM_ SG_ 1428 EPASTS_a120_debugInfo "EPASTS ECU: a120 debug info";
CM_ SG_ 1428 EPASTS_a121_debugInfo "EPASTS ECU: a121 debug info";
CM_ SG_ 1428 EPASTS_a122_debugInfo "EPASTS ECU: a122 debug info";
CM_ SG_ 1428 EPASTS_a123_debugInfo "EPASTS ECU: a123 debug info";
CM_ SG_ 1428 EPASTS_a124_debugInfo "EPASTS ECU: a124 debug info";
CM_ SG_ 1428 EPASTS_a125_debugInfo "EPASTS ECU: a125 debug info";
CM_ SG_ 1428 EPASTS_a126_debugInfo "EPASTS ECU: a126 debug info";
CM_ SG_ 1428 EPASTS_a127_debugInfo "EPASTS ECU: a127 debug info";
CM_ SG_ 1428 EPASTS_a128_debugInfo "EPASTS ECU: a128 debug info";
CM_ SG_ 1428 EPASTS_a129_debugInfo "EPASTS ECU: a129 debug info";
CM_ SG_ 1428 EPASTS_a130_debugInfo "EPASTS ECU: a130 debug info";
CM_ SG_ 1428 EPASTS_a131_debugInfo "EPASTS ECU: a131 debug info";
CM_ SG_ 1428 EPASTS_a132_debugInfo "EPASTS ECU: a132 debug info";
CM_ SG_ 1428 EPASTS_a133_debugInfo "EPASTS ECU: a133 debug info";
CM_ SG_ 1428 EPASTS_a134_debugInfo "EPASTS ECU: a134 debug info";
CM_ SG_ 1428 EPASTS_a135_debugInfo "EPASTS ECU: a135 debug info";
CM_ SG_ 1428 EPASTS_a136_debugInfo "EPASTS ECU: a136 debug info";
CM_ SG_ 1428 EPASTS_a137_debugInfo "EPASTS ECU: a137 debug info";
CM_ SG_ 1428 EPASTS_a138_debugInfo "EPASTS ECU: a138 debug info";
CM_ SG_ 1428 EPASTS_a139_debugInfo "EPASTS ECU: a139 debug info";
CM_ SG_ 1428 EPASTS_a140_debugInfo "EPASTS ECU: a140 debug info";
CM_ SG_ 1428 EPASTS_a141_debugInfo "EPASTS ECU: a141 debug info";
CM_ SG_ 1428 EPASTS_a142_debugInfo "EPASTS ECU: a142 debug info";
CM_ SG_ 1428 EPASTS_a143_debugInfo "EPASTS ECU: a143 debug info";
CM_ SG_ 1428 EPASTS_a144_debugInfo "EPASTS ECU: a144 debug info";
CM_ SG_ 1428 EPASTS_a145_debugInfo "EPASTS ECU: a145 debug info";
CM_ SG_ 1428 EPASTS_a146_debugInfo "EPASTS ECU: a146 debug info";
CM_ SG_ 1428 EPASTS_a147_debugInfo "EPASTS ECU: a147 debug info";
CM_ SG_ 1428 EPASTS_a148_debugInfo "EPASTS ECU: a148 debug info";
CM_ SG_ 1428 EPASTS_a149_debugInfo "EPASTS ECU: a149 debug info";
CM_ SG_ 1428 EPASTS_a150_debugInfo "EPASTS ECU: a150 debug info";
CM_ SG_ 1428 EPASTS_a152_debugInfo "EPASTS ECU: a152 debug info";
CM_ SG_ 1428 EPASTS_a153_debugInfo "EPASTS ECU: a153 debug info";
CM_ SG_ 1428 EPASTS_a154_debugInfo "EPASTS ECU: a154 debug info";
CM_ SG_ 1428 EPASTS_a155_debugInfo "EPASTS ECU: a155 debug info";
CM_ SG_ 1428 EPASTS_a156_debugInfo "EPASTS ECU: a156 debug info";
CM_ SG_ 1428 EPASTS_a157_debugInfo "EPASTS ECU: a157 debug info";
CM_ SG_ 1428 EPASTS_a158_debugInfo "EPASTS ECU: a158 debug info";
CM_ SG_ 1428 EPASTS_a159_debugInfo "EPASTS ECU: a159 debug info";
CM_ SG_ 1428 EPASTS_a160_debugInfo "EPASTS ECU: a160 debug info";
CM_ SG_ 1428 EPASTS_a161_debugInfo "EPASTS ECU: a161 debug info";
CM_ SG_ 1428 EPASTS_a162_debugInfo "EPASTS ECU: a162 debug info";
CM_ SG_ 1428 EPASTS_a163_debugInfo "EPASTS ECU: a163 debug info";
CM_ SG_ 1428 EPASTS_a164_debugInfo "EPASTS ECU: a164 debug info";
CM_ SG_ 1428 EPASTS_a165_debugInfo "EPASTS ECU: a165 debug info";
CM_ SG_ 1428 EPASTS_a166_debugInfo "EPASTS ECU: a166 debug info";
CM_ SG_ 1428 EPASTS_a167_debugInfo "EPASTS ECU: a167 debug info";
CM_ SG_ 1428 EPASTS_a168_debugInfo "EPASTS ECU: a168 debug info";
CM_ SG_ 1428 EPASTS_a169_debugInfo "EPASTS ECU: a169 debug info";
CM_ SG_ 1428 EPASTS_a170_debugInfo "EPASTS ECU: a170 debug info";
CM_ SG_ 1428 EPASTS_a171_debugInfo "EPASTS ECU: a171 debug info";
CM_ SG_ 1428 EPASTS_a172_debugInfo "EPASTS ECU: a172 debug info";
CM_ SG_ 1428 EPASTS_a173_debugInfo "EPASTS ECU: a173 debug info";
CM_ SG_ 1428 EPASTS_a174_debugInfo "EPASTS ECU: a174 debug info";
CM_ SG_ 1428 EPASTS_a175_debugInfo "EPASTS ECU: a175 debug info";
CM_ SG_ 1428 EPASTS_a176_debugInfo "EPASTS ECU: a176 debug info";
CM_ SG_ 1428 EPASTS_a177_debugInfo "EPASTS ECU: a177 debug info";
CM_ SG_ 1428 EPASTS_a178_debugInfo "EPASTS ECU: a178 debug info";
CM_ SG_ 1428 EPASTS_a179_debugInfo "EPASTS ECU: a179 debug info";
CM_ SG_ 1428 EPASTS_a180_debugInfo "EPASTS ECU: a180 debug info";
CM_ SG_ 1428 EPASTS_a181_debugInfo "EPASTS ECU: a181 debug info";
CM_ SG_ 1428 EPASTS_a182_debugInfo "EPASTS ECU: a182 debug info";
CM_ SG_ 1428 EPASTS_a183_debugInfo "EPASTS ECU: a183 debug info";
CM_ SG_ 1428 EPASTS_a184_debugInfo "EPASTS ECU: a184 debug info";
CM_ SG_ 1428 EPASTS_a185_debugInfo "EPASTS ECU: a185 debug info";
CM_ SG_ 1428 EPASTS_a186_debugInfo "EPASTS ECU: a186 debug info";
CM_ SG_ 1428 EPASTS_a188_debugInfo "EPASTS ECU: a188 debug info";
CM_ SG_ 1428 EPASTS_a189_debugInfo "EPASTS ECU: a189 debug info";
CM_ SG_ 1428 EPASTS_a190_debugInfo "EPASTS ECU: a190 debug info";
CM_ SG_ 1428 EPASTS_a191_debugInfo "EPASTS ECU: a191 debug info";
CM_ SG_ 1428 EPASTS_a192_debugInfo "EPASTS ECU: a192 debug info";
CM_ SG_ 1428 EPASTS_a193_debugInfo "EPASTS ECU: a193 debug info";
CM_ SG_ 1428 EPASTS_a194_debugInfo "EPASTS ECU: a194 debug info";
CM_ SG_ 1428 EPASTS_a195_debugInfo "EPASTS ECU: a195 debug info";
CM_ SG_ 1428 EPASTS_a196_debugInfo "EPASTS ECU: a196 debug info";
CM_ SG_ 1428 EPASTS_a197_debugInfo "EPASTS ECU: a197 debug info";
CM_ SG_ 1428 EPASTS_a198_debugInfo "EPASTS ECU: a198 debug info";
CM_ SG_ 1428 EPASTS_a199_debugInfo "EPASTS ECU: a199 debug info";
CM_ SG_ 1428 EPASTS_a200_debugInfo "EPASTS ECU: a200 debug info";
CM_ SG_ 1428 EPASTS_a201_debugInfo "EPASTS ECU: a201 debug info";
CM_ SG_ 1428 EPASTS_a202_debugInfo "EPASTS ECU: a202 debug info";
CM_ SG_ 1428 EPASTS_a203_debugInfo "EPASTS ECU: a203 debug info";
CM_ SG_ 1428 EPASTS_a204_debugInfo "EPASTS ECU: a204 debug info";
CM_ SG_ 1428 EPASTS_a205_debugInfo "EPASTS ECU: a205 debug info";
CM_ SG_ 1428 EPASTS_a206_debugInfo "EPASTS ECU: a206 debug info";
CM_ SG_ 1428 EPASTS_a207_debugInfo "EPASTS ECU: a207 debug info";
CM_ SG_ 1428 EPASTS_a208_debugInfo "EPASTS ECU: a208 debug info";
CM_ SG_ 1428 EPASTS_a209_debugInfo "EPASTS ECU: a209 debug info";
CM_ SG_ 1428 EPASTS_a210_debugInfo "EPASTS ECU: a210 debug info";
CM_ SG_ 1428 EPASTS_a211_debugInfo "EPASTS ECU: a211 debug info";
CM_ SG_ 1428 EPASTS_a212_debugInfo "EPASTS ECU: a212 debug info";
CM_ SG_ 1428 EPASTS_a213_debugInfo "EPASTS ECU: a213 debug info";
CM_ SG_ 1428 EPASTS_a214_debugInfo "EPASTS ECU: a214 debug info";
CM_ SG_ 1428 EPASTS_a215_debugInfo "EPASTS ECU: a215 debug info";
CM_ SG_ 1428 EPASTS_a216_debugInfo "EPASTS ECU: a216 debug info";
CM_ SG_ 1428 EPASTS_a217_debugInfo "EPASTS ECU: a217 debug info";
CM_ SG_ 1428 EPASTS_a218_debugInfo "EPASTS ECU: a218 debug info";
CM_ SG_ 1428 EPASTS_a219_debugInfo "EPASTS ECU: a219 debug info";
CM_ SG_ 1428 EPASTS_a220_debugInfo "EPASTS ECU: a220 debug info";
CM_ SG_ 1428 EPASTS_a221_debugInfo "EPASTS ECU: a221 debug info";
CM_ SG_ 1428 EPASTS_a222_debugInfo "EPASTS ECU: a222 debug info";
CM_ SG_ 1428 EPASTS_a223_debugInfo "EPASTS ECU: a223 debug info";
CM_ SG_ 1428 EPASTS_a224_debugInfo "EPASTS ECU: a224 debug info";
CM_ SG_ 1428 EPASTS_a225_debugInfo "EPASTS ECU: a225 debug info";
CM_ SG_ 1428 EPASTS_a226_debugInfo "EPASTS ECU: a226 debug info";
CM_ SG_ 1428 EPASTS_a227_debugInfo "EPASTS ECU: a227 debug info";
CM_ SG_ 1428 EPASTS_a228_debugInfo "EPASTS ECU: a228 debug info";
CM_ SG_ 1428 EPASTS_a229_debugInfo "EPASTS ECU: a229 debug info";
CM_ SG_ 1428 EPASTS_a230_debugInfo "EPASTS ECU: a230 debug info";
CM_ SG_ 1428 EPASTS_a231_debugInfo "EPASTS ECU: a231 debug info";
CM_ SG_ 1428 EPASTS_a232_debugInfo "EPASTS ECU: a232 debug info";
CM_ SG_ 1428 EPASTS_a233_debugInfo "EPASTS ECU: a233 debug info";
CM_ SG_ 1428 EPASTS_a234_debugInfo "EPASTS ECU: a234 debug info";
CM_ SG_ 1428 EPASTS_a235_debugInfo "EPASTS ECU: a235 debug info";
CM_ SG_ 1428 EPASTS_a236_debugInfo "EPASTS ECU: a236 debug info";
CM_ SG_ 1428 EPASTS_a237_debugInfo "EPASTS ECU: a237 debug info";
CM_ SG_ 1428 EPASTS_a238_debugInfo "EPASTS ECU: a238 debug info";
CM_ SG_ 1428 EPASTS_a239_debugInfo "EPASTS ECU: a239 debug info";
CM_ SG_ 1428 EPASTS_a240_debugInfo "EPASTS ECU: a240 debug info";
CM_ SG_ 1428 EPASTS_a241_debugInfo "EPASTS ECU: a241 debug info";
CM_ SG_ 1428 EPASTS_a242_debugInfo "EPASTS ECU: a242 debug info";
CM_ SG_ 1428 EPASTS_a243_debugInfo "EPASTS ECU: a243 debug info";
CM_ SG_ 1428 EPASTS_a244_debugInfo "EPASTS ECU: a244 debug info";
CM_ SG_ 1428 EPASTS_a245_debugInfo "EPASTS ECU: a245 debug info";
CM_ SG_ 1428 EPASTS_a246_debugInfo "EPASTS ECU: a246 debug info";
CM_ SG_ 1428 EPASTS_a247_debugInfo "EPASTS ECU: a247 debug info";
CM_ SG_ 1428 EPASTS_a248_debugInfo "EPASTS ECU: a248 debug info";
CM_ SG_ 1428 EPASTS_a249_debugInfo "EPASTS ECU: a249 debug info";
CM_ SG_ 1428 EPASTS_a250_debugInfo "EPASTS ECU: a250 debug info";
CM_ SG_ 1428 EPASTS_a252_debugInfo "EPASTS ECU: a252 debug info";
CM_ SG_ 1428 EPASTS_a253_debugInfo "EPASTS ECU: a253 debug info";
CM_ SG_ 1428 EPASTS_a254_debugInfo "EPASTS ECU: a254 debug info";
CM_ SG_ 1428 EPASTS_a255_debugInfo "EPASTS ECU: a255 debug info";
CM_ SG_ 1428 EPASTS_a256_debugInfo "EPASTS ECU: a256 debug info";
CM_ SG_ 1428 EPASTS_a257_debugInfo "EPASTS ECU: a257 debug info";
CM_ SG_ 1428 EPASTS_a258_debugInfo "EPASTS ECU: a258 debug info";
CM_ SG_ 1428 EPASTS_a259_debugInfo "EPASTS ECU: a259 debug info";
CM_ SG_ 1428 EPASTS_a260_debugInfo "EPASTS ECU: a260 debug info";
CM_ SG_ 1428 EPASTS_a261_debugInfo "EPASTS ECU: a261 debug info";
CM_ SG_ 1428 EPASTS_a262_debugInfo "EPASTS ECU: a262 debug info";
CM_ SG_ 1428 EPASTS_a263_debugInfo "EPASTS ECU: a263 debug info";
CM_ SG_ 1428 EPASTS_a264_degradedECU "EPASTS ECU: a264 degraded ECU";
CM_ SG_ 1428 EPASTS_a264_vehicleSpeed "EPASTS ECU: a264 vehicle speed";
CM_ SG_ 1428 EPASTS_a264_powerRatio "EPASTS ECU: a264 power ratio";
CM_ SG_ 1428 EPASTS_a264_ownSideDegradationRe "EPASTS ECU: a264 own side degradation reason";
CM_ SG_ 1428 EPASTS_a264_otherSideDegradation "EPASTS ECU: a264 other side degradation reason";
CM_ SG_ 1428 EPASTS_a265_degradedECU "EPASTS ECU: a265 degraded ECU";
CM_ SG_ 1428 EPASTS_a265_vehicleSpeed "EPASTS ECU: a265 vehicle speed";
CM_ SG_ 1428 EPASTS_a265_rawMcuTemperature "EPASTS ECU: a265 raw mcu temperature";
CM_ SG_ 1428 EPASTS_a265_degradedCurrentLimit "EPASTS ECU: a265 degraded current limit";
CM_ SG_ 1428 EPASTS_a266_cdpAssistFactor "EPASTS ECU: a266 cdp assist factor";
CM_ SG_ 1428 EPASTS_a266_vehicleSpeed "EPASTS ECU: a266 vehicle speed";
CM_ SG_ 1428 EPASTS_a267_vehicleSpeed "EPASTS ECU: a267 vehicle speed";
CM_ SG_ 1428 EPASTS_a267_velocityEstimatorSta "EPASTS ECU: a267 velocity estimator state";
CM_ SG_ 1428 EPASTS_a269_vehicleSpeed "EPASTS ECU: a269 vehicle speed";
CM_ SG_ 1428 EPASTS_a270_debugInfo "EPASTS ECU: a270 debug info";
BA_DEF_ BO_ "GenMsgCycleTime" INT 0 3600000;
BA_DEF_ BO_ "GenMsgSendType" ENUM "Cyclic","NotUsed","NotUsed","NotUsed","NotUsed","NotUsed","NotUsed","IfActive","NoMsgSendType","NotUsed";
BA_DEF_ BO_ "VFrameFormat" ENUM "StandardCAN","ExtendedCAN","reserved","J1939PG","reserved","reserved","reserved","reserved","reserved","reserved","reserved","reserved","reserved","reserved","StandardCAN_FD","ExtendedCAN_FD";
BA_DEF_ BO_ "CANFD_BRS" ENUM "0","1";
BA_DEF_ SG_ "GenSigSNA" STRING;
BA_DEF_ SG_ "SystemSignalLongSymbol" STRING;
BA_DEF_ SG_ "Confidence" ENUM "validated","plausible","layout-only","contradicted";
BA_DEF_DEF_ "GenMsgCycleTime" 0;
BA_DEF_DEF_ "GenMsgSendType" "NoMsgSendType";
BA_DEF_DEF_ "VFrameFormat" "StandardCAN";
BA_DEF_DEF_ "CANFD_BRS" "1";
BA_DEF_DEF_ "GenSigSNA" "";
BA_DEF_DEF_ "SystemSignalLongSymbol" "";
BA_DEF_DEF_ "Confidence" "layout-only";
BA_ "GenMsgCycleTime" BO_ 785 1000;
BA_ "GenMsgSendType" BO_ 785 0;
BA_ "GenMsgCycleTime" BO_ 882 10;
BA_ "GenMsgSendType" BO_ 882 0;
BA_ "GenMsgCycleTime" BO_ 919 1000;
BA_ "GenMsgSendType" BO_ 919 0;
BA_ "Confidence" SG_ 785 EPAS3S_infoIndex 1;
BA_ "Confidence" SG_ 785 EPAS3S_infoBuildType 0;
BA_ "Confidence" SG_ 785 EPAS3S_infoComponentID 0;
BA_ "Confidence" SG_ 785 EPAS3S_infoPcbaID 0;
BA_ "Confidence" SG_ 785 EPAS3S_infoAssemblyID 0;
BA_ "Confidence" SG_ 785 EPAS3S_infoUsageID 0;
BA_ "Confidence" SG_ 785 EPAS3S_infoApplicationCRC 0;
BA_ "Confidence" SG_ 785 EPAS3S_infoBootUdsProtoVersion 0;
BA_ "Confidence" SG_ 785 EPAS3S_infoBootloaderCRC 0;
BA_ "Confidence" SG_ 785 EPAS3S_infoSubcomponent2 0;
BA_ "Confidence" SG_ 882 EPAS3S_steeringRackForce 1;
BA_ "GenSigSNA" SG_ 882 EPAS3S_steeringRackForce "1023";
BA_ "Confidence" SG_ 882 EPAS3S_steeringFault 1;
BA_ "Confidence" SG_ 882 EPAS3S_steeringReduced 1;
BA_ "Confidence" SG_ 882 EPAS3S_internalSASQF 1;
BA_ "Confidence" SG_ 882 EPAS3S_currentTuneMode 1;
BA_ "Confidence" SG_ 882 EPAS3S_torsionBarTorque 1;
BA_ "GenSigSNA" SG_ 882 EPAS3S_torsionBarTorque "4095";
BA_ "Confidence" SG_ 882 EPAS3S_eacErrorCode 1;
BA_ "GenSigSNA" SG_ 882 EPAS3S_eacErrorCode "15";
BA_ "Confidence" SG_ 882 EPAS3S_internalSAS 1;
BA_ "Confidence" SG_ 882 EPAS3S_handsOnLevel 1;
BA_ "Confidence" SG_ 882 EPAS3S_driverlessState 1;
BA_ "Confidence" SG_ 882 EPAS3S_eacStatus 1;
BA_ "Confidence" SG_ 1848 EPAS3S_udsResponseData 1;
BA_ "Confidence" SG_ 1427 EPASTP_alertID 1;
BA_ "Confidence" SG_ 1427 EPASTP_alertState 1;
BA_ "Confidence" SG_ 1427 EPASTP_a264_degradedECU 1;
BA_ "Confidence" SG_ 1427 EPASTP_a264_vehicleSpeed 1;
BA_ "Confidence" SG_ 1427 EPASTP_a264_powerRatio 1;
BA_ "Confidence" SG_ 1427 EPASTP_a264_ownSideDegradationRe 1;
BA_ "SystemSignalLongSymbol" SG_ 1427 EPASTP_a264_ownSideDegradationRe "EPASTP_a264_ownSideDegradationReason";
BA_ "Confidence" SG_ 1427 EPASTP_a264_otherSideDegradation 1;
BA_ "SystemSignalLongSymbol" SG_ 1427 EPASTP_a264_otherSideDegradation "EPASTP_a264_otherSideDegradationReason";
BA_ "Confidence" SG_ 1427 EPASTP_a265_degradedECU 1;
BA_ "Confidence" SG_ 1427 EPASTP_a265_vehicleSpeed 1;
BA_ "Confidence" SG_ 1427 EPASTP_a265_rawMcuTemperature 1;
BA_ "Confidence" SG_ 1427 EPASTP_a265_degradedCurrentLimit 1;
BA_ "Confidence" SG_ 1427 EPASTP_a266_cdpAssistFactor 1;
BA_ "Confidence" SG_ 1427 EPASTP_a266_vehicleSpeed 1;
BA_ "Confidence" SG_ 1427 EPASTP_a267_vehicleSpeed 1;
BA_ "Confidence" SG_ 1427 EPASTP_a267_velocityEstimatorSta 1;
BA_ "SystemSignalLongSymbol" SG_ 1427 EPASTP_a267_velocityEstimatorSta "EPASTP_a267_velocityEstimatorState";
BA_ "Confidence" SG_ 1427 EPASTP_a269_vehicleSpeed 1;
BA_ "Confidence" SG_ 919 EPASTP_matrixIndex 1;
BA_ "SystemSignalLongSymbol" SG_ 919 EPASTP_a001_adcCalibrationOrInit "EPASTP_a001_adcCalibrationOrInitFail";
BA_ "SystemSignalLongSymbol" SG_ 919 EPASTP_a005_scpUnknownResetSourc "EPASTP_a005_scpUnknownResetSource";
BA_ "SystemSignalLongSymbol" SG_ 919 EPASTP_a006_swrhResetByInvalidEr "EPASTP_a006_swrhResetByInvalidErrid";
BA_ "SystemSignalLongSymbol" SG_ 919 EPASTP_a009_mcusscLbistPermanent "EPASTP_a009_mcusscLbistPermanentFail";
BA_ "SystemSignalLongSymbol" SG_ 919 EPASTP_a010_svcIncompatibleSwVer "EPASTP_a010_svcIncompatibleSwVersions";
BA_ "SystemSignalLongSymbol" SG_ 919 EPASTP_a013_mcusscSffMonitoringF "EPASTP_a013_mcusscSffMonitoringFailed";
BA_ "SystemSignalLongSymbol" SG_ 919 EPASTP_a014_mcusscSffMonitoringM "EPASTP_a014_mcusscSffMonitoringMia";
BA_ "SystemSignalLongSymbol" SG_ 919 EPASTP_a015_mcusscCsErrorCheckFa "EPASTP_a015_mcusscCsErrorCheckFail";
BA_ "SystemSignalLongSymbol" SG_ 919 EPASTP_a016_mcufcCsErrorCheckFai "EPASTP_a016_mcufcCsErrorCheckFail";
BA_ "SystemSignalLongSymbol" SG_ 919 EPASTP_a017_stmdStmPlausibilityC "EPASTP_a017_stmdStmPlausibilityCheckErr";
BA_ "SystemSignalLongSymbol" SG_ 919 EPASTP_a019_rsthHwResetInfoCorru "EPASTP_a019_rsthHwResetInfoCorruptionCheck";
BA_ "SystemSignalLongSymbol" SG_ 919 EPASTP_a020_mcusscEolEcuIdIntegr "EPASTP_a020_mcusscEolEcuIdIntegritiyFail";
BA_ "SystemSignalLongSymbol" SG_ 919 EPASTP_a022_swrhSwResetInfoCorru "EPASTP_a022_swrhSwResetInfoCorruptionCheck";
BA_ "SystemSignalLongSymbol" SG_ 919 EPASTP_a028_smuhNonInitDataCorru "EPASTP_a028_smuhNonInitDataCorruption";
BA_ "SystemSignalLongSymbol" SG_ 919 EPASTP_a029_smuhSmuCoreCntErrorT "EPASTP_a029_smuhSmuCoreCntErrorTestFail";
BA_ "SystemSignalLongSymbol" SG_ 919 EPASTP_a031_pmsProductionModeFai "EPASTP_a031_pmsProductionModeFailed";
BA_ "SystemSignalLongSymbol" SG_ 919 EPASTP_a033_icsvcPswVersionMisma "EPASTP_a033_icsvcPswVersionMismatch";
BA_ "SystemSignalLongSymbol" SG_ 919 EPASTP_a038_csohCh1CsErrorErrAtR "EPASTP_a038_csohCh1CsErrorErrAtReset";
BA_ "SystemSignalLongSymbol" SG_ 919 EPASTP_a039_csohCh2CsErrorErrAtR "EPASTP_a039_csohCh2CsErrorErrAtReset";
BA_ "SystemSignalLongSymbol" SG_ 919 EPASTP_a040_swrhLimitedResetRetr "EPASTP_a040_swrhLimitedResetRetriesExpired";
BA_ "SystemSignalLongSymbol" SG_ 919 EPASTP_a041_imcmCoreConfiguratio "EPASTP_a041_imcmCoreConfigurationMismatch";
BA_ "SystemSignalLongSymbol" SG_ 919 EPASTP_a045_psumSbcBandgapVoltEr "EPASTP_a045_psumSbcBandgapVoltErr";
BA_ "SystemSignalLongSymbol" SG_ 919 EPASTP_a046_mcusscOscillatorNotR "EPASTP_a046_mcusscOscillatorNotReliable";
BA_ "SystemSignalLongSymbol" SG_ 919 EPASTP_a052_ermSdcInputBufferOve "EPASTP_a052_ermSdcInputBufferOverflow";
BA_ "SystemSignalLongSymbol" SG_ 919 EPASTP_a053_adcUnexpectedNumOfDa "EPASTP_a053_adcUnexpectedNumOfData";
BA_ "SystemSignalLongSymbol" SG_ 919 EPASTP_a056_amGduConfigCsErrorCh "EPASTP_a056_amGduConfigCsErrorCheck";
BA_ "SystemSignalLongSymbol" SG_ 919 EPASTP_a067_tspmPowermoduleTempI "EPASTP_a067_tspmPowermoduleTempImplausible";
BA_ "SystemSignalLongSymbol" SG_ 919 EPASTP_a068_rsthCoreRedundancyEr "EPASTP_a068_rsthCoreRedundancyErr";
BA_ "SystemSignalLongSymbol" SG_ 919 EPASTP_a069_rsthCoreTempOutOfRan "EPASTP_a069_rsthCoreTempOutOfRangeHwCheck";
BA_ "SystemSignalLongSymbol" SG_ 919 EPASTP_a072_rsthFlashUncorrEccOr "EPASTP_a072_rsthFlashUncorrEccOrOvfl";
BA_ "SystemSignalLongSymbol" SG_ 919 EPASTP_a075_rsthUnusedOtherModul "EPASTP_a075_rsthUnusedOtherModuleAlarm";
BA_ "SystemSignalLongSymbol" SG_ 919 EPASTP_a081_exchFloatingPointExc "EPASTP_a081_exchFloatingPointException";
BA_ "SystemSignalLongSymbol" SG_ 919 EPASTP_a083_tdaDclinkcapacitorTe "EPASTP_a083_tdaDclinkcapacitorTempChecker";
BA_ "SystemSignalLongSymbol" SG_ 919 EPASTP_a085_amGduSwitchOffTestBy "EPASTP_a085_amGduSwitchOffTestByMcu";
BA_ "SystemSignalLongSymbol" SG_ 919 EPASTP_a088_tedMainboardTempChec "EPASTP_a088_tedMainboardTempChecker";
BA_ "SystemSignalLongSymbol" SG_ 919 EPASTP_a089_tedRevercebattfetjun "EPASTP_a089_tedRevercebattfetjunctionTempChecker";
BA_ "SystemSignalLongSymbol" SG_ 919 EPASTP_a091_bvpBattVoltCrossChkF "EPASTP_a091_bvpBattVoltCrossChkFailed";
BA_ "SystemSignalLongSymbol" SG_ 919 EPASTP_a092_amGduSwitchOffTestBy "EPASTP_a092_amGduSwitchOffTestBySbc";
BA_ "SystemSignalLongSymbol" SG_ 919 EPASTP_a093_sctpTsuSingleStaticF "EPASTP_a093_sctpTsuSingleStaticFail";
BA_ "SystemSignalLongSymbol" SG_ 919 EPASTP_a094_sctpTsuMultipleStati "EPASTP_a094_sctpTsuMultipleStaticFail";
BA_ "SystemSignalLongSymbol" SG_ 919 EPASTP_a095_mdModelBasedMotorInt "EPASTP_a095_mdModelBasedMotorIntegrityCheck";
BA_ "SystemSignalLongSymbol" SG_ 919 EPASTP_a096_rppRpsSingleStaticFa "EPASTP_a096_rppRpsSingleStaticFail";
BA_ "SystemSignalLongSymbol" SG_ 919 EPASTP_a097_rppRpsMultipleStatic "EPASTP_a097_rppRpsMultipleStaticFail";
BA_ "SystemSignalLongSymbol" SG_ 919 EPASTP_a099_mcdTorqueMismatchFau "EPASTP_a099_mcdTorqueMismatchFault";
BA_ "SystemSignalLongSymbol" SG_ 919 EPASTP_a103_exhaUnusedInterruptC "EPASTP_a103_exhaUnusedInterruptCallException";
BA_ "SystemSignalLongSymbol" SG_ 919 EPASTP_a105_exhaSriBusErrExcepti "EPASTP_a105_exhaSriBusErrException";
BA_ "SystemSignalLongSymbol" SG_ 919 EPASTP_a106_exhaSpbBusErrExcepti "EPASTP_a106_exhaSpbBusErrException";
BA_ "SystemSignalLongSymbol" SG_ 919 EPASTP_a107_exhaOtherNmiExceptio "EPASTP_a107_exhaOtherNmiException";
BA_ "SystemSignalLongSymbol" SG_ 919 EPASTP_a108_exhaInternalProtecti "EPASTP_a108_exhaInternalProtectionException";
BA_ "SystemSignalLongSymbol" SG_ 919 EPASTP_a109_exhaSysBusOrPeriphEr "EPASTP_a109_exhaSysBusOrPeriphErrException";
BA_ "SystemSignalLongSymbol" SG_ 919 EPASTP_a110_amPhaseRelaySwitchOf "EPASTP_a110_amPhaseRelaySwitchOffTest";
BA_ "SystemSignalLongSymbol" SG_ 919 EPASTP_a111_amCurrentSensingDisc "EPASTP_a111_amCurrentSensingDisconnection";
BA_ "SystemSignalLongSymbol" SG_ 919 EPASTP_a112_rsthSafetyFlipflopEr "EPASTP_a112_rsthSafetyFlipflopErr";
BA_ "SystemSignalLongSymbol" SG_ 919 EPASTP_a113_rsthUncorrectableEnd "EPASTP_a113_rsthUncorrectableEndToEndBusErr";
BA_ "SystemSignalLongSymbol" SG_ 919 EPASTP_a115_mcusscLbistSingleFai "EPASTP_a115_mcusscLbistSingleFail";
BA_ "SystemSignalLongSymbol" SG_ 919 EPASTP_a116_mrccStartupRegCsErro "EPASTP_a116_mrccStartupRegCsErrorStaticErr";
BA_ "SystemSignalLongSymbol" SG_ 919 EPASTP_a117_mrccStartupRegCsErro "EPASTP_a117_mrccStartupRegCsErrorTransientErr";
BA_ "SystemSignalLongSymbol" SG_ 919 EPASTP_a118_mcusscFlashCsErrorEr "EPASTP_a118_mcusscFlashCsErrorErr";
BA_ "SystemSignalLongSymbol" SG_ 919 EPASTP_a119_mcusscFlashEccCritic "EPASTP_a119_mcusscFlashEccCriticalErr";
BA_ "SystemSignalLongSymbol" SG_ 919 EPASTP_a120_mcusscFlashEccLatent "EPASTP_a120_mcusscFlashEccLatentErr";
BA_ "SystemSignalLongSymbol" SG_ 919 EPASTP_a124_mcusscMbistEccTransi "EPASTP_a124_mcusscMbistEccTransientErr";
BA_ "SystemSignalLongSymbol" SG_ 919 EPASTP_a127_exchAdditionalExcept "EPASTP_a127_exchAdditionalExceptionAfterRst";
BA_ "SystemSignalLongSymbol" SG_ 919 EPASTP_a128_exchExceptionStopRes "EPASTP_a128_exchExceptionStopRestart";
BA_ "SystemSignalLongSymbol" SG_ 919 EPASTP_a129_exchAdditionalExcept "EPASTP_a129_exchAdditionalExceptionStopRestart";
BA_ "SystemSignalLongSymbol" SG_ 919 EPASTP_a131_exchGuardedResetAfte "EPASTP_a131_exchGuardedResetAfterPartitionStop";
BA_ "SystemSignalLongSymbol" SG_ 919 EPASTP_a132_mcusscNotSupportedMc "EPASTP_a132_mcusscNotSupportedMcu";
BA_ "SystemSignalLongSymbol" SG_ 919 EPASTP_a133_mcusscLbistEcuIdIsNo "EPASTP_a133_mcusscLbistEcuIdIsNotSupported";
BA_ "SystemSignalLongSymbol" SG_ 919 EPASTP_a134_osehGuardedResetAfte "EPASTP_a134_osehGuardedResetAfterErrWithoutReset";
BA_ "SystemSignalLongSymbol" SG_ 919 EPASTP_a135_tmpsfetjCalculationO "EPASTP_a135_tmpsfetjCalculationOverflowErr";
BA_ "SystemSignalLongSymbol" SG_ 919 EPASTP_a137_osehErrWithoutImmedi "EPASTP_a137_osehErrWithoutImmediateReset";
BA_ "SystemSignalLongSymbol" SG_ 919 EPASTP_a138_osehAdditionalErrWit "EPASTP_a138_osehAdditionalErrWithoutImmReset";
BA_ "SystemSignalLongSymbol" SG_ 919 EPASTP_a142_tedEmifilterDmcTempC "EPASTP_a142_tedEmifilterDmcTempChecker";
BA_ "SystemSignalLongSymbol" SG_ 919 EPASTP_a143_tedEmifilterCmcTempC "EPASTP_a143_tedEmifilterCmcTempChecker";
BA_ "SystemSignalLongSymbol" SG_ 919 EPASTP_a145_mriPeripheralRaminit "EPASTP_a145_mriPeripheralRaminitFailed";
BA_ "SystemSignalLongSymbol" SG_ 919 EPASTP_a148_mrccExitFromStandbyD "EPASTP_a148_mrccExitFromStandbyDetected";
BA_ "SystemSignalLongSymbol" SG_ 919 EPASTP_a149_amReversibleEmergenc "EPASTP_a149_amReversibleEmergencyOffRequested";
BA_ "SystemSignalLongSymbol" SG_ 919 EPASTP_a150_amExternalEmergencyO "EPASTP_a150_amExternalEmergencyOffRequested";
BA_ "SystemSignalLongSymbol" SG_ 919 EPASTP_a151_amPermanentEmergency "EPASTP_a151_amPermanentEmergencyOffRequested";
BA_ "SystemSignalLongSymbol" SG_ 919 EPASTP_a152_exchFlashEccExceptio "EPASTP_a152_exchFlashEccException";
BA_ "SystemSignalLongSymbol" SG_ 919 EPASTP_a153_sdsmBlockSelectorInv "EPASTP_a153_sdsmBlockSelectorInvalid";
BA_ "SystemSignalLongSymbol" SG_ 919 EPASTP_a154_sdsmCsErrorInvalidPr "EPASTP_a154_sdsmCsErrorInvalidPrimary";
BA_ "SystemSignalLongSymbol" SG_ 919 EPASTP_a156_amIntSerialErrSafety "EPASTP_a156_amIntSerialErrSafetyReset";
BA_ "SystemSignalLongSymbol" SG_ 919 EPASTP_a158_amGduFailDuringRecov "EPASTP_a158_amGduFailDuringRecovery";
BA_ "SystemSignalLongSymbol" SG_ 919 EPASTP_a159_exchFlashWordlineTra "EPASTP_a159_exchFlashWordlineTransientErr";
BA_ "SystemSignalLongSymbol" SG_ 919 EPASTP_a160_rsthCpu1UnexpectedAl "EPASTP_a160_rsthCpu1UnexpectedAlarm";
BA_ "SystemSignalLongSymbol" SG_ 919 EPASTP_a161_tdaRelayfetjunctionT "EPASTP_a161_tdaRelayfetjunctionTempChecker";
BA_ "SystemSignalLongSymbol" SG_ 919 EPASTP_a162_tdaBridgefetjunction "EPASTP_a162_tdaBridgefetjunctionTempChecker";
BA_ "SystemSignalLongSymbol" SG_ 919 EPASTP_a163_tdaPowermoduleTempCh "EPASTP_a163_tdaPowermoduleTempChecker";
BA_ "SystemSignalLongSymbol" SG_ 919 EPASTP_a164_tdaBattfetjunctionTe "EPASTP_a164_tdaBattfetjunctionTempChecker";
BA_ "SystemSignalLongSymbol" SG_ 919 EPASTP_a165_tdaDcbusshuntTempChe "EPASTP_a165_tdaDcbusshuntTempChecker";
BA_ "SystemSignalLongSymbol" SG_ 919 EPASTP_a166_tdaPhasecurrentshunt "EPASTP_a166_tdaPhasecurrentshuntTempChecker";
BA_ "SystemSignalLongSymbol" SG_ 919 EPASTP_a167_iccd1ErrQueueOverflo "EPASTP_a167_iccd1ErrQueueOverflow";
BA_ "SystemSignalLongSymbol" SG_ 919 EPASTP_a172_pmpElangMotorcurrent "EPASTP_a172_pmpElangMotorcurrentAge";
BA_ "SystemSignalLongSymbol" SG_ 919 EPASTP_a175_exchFlashStoredConfi "EPASTP_a175_exchFlashStoredConfigErr";
BA_ "SystemSignalLongSymbol" SG_ 919 EPASTP_a176_exchCpu1ExceptionRes "EPASTP_a176_exchCpu1ExceptionReset";
BA_ "SystemSignalLongSymbol" SG_ 919 EPASTP_a179_tedMotorcoilTempChec "EPASTP_a179_tedMotorcoilTempChecker";
BA_ "SystemSignalLongSymbol" SG_ 919 EPASTP_a180_dmDeadlineViolationC "EPASTP_a180_dmDeadlineViolationC1";
BA_ "SystemSignalLongSymbol" SG_ 919 EPASTP_a181_dmDeadlineViolationC "EPASTP_a181_dmDeadlineViolationC1";
BA_ "SystemSignalLongSymbol" SG_ 919 EPASTP_a184_sbcmCommBufferOverfl "EPASTP_a184_sbcmCommBufferOverflow";
BA_ "SystemSignalLongSymbol" SG_ 919 EPASTP_a185_sbcscpQAWatchdogRese "EPASTP_a185_sbcscpQAWatchdogReset";
BA_ "SystemSignalLongSymbol" SG_ 919 EPASTP_a186_wdhCommBufferOverflo "EPASTP_a186_wdhCommBufferOverflow";
BA_ "SystemSignalLongSymbol" SG_ 919 EPASTP_a188_epmCommBufferOverflo "EPASTP_a188_epmCommBufferOverflow";
BA_ "SystemSignalLongSymbol" SG_ 919 EPASTP_a190_sbchCommBufferOverfl "EPASTP_a190_sbchCommBufferOverflow";
BA_ "SystemSignalLongSymbol" SG_ 919 EPASTP_a191_sbcscpVcp2VucVoltFai "EPASTP_a191_sbcscpVcp2VucVoltFail";
BA_ "SystemSignalLongSymbol" SG_ 919 EPASTP_a196_topEolTasOffsetInval "EPASTP_a196_topEolTasOffsetInvalid";
BA_ "SystemSignalLongSymbol" SG_ 919 EPASTP_a200_ammInputBufferOverfl "EPASTP_a200_ammInputBufferOverflow";
BA_ "SystemSignalLongSymbol" SG_ 919 EPASTP_a201_ammOutputBufferOverf "EPASTP_a201_ammOutputBufferOverflow";
BA_ "SystemSignalLongSymbol" SG_ 919 EPASTP_a202_ohnvmpStoredOffsetLo "EPASTP_a202_ohnvmpStoredOffsetLost";
BA_ "SystemSignalLongSymbol" SG_ 919 EPASTP_a206_fdrOclPartialBlockin "EPASTP_a206_fdrOclPartialBlocking";
BA_ "SystemSignalLongSymbol" SG_ 919 EPASTP_a208_fdrLowSeverityBlocki "EPASTP_a208_fdrLowSeverityBlocking";
BA_ "SystemSignalLongSymbol" SG_ 919 EPASTP_a209_fdrLowSeverityFreezi "EPASTP_a209_fdrLowSeverityFreezing";
BA_ "SystemSignalLongSymbol" SG_ 919 EPASTP_a213_frmHighFrictionDetec "EPASTP_a213_frmHighFrictionDetected";
BA_ "SystemSignalLongSymbol" SG_ 919 EPASTP_a218_aadApplicationStateE "EPASTP_a218_aadApplicationStateErr";
BA_ "SystemSignalLongSymbol" SG_ 919 EPASTP_a258_pspInvalidProjectPar "EPASTP_a258_pspInvalidProjectParamset";
BA_ "SystemSignalLongSymbol" SG_ 919 EPASTP_a270_oscillationCompTrqLi "EPASTP_a270_oscillationCompTrqLimReached";
BA_ "Confidence" SG_ 1428 EPASTS_alertID 1;
BA_ "Confidence" SG_ 1428 EPASTS_alertState 1;
BA_ "Confidence" SG_ 1428 EPASTS_a264_degradedECU 1;
BA_ "Confidence" SG_ 1428 EPASTS_a264_vehicleSpeed 1;
BA_ "Confidence" SG_ 1428 EPASTS_a264_powerRatio 1;
BA_ "Confidence" SG_ 1428 EPASTS_a264_ownSideDegradationRe 1;
BA_ "SystemSignalLongSymbol" SG_ 1428 EPASTS_a264_ownSideDegradationRe "EPASTS_a264_ownSideDegradationReason";
BA_ "Confidence" SG_ 1428 EPASTS_a264_otherSideDegradation 1;
BA_ "SystemSignalLongSymbol" SG_ 1428 EPASTS_a264_otherSideDegradation "EPASTS_a264_otherSideDegradationReason";
BA_ "Confidence" SG_ 1428 EPASTS_a265_degradedECU 1;
BA_ "Confidence" SG_ 1428 EPASTS_a265_vehicleSpeed 1;
BA_ "Confidence" SG_ 1428 EPASTS_a265_rawMcuTemperature 1;
BA_ "Confidence" SG_ 1428 EPASTS_a265_degradedCurrentLimit 1;
BA_ "Confidence" SG_ 1428 EPASTS_a266_cdpAssistFactor 1;
BA_ "Confidence" SG_ 1428 EPASTS_a266_vehicleSpeed 1;
BA_ "Confidence" SG_ 1428 EPASTS_a267_vehicleSpeed 1;
BA_ "Confidence" SG_ 1428 EPASTS_a267_velocityEstimatorSta 1;
BA_ "SystemSignalLongSymbol" SG_ 1428 EPASTS_a267_velocityEstimatorSta "EPASTS_a267_velocityEstimatorState";
BA_ "Confidence" SG_ 1428 EPASTS_a269_vehicleSpeed 1;
VAL_ 785 EPAS3S_infoIndex 255 "END" 31 "SUBCOMPONENT_GITHASH" 30 "PACKAGE_SN_8_14" 29 "PACKAGE_SN_1_7" 27 "PACKAGE_PN_15_20" 26 "PACKAGE_PN_8_14" 25 "PACKAGE_PN_1_7" 23 "SUBCOMPONENT2" 22 "VARIANTCRC" 20 "UDS_PROTOCOL_BOOTCRC" 19 "VERSION_DEPRECATED" 18 "BOOTLOADER_GITHASH" 17 "APP_GITHASH" 16 "SUBCOMPONENT" 15 "BOOTLOADER_CRC" 14 "BOOTLOADER_SVN" 13 "APP_CRC" 11 "PCBAID_ASSYID_USAGEID" 10 "BUILD_HWID_COMPONENTID" 9 "DEPRECATED_9" 8 "DEPRECATED_8" 7 "DEPRECATED_7" 6 "DEPRECATED_6" 5 "DEPRECATED_5" 4 "DEPRECATED_4" 3 "DEPRECATED_3" 2 "DEPRECATED_2" 1 "DEPRECATED_1" 0 "DEPRECATED_0" ;
VAL_ 785 EPAS3S_infoBuildType 4 "INFO_MFG_BUILD" 3 "INFO_TRACEABLE_CI_BUILD" 2 "INFO_LOCAL_BUILD" 1 "INFO_PLATFORM_BUILD" 0 "INFO_UNKNOWN_BUILD" ;
VAL_ 882 EPAS3S_steeringRackForce 1023 "SNA" 1022 "NOT_IN_SPEC" ;
VAL_ 882 EPAS3S_steeringFault 1 "FAULT" 0 "NO_FAULT" ;
VAL_ 882 EPAS3S_steeringReduced 1 "REDUCED_ASSIST" 0 "NORMAL_ASSIST" ;
VAL_ 882 EPAS3S_internalSASQF 1 "IN_SPEC" 0 "UNDEFINABLE_ACCURACY" ;
VAL_ 882 EPAS3S_currentTuneMode 5 "STEERING_TUNE_RWD_SPORT" 4 "STEERING_TUNE_RWD_STANDARD" 3 "STEERING_TUNE_RWD_COMFORT" 2 "STEERING_TUNE_DM_SPORT" 1 "STEERING_TUNE_DM_STANDARD" 0 "STEERING_TUNE_DM_COMFORT" ;
VAL_ 882 EPAS3S_torsionBarTorque 4095 "SNA" 4094 "UNDEFINABLE_DATA" ;
VAL_ 882 EPAS3S_eacErrorCode 15 "SNA" 14 "EAC_EXTERNAL_MONITOR_INHIBIT" 13 "EAC_ERROR_PINION_VEL_DIFF" 12 "EAC_ERROR_LOW_ASSIST" 11 "EAC_ERROR_HIGH_TORSION_SAFETY" 10 "EAC_ERROR_HIGH_MMOT_SAFETY" 9 "EAC_ERROR_HIGH_ANGLE_RATE_SAFETY" 8 "EAC_ERROR_HIGH_ANGLE_SAFETY" 7 "EAC_ERROR_HIGH_ANGLE_RATE_REQ" 6 "EAC_ERROR_HIGH_ANGLE_REQ" 5 "EAR_ERROR_MAX_STEER_DELTA" 4 "EAC_ERROR_TMP_FAULT" 3 "EAC_ERROR_HANDS_ON" 2 "EAC_ERROR_MAX_SPEED" 1 "EAC_ERROR_MIN_SPEED" 0 "EAC_ERROR_IDLE" ;
VAL_ 882 EPAS3S_handsOnLevel 3 "LEVEL_3" 2 "LEVEL_2" 1 "LEVEL_1" 0 "LEVEL_0" ;
VAL_ 882 EPAS3S_driverlessState 1 "EAC_DRIVERLESS_ACTIVE" 0 "EAC_DRIVERLESS_INACTIVE" ;
VAL_ 882 EPAS3S_eacStatus 7 "EAC_ELK_ACTIVE" 6 "EAC_ELK_AVAILABLE" 5 "EAC_LKA_ACTIVE" 4 "EAC_LKA_ELK_AVAILABLE" 3 "EAC_FAULT" 2 "EAC_ACTIVE" 1 "EAC_AVAILABLE" 0 "EAC_INHIBITED" ;
VAL_ 1427 EPASTP_alertID 270 "a270_oscillationCompTrqLimReached" 269 "a269_assistTorqueDisabled" 268 "a268_eacCancelled" 267 "a267_safeSpeedAssist" 266 "a266_overloadProtect" 265 "a265_overheatProtect" 264 "a264_assistTorqueLimited" 263 "a263_espWsStatus" 262 "a262_yawRateStatus" 261 "a261_sccmStatusError" 260 "a260_scoPrivateBusOff" 259 "a259_scoCanBusOff" 258 "a258_pspInvalidProjectParamset" 257 "a257_dcvmUnderVolt" 256 "a256_dcvmOverVolt" 255 "a255_pmState2Mia" 254 "a254_vcFrontMia" 253 "a253_vcFrontCsError" 252 "a252_vcFrontCntError" 251 "a251_uiTuneReqMia" 250 "a250_uiTuneReqCsError" 249 "a249_uiTuneReqCntError" 248 "a248_sccmMia" 247 "a247_sccmCsError" 246 "a246_sccmCntError" 245 "a245_rcmMia" 244 "a244_rcmCsError" 243 "a243_rcmCntError" 242 "a242_gtwConfigMia" 241 "a241_espWsMia" 240 "a240_espWsCsError" 239 "a239_espWsCntError" 238 "a238_espWrMia" 237 "a237_espWrCsError" 236 "a236_espWrCntError" 235 "a235_ecu2StatMia" 234 "a234_ecu2StatCsError" 233 "a233_ecu2StatCntError" 232 "a232_diSpdMia" 231 "a231_diSpdCsError" 230 "a230_diSpdCntError" 229 "a229_dirTorqueMia" 228 "a228_dirTorqueCsError" 227 "a227_dirTorqueCntError" 226 "a226_dasMia" 225 "a225_dasCsError" 224 "a224_dasCntError" 223 "a223_apsMia" 222 "a222_apsCsError" 221 "a221_apsCntError" 219 "a219_frhFastRestartFailed" 218 "a218_aadApplicationStateErr" 217 "a217_msdMasterSilentErr" 216 "a216_isdgImproperShutdown" 215 "a215_vsgSafeViolErr" 214 "a214_velInterfaceErr" 213 "a213_frmHighFrictionDetected" 212 "a212_frmDataLost" 211 "a211_frmInternalErr" 210 "a210_fdrTotalBlocking" 209 "a209_fdrLowSeverityFreezing" 208 "a208_fdrLowSeverityBlocking" 207 "a207_fdrOclFreezing" 206 "a206_fdrOclPartialBlocking" 205 "a205_fdrOclFail" 204 "a204_fdpPrevTrqErr" 203 "a203_ctcInterfaceErr" 202 "a202_ohnvmpStoredOffsetLost" 201 "a201_ammOutputBufferOverflow" 200 "a200_ammInputBufferOverflow" 199 "a199_osumC1StackNearFull" 198 "a198_osumC1CsaNearFull" 197 "a197_difpDifactorInvalid" 196 "a196_topEolTasOffsetInvalid" 195 "a195_imcmCommErrC1" 194 "a194_amNvdataLoss" 193 "a193_osumC0StackNearFull" 192 "a192_osumC0CsaNearFull" 191 "a191_sbcscpVcp2VucVoltFail" 190 "a190_sbchCommBufferOverflow" 189 "a189_sbchCommErrMcuToSbc" 188 "a188_epmCommBufferOverflow" 187 "a187_epmVoltFail" 186 "a186_wdhCommBufferOverflow" 185 "a185_sbcscpQAWatchdogReset" 184 "a184_sbcmCommBufferOverflow" 183 "a183_sbchCommErrSbcToMcu" 182 "a182_mcdInputMia" 181 "a181_dmDeadlineViolationC1" 180 "a180_dmDeadlineViolationC1" 179 "a179_tedMotorcoilTempChecker" 178 "a178_exchWdtException" 177 "a177_etsrInvalidated" 176 "a176_exchCpu1ExceptionReset" 175 "a175_exchFlashStoredConfigErr" 174 "a174_pmpPhasecurrentAge" 173 "a173_pmpRotorspeedAge" 172 "a172_pmpElangMotorcurrentAge" 171 "a171_pmpKgvalueAge" 170 "a170_pmpDcvoltAge" 169 "a169_scpSafetyReset" 168 "a168_c1csInvalidC1App" 167 "a167_iccd1ErrQueueOverflow" 166 "a166_tdaPhasecurrentshuntTempChecker" 165 "a165_tdaDcbusshuntTempChecker" 164 "a164_tdaBattfetjunctionTempChecker" 163 "a163_tdaPowermoduleTempChecker" 162 "a162_tdaBridgefetjunctionTempChecker" 161 "a161_tdaRelayfetjunctionTempChecker" 160 "a160_rsthCpu1UnexpectedAlarm" 159 "a159_exchFlashWordlineTransientErr" 158 "a158_amGduFailDuringRecovery" 157 "a157_mcudcpInvalidEcuId" 156 "a156_amIntSerialErrSafetyReset" 155 "a155_sdsmDataInvalidAll" 154 "a154_sdsmCsErrorInvalidPrimary" 153 "a153_sdsmBlockSelectorInvalid" 152 "a152_exchFlashEccException" 151 "a151_amPermanentEmergencyOffRequested" 150 "a150_amExternalEmergencyOffRequested" 149 "a149_amReversibleEmergencyOffRequested" 148 "a148_mrccExitFromStandbyDetected" 147 "a147_amDcLinkShortedFail" 146 "a146_btarcRcCircuitCheck" 145 "a145_mriPeripheralRaminitFailed" 144 "a144_mriCoreRaminitFailed" 143 "a143_tedEmifilterCmcTempChecker" 142 "a142_tedEmifilterDmcTempChecker" 141 "a141_amFetShortTest" 140 "a140_imcmConfigurationErr" 139 "a139_osehAdditionalOsErr" 138 "a138_osehAdditionalErrWithoutImmReset" 137 "a137_osehErrWithoutImmediateReset" 136 "a136_ftElectricalAngleQf" 135 "a135_tmpsfetjCalculationOverflowErr" 134 "a134_osehGuardedResetAfterErrWithoutReset" 133 "a133_mcusscLbistEcuIdIsNotSupported" 132 "a132_mcusscNotSupportedMcu" 131 "a131_exchGuardedResetAfterPartitionStop" 130 "a130_mrccConfigCsErrorErr" 129 "a129_exchAdditionalExceptionStopRestart" 128 "a128_exchExceptionStopRestart" 127 "a127_exchAdditionalExceptionAfterRst" 126 "a126_mcusscMonbistMiaErr" 125 "a125_mcusscMbistMiaErr" 124 "a124_mcusscMbistEccTransientErr" 123 "a123_imcmCommErr" 122 "a122_pcpBridgeFetShort" 121 "a121_mcusscMbistEccErr" 120 "a120_mcusscFlashEccLatentErr" 119 "a119_mcusscFlashEccCriticalErr" 118 "a118_mcusscFlashCsErrorErr" 117 "a117_mrccStartupRegCsErrorTransientErr" 116 "a116_mrccStartupRegCsErrorStaticErr" 115 "a115_mcusscLbistSingleFail" 114 "a114_osehOsErr" 113 "a113_rsthUncorrectableEndToEndBusErr" 112 "a112_rsthSafetyFlipflopErr" 111 "a111_amCurrentSensingDisconnection" 110 "a110_amPhaseRelaySwitchOffTest" 109 "a109_exhaSysBusOrPeriphErrException" 108 "a108_exhaInternalProtectionException" 107 "a107_exhaOtherNmiException" 106 "a106_exhaSpbBusErrException" 105 "a105_exhaSriBusErrException" 104 "a104_exhaBusMpuException" 103 "a103_exhaUnusedInterruptCallException" 102 "a102_amPhasecurrentQosErr" 101 "a101_sdrvSpcIdMismatch" 100 "a100_amVbrgLssFault" 99 "a099_mcdTorqueMismatchFault" 98 "a098_invErr" 97 "a097_rppRpsMultipleStaticFail" 96 "a096_rppRpsSingleStaticFail" 95 "a095_mdModelBasedMotorIntegrityCheck" 94 "a094_sctpTsuMultipleStaticFail" 93 "a093_sctpTsuSingleStaticFail" 92 "a092_amGduSwitchOffTestBySbc" 91 "a091_bvpBattVoltCrossChkFailed" 90 "a090_etsmWarning" 89 "a089_tedRevercebattfetjunctionTempChecker" 88 "a088_tedMainboardTempChecker" 87 "a087_rsthFlashConfigErr" 86 "a086_rsthRamUncorrEcc" 85 "a085_amGduSwitchOffTestByMcu" 84 "a084_adcTriggerCheck" 83 "a083_tdaDclinkcapacitorTempChecker" 82 "a082_adcTriggerTimeChk" 81 "a081_exchFloatingPointException" 80 "a080_pwmTimerSyncCheck" 79 "a079_gduhComErr" 78 "a078_dmDeadlineViolation" 77 "a077_dmDeadlineViolation" 76 "a076_exchGeneralException" 75 "a075_rsthUnusedOtherModuleAlarm" 74 "a074_rsthUnexpectedAlarm" 73 "a073_rsthOtherEdcEcc" 72 "a072_rsthFlashUncorrEccOrOvfl" 71 "a071_rsthInternalHighVolt" 70 "a070_rsthInternalLowVolt" 69 "a069_rsthCoreTempOutOfRangeHwCheck" 68 "a068_rsthCoreRedundancyErr" 67 "a067_tspmPowermoduleTempImplausible" 66 "a066_amVoltQfErr" 65 "a065_amGduJuncTemp" 64 "a064_amBridgeShort" 63 "a063_amIntRegulatorErr" 62 "a062_amPhaseBridgeCheck" 61 "a061_amIntSerialErr" 60 "a060_amGduFail" 59 "a059_amStartupTestFailed" 58 "a058_amIntVgsUndervtgErr" 57 "a057_amGduVds" 56 "a056_amGduConfigCsErrorCheck" 55 "a055_amExtendedGduTest" 54 "a054_adcUnexpectedData" 53 "a053_adcUnexpectedNumOfData" 52 "a052_ermSdcInputBufferOverflow" 51 "a051_ermMessageErr" 50 "a050_erlErr" 49 "a049_epmLgFail" 48 "a048_epmVcpVoltFail" 47 "a047_epmVregVoltFail" 46 "a046_mcusscOscillatorNotReliable" 45 "a045_psumSbcBandgapVoltErr" 44 "a044_sbcmSbcEepromFail" 43 "a043_sbcmWdStateDisabled" 42 "a042_wdhWdTestFail" 41 "a041_imcmCoreConfigurationMismatch" 40 "a040_swrhLimitedResetRetriesExpired" 39 "a039_csohCh2CsErrorErrAtReset" 38 "a038_csohCh1CsErrorErrAtReset" 37 "a037_epmV5P2Fail" 36 "a036_sbcmSbcBistFailed" 35 "a035_sbchChipIdFail" 34 "a034_sbchReadbackRegFail" 33 "a033_icsvcPswVersionMismatch" 32 "a032_eolpEolCheckFailed" 31 "a031_pmsProductionModeFailed" 30 "a030_rsthClockReset" 29 "a029_smuhSmuCoreCntErrorTestFail" 28 "a028_smuhNonInitDataCorruption" 27 "a027_mcusscDmuHfErr" 26 "a026_mrccCsErrorCheckFail" 25 "a025_btarcCorruptionCheck" 24 "a024_srhCsErrorCheckFail" 23 "a023_btarcCorruptionCheck" 22 "a022_swrhSwResetInfoCorruptionCheck" 21 "a021_osehCsErrorCheck" 20 "a020_mcusscEolEcuIdIntegritiyFail" 19 "a019_rsthHwResetInfoCorruptionCheck" 18 "a018_exchCsErrorCheck" 17 "a017_stmdStmPlausibilityCheckErr" 16 "a016_mcufcCsErrorCheckFail" 15 "a015_mcusscCsErrorCheckFail" 14 "a014_mcusscSffMonitoringMia" 13 "a013_mcusscSffMonitoringFailed" 12 "a012_mcusscMbistEccErr" 11 "a011_mcusscMonbistErr" 10 "a010_svcIncompatibleSwVersions" 9 "a009_mcusscLbistPermanentFail" 8 "a008_psdcPlatformShutdown" 7 "a007_tsmcCoreTempDiff" 6 "a006_swrhResetByInvalidErrid" 5 "a005_scpUnknownResetSource" 4 "a004_scpInputMia" 3 "a003_pspInvalidParamset" 2 "a002_adcMuxErr" 1 "a001_adcCalibrationOrInitFail" 0 "ALERT_DO_NOT_USE_ZERO" ;
VAL_ 1427 EPASTP_alertState 1 "SET" 0 "CLEARED" ;
VAL_ 1427 EPASTP_a264_degradedECU 3 "BOTH_ECU_SIDES" 2 "OTHER_ECU_SIDE" 1 "OWN_ECU_SIDE" 0 "NONE" ;
VAL_ 1427 EPASTP_a264_ownSideDegradationRe 92 "DC_LINK_CAPACITOR_HOTSPOTCASEDIFF_TEMPERATURE" 84 "PHASECURRENT_SHUNT_TEMPERATURE_MOMENTARY" 80 "DC_LINK_CAPACITOR_TEMPERATURE" 52 "EMIFILTER_DMC_TEMPERATURE" 48 "EMIFILTER_CMC_TEMPERATURE" 44 "DCLINK_SHUNT_TEMPERATURE" 40 "PHASECURRENT_SHUNT_TEMPERATURE" 36 "POWER_MODULE_TEMPERATURE" 32 "MOTOR_COIL_TEMPERATURE" 28 "BATTERY_FET_JUNCTION_TEMPERATURE" 24 "MAIN_BOARD_TEMPERATURE" 20 "REVERSE_BATTERY_FET_JUNCTION_TEMPERATURE" 12 "RELAY_FET_JUNCTION_TEMPERATURE" 8 "BRIDGE_FET_JUNCTION_TEMPERATURE" 4 "CORE1_DEGRADATION" 0 "NO_DEGRADATION_ON_THIS_ECU_SIDE" ;
VAL_ 1427 EPASTP_a264_otherSideDegradation 92 "DC_LINK_CAPACITOR_HOTSPOTCASEDIFF_TEMPERATURE" 84 "PHASECURRENT_SHUNT_TEMPERATURE_MOMENTARY" 80 "DC_LINK_CAPACITOR_TEMPERATURE" 52 "EMIFILTER_DMC_TEMPERATURE" 48 "EMIFILTER_CMC_TEMPERATURE" 44 "DCLINK_SHUNT_TEMPERATURE" 40 "PHASECURRENT_SHUNT_TEMPERATURE" 36 "POWER_MODULE_TEMPERATURE" 32 "MOTOR_COIL_TEMPERATURE" 28 "BATTERY_FET_JUNCTION_TEMPERATURE" 24 "MAIN_BOARD_TEMPERATURE" 20 "REVERSE_BATTERY_FET_JUNCTION_TEMPERATURE" 12 "RELAY_FET_JUNCTION_TEMPERATURE" 8 "BRIDGE_FET_JUNCTION_TEMPERATURE" 4 "CORE1_DEGRADATION" 0 "NO_DEGRADATION_ON_THIS_ECU_SIDE" ;
VAL_ 1427 EPASTP_a265_degradedECU 3 "BOTH_ECU_SIDES" 2 "OTHER_ECU_SIDE" 1 "OWN_ECU_SIDE" 0 "NONE" ;
VAL_ 1427 EPASTP_a267_velocityEstimatorSta 5 "BACKUP_MOTOR" 4 "BACKUP_WHEELS_B" 3 "BACKUP_WHEELS_A" 2 "WHEELS_REDUCED" 1 "WHEELS_NORMAL" 0 "NOT_INITIALIZED" ;
VAL_ 919 EPASTP_matrixIndex 4 "AlertMatrix4" 3 "AlertMatrix3" 2 "AlertMatrix2" 1 "AlertMatrix1" 0 "AlertMatrix0" ;
VAL_ 1428 EPASTS_alertID 270 "a270_oscillationCompTrqLimReached" 269 "a269_assistTorqueDisabled" 268 "a268_eacCancelled" 267 "a267_safeSpeedAssist" 266 "a266_overloadProtect" 265 "a265_overheatProtect" 264 "a264_assistTorqueLimited" 263 "a263_espWsStatus" 262 "a262_yawRateStatus" 261 "a261_sccmStatusError" 260 "a260_scoPrivateBusOff" 259 "a259_scoCanBusOff" 258 "a258_pspInvalidProjectParamset" 257 "a257_dcvmUnderVolt" 256 "a256_dcvmOverVolt" 255 "a255_pmState2Mia" 254 "a254_vcFrontMia" 253 "a253_vcFrontCsError" 252 "a252_vcFrontCntError" 251 "a251_uiTuneReqMia" 250 "a250_uiTuneReqCsError" 249 "a249_uiTuneReqCntError" 248 "a248_sccmMia" 247 "a247_sccmCsError" 246 "a246_sccmCntError" 245 "a245_rcmMia" 244 "a244_rcmCsError" 243 "a243_rcmCntError" 242 "a242_gtwConfigMia" 241 "a241_espWsMia" 240 "a240_espWsCsError" 239 "a239_espWsCntError" 238 "a238_espWrMia" 237 "a237_espWrCsError" 236 "a236_espWrCntError" 235 "a235_ecu1StatMia" 234 "a234_ecu1StatCsError" 233 "a233_ecu1StatCntError" 232 "a232_diSpdMia" 231 "a231_diSpdCsError" 230 "a230_diSpdCntError" 229 "a229_dirTorqueMia" 228 "a228_dirTorqueCsError" 227 "a227_dirTorqueCntError" 226 "a226_dasMia" 225 "a225_dasCsError" 224 "a224_dasCntError" 223 "a223_apsMia" 222 "a222_apsCsError" 221 "a221_apsCntError" 220 "a220_transceiverInputqueueOverflow" 219 "a219_frhFastRestartFailed" 218 "a218_aadApplicationStateErr" 217 "a217_msdMasterSilentErr" 216 "a216_isdgImproperShutdown" 215 "a215_vsgSafeViolErr" 214 "a214_velInterfaceErr" 213 "a213_frmHighFrictionDetected" 212 "a212_frmDataLost" 211 "a211_frmInternalErr" 210 "a210_fdrTotalBlocking" 209 "a209_fdrLowSeverityFreezing" 208 "a208_fdrLowSeverityBlocking" 207 "a207_fdrOclFreezing" 206 "a206_fdrOclPartialBlocking" 205 "a205_fdrOclFail" 204 "a204_fdpPrevTrqErr" 203 "a203_ctcInterfaceErr" 202 "a202_ohnvmpStoredOffsetLost" 201 "a201_ammOutputBufferOverflow" 200 "a200_ammInputBufferOverflow" 199 "a199_osumC1StackNearFull" 198 "a198_osumC1CsaNearFull" 197 "a197_difpDifactorInvalid" 196 "a196_topEolTasOffsetInvalid" 195 "a195_imcmCommErrC1" 194 "a194_amNvdataLoss" 193 "a193_osumC0StackNearFull" 192 "a192_osumC0CsaNearFull" 191 "a191_sbcscpVcp2VucVoltFail" 190 "a190_sbchCommBufferOverflow" 189 "a189_sbchCommErrMcuToSbc" 188 "a188_epmCommBufferOverflow" 187 "a187_epmVoltFail" 186 "a186_wdhCommBufferOverflow" 185 "a185_sbcscpQAWatchdogReset" 184 "a184_sbcmCommBufferOverflow" 183 "a183_sbchCommErrSbcToMcu" 182 "a182_mcdInputMia" 181 "a181_dmDeadlineViolationC1" 180 "a180_dmDeadlineViolationC1" 179 "a179_tedMotorcoilTempChecker" 178 "a178_exchWdtException" 177 "a177_etsrInvalidated" 176 "a176_exchCpu1ExceptionReset" 175 "a175_exchFlashStoredConfigErr" 174 "a174_pmpPhasecurrentAge" 173 "a173_pmpRotorspeedAge" 172 "a172_pmpElangMotorcurrentAge" 171 "a171_pmpKgvalueAge" 170 "a170_pmpDcvoltAge" 169 "a169_scpSafetyReset" 168 "a168_c1csInvalidC1App" 167 "a167_iccd1ErrQueueOverflow" 166 "a166_tdaPhasecurrentshuntTempChecker" 165 "a165_tdaDcbusshuntTempChecker" 164 "a164_tdaBattfetjunctionTempChecker" 163 "a163_tdaPowermoduleTempChecker" 162 "a162_tdaBridgefetjunctionTempChecker" 161 "a161_tdaRelayfetjunctionTempChecker" 160 "a160_rsthCpu1UnexpectedAlarm" 159 "a159_exchFlashWordlineTransientErr" 158 "a158_amGduFailDuringRecovery" 157 "a157_mcudcpInvalidEcuId" 156 "a156_amIntSerialErrSafetyReset" 155 "a155_sdsmDataInvalidAll" 154 "a154_sdsmCsErrorInvalidPrimary" 153 "a153_sdsmBlockSelectorInvalid" 152 "a152_exchFlashEccException" 151 "a151_amPermanentEmergencyOffRequested" 150 "a150_amExternalEmergencyOffRequested" 149 "a149_amReversibleEmergencyOffRequested" 148 "a148_mrccExitFromStandbyDetected" 147 "a147_amDcLinkShortedFail" 146 "a146_btarcRcCircuitCheck" 145 "a145_mriPeripheralRaminitFailed" 144 "a144_mriCoreRaminitFailed" 143 "a143_tedEmifilterCmcTempChecker" 142 "a142_tedEmifilterDmcTempChecker" 141 "a141_amFetShortTest" 140 "a140_imcmConfigurationErr" 139 "a139_osehAdditionalOsErr" 138 "a138_osehAdditionalErrWithoutImmReset" 137 "a137_osehErrWithoutImmediateReset" 136 "a136_ftElectricalAngleQf" 135 "a135_tmpsfetjCalculationOverflowErr" 134 "a134_osehGuardedResetAfterErrWithoutReset" 133 "a133_mcusscLbistEcuIdIsNotSupported" 132 "a132_mcusscNotSupportedMcu" 131 "a131_exchGuardedResetAfterPartitionStop" 130 "a130_mrccConfigCsErrorErr" 129 "a129_exchAdditionalExceptionStopRestart" 128 "a128_exchExceptionStopRestart" 127 "a127_exchAdditionalExceptionAfterRst" 126 "a126_mcusscMonbistMiaErr" 125 "a125_mcusscMbistMiaErr" 124 "a124_mcusscMbistEccTransientErr" 123 "a123_imcmCommErr" 122 "a122_pcpBridgeFetShort" 121 "a121_mcusscMbistEccErr" 120 "a120_mcusscFlashEccLatentErr" 119 "a119_mcusscFlashEccCriticalErr" 118 "a118_mcusscFlashCsErrorErr" 117 "a117_mrccStartupRegCsErrorTransientErr" 116 "a116_mrccStartupRegCsErrorStaticErr" 115 "a115_mcusscLbistSingleFail" 114 "a114_osehOsErr" 113 "a113_rsthUncorrectableEndToEndBusErr" 112 "a112_rsthSafetyFlipflopErr" 111 "a111_amCurrentSensingDisconnection" 110 "a110_amPhaseRelaySwitchOffTest" 109 "a109_exhaSysBusOrPeriphErrException" 108 "a108_exhaInternalProtectionException" 107 "a107_exhaOtherNmiException" 106 "a106_exhaSpbBusErrException" 105 "a105_exhaSriBusErrException" 104 "a104_exhaBusMpuException" 103 "a103_exhaUnusedInterruptCallException" 102 "a102_amPhasecurrentQosErr" 101 "a101_sdrvSpcIdMismatch" 100 "a100_amVbrgLssFault" 99 "a099_mcdTorqueMismatchFault" 98 "a098_invErr" 97 "a097_rppRpsMultipleStaticFail" 96 "a096_rppRpsSingleStaticFail" 95 "a095_mdModelBasedMotorIntegrityCheck" 94 "a094_sctpTsuMultipleStaticFail" 93 "a093_sctpTsuSingleStaticFail" 92 "a092_amGduSwitchOffTestBySbc" 91 "a091_bvpBattVoltCrossChkFailed" 90 "a090_etsmWarning" 89 "a089_tedRevercebattfetjunctionTempChecker" 88 "a088_tedMainboardTempChecker" 87 "a087_rsthFlashConfigErr" 86 "a086_rsthRamUncorrEcc" 85 "a085_amGduSwitchOffTestByMcu" 84 "a084_adcTriggerCheck" 83 "a083_tdaDclinkcapacitorTempChecker" 82 "a082_adcTriggerTimeChk" 81 "a081_exchFloatingPointException" 80 "a080_pwmTimerSyncCheck" 79 "a079_gduhComErr" 78 "a078_dmDeadlineViolation" 77 "a077_dmDeadlineViolation" 76 "a076_exchGeneralException" 75 "a075_rsthUnusedOtherModuleAlarm" 74 "a074_rsthUnexpectedAlarm" 73 "a073_rsthOtherEdcEcc" 72 "a072_rsthFlashUncorrEccOrOvfl" 71 "a071_rsthInternalHighVolt" 70 "a070_rsthInternalLowVolt" 69 "a069_rsthCoreTempOutOfRangeHwCheck" 68 "a068_rsthCoreRedundancyErr" 67 "a067_tspmPowermoduleTempImplausible" 66 "a066_amVoltQfErr" 65 "a065_amGduJuncTemp" 64 "a064_amBridgeShort" 63 "a063_amIntRegulatorErr" 62 "a062_amPhaseBridgeCheck" 61 "a061_amIntSerialErr" 60 "a060_amGduFail" 59 "a059_amStartupTestFailed" 58 "a058_amIntVgsUndervtgErr" 57 "a057_amGduVds" 56 "a056_amGduConfigCsErrorCheck" 55 "a055_amExtendedGduTest" 54 "a054_adcUnexpectedData" 53 "a053_adcUnexpectedNumOfData" 52 "a052_ermSdcInputBufferOverflow" 51 "a051_ermMessageErr" 50 "a050_erlErr" 49 "a049_epmLgFail" 48 "a048_epmVcpVoltFail" 47 "a047_epmVregVoltFail" 46 "a046_mcusscOscillatorNotReliable" 45 "a045_psumSbcBandgapVoltErr" 44 "a044_sbcmSbcEepromFail" 43 "a043_sbcmWdStateDisabled" 42 "a042_wdhWdTestFail" 41 "a041_imcmCoreConfigurationMismatch" 40 "a040_swrhLimitedResetRetriesExpired" 39 "a039_csohCh2CsErrorErrAtReset" 38 "a038_csohCh1CsErrorErrAtReset" 37 "a037_epmV5P2Fail" 36 "a036_sbcmSbcBistFailed" 35 "a035_sbchChipIdFail" 34 "a034_sbchReadbackRegFail" 33 "a033_icsvcPswVersionMismatch" 32 "a032_eolpEolCheckFailed" 31 "a031_pmsProductionModeFailed" 30 "a030_rsthClockReset" 29 "a029_smuhSmuCoreCntErrorTestFail" 28 "a028_smuhNonInitDataCorruption" 27 "a027_mcusscDmuHfErr" 26 "a026_mrccCsErrorCheckFail" 25 "a025_btarcCorruptionCheck" 24 "a024_srhCsErrorCheckFail" 23 "a023_btarcCorruptionCheck" 22 "a022_swrhSwResetInfoCorruptionCheck" 21 "a021_osehCsErrorCheck" 20 "a020_mcusscEolEcuIdIntegritiyFail" 19 "a019_rsthHwResetInfoCorruptionCheck" 18 "a018_exchCsErrorCheck" 17 "a017_stmdStmPlausibilityCheckErr" 16 "a016_mcufcCsErrorCheckFail" 15 "a015_mcusscCsErrorCheckFail" 14 "a014_mcusscSffMonitoringMia" 13 "a013_mcusscSffMonitoringFailed" 12 "a012_mcusscMbistEccErr" 11 "a011_mcusscMonbistErr" 10 "a010_svcIncompatibleSwVersions" 9 "a009_mcusscLbistPermanentFail" 8 "a008_psdcPlatformShutdown" 7 "a007_tsmcCoreTempDiff" 6 "a006_swrhResetByInvalidErrid" 5 "a005_scpUnknownResetSource" 4 "a004_scpInputMia" 3 "a003_pspInvalidParamset" 2 "a002_adcMuxErr" 1 "a001_adcCalibrationOrInitFail" 0 "ALERT_DO_NOT_USE_ZERO" ;
VAL_ 1428 EPASTS_alertState 1 "SET" 0 "CLEARED" ;
VAL_ 1428 EPASTS_a264_degradedECU 3 "BOTH_ECU_SIDES" 2 "OTHER_ECU_SIDE" 1 "OWN_ECU_SIDE" 0 "NONE" ;
VAL_ 1428 EPASTS_a264_ownSideDegradationRe 92 "DC_LINK_CAPACITOR_HOTSPOTCASEDIFF_TEMPERATURE" 84 "PHASECURRENT_SHUNT_TEMPERATURE_MOMENTARY" 80 "DC_LINK_CAPACITOR_TEMPERATURE" 52 "EMIFILTER_DMC_TEMPERATURE" 48 "EMIFILTER_CMC_TEMPERATURE" 44 "DCLINK_SHUNT_TEMPERATURE" 40 "PHASECURRENT_SHUNT_TEMPERATURE" 36 "POWER_MODULE_TEMPERATURE" 32 "MOTOR_COIL_TEMPERATURE" 28 "BATTERY_FET_JUNCTION_TEMPERATURE" 24 "MAIN_BOARD_TEMPERATURE" 20 "REVERSE_BATTERY_FET_JUNCTION_TEMPERATURE" 12 "RELAY_FET_JUNCTION_TEMPERATURE" 8 "BRIDGE_FET_JUNCTION_TEMPERATURE" 4 "CORE1_DEGRADATION" 0 "NO_DEGRADATION_ON_THIS_ECU_SIDE" ;
VAL_ 1428 EPASTS_a264_otherSideDegradation 92 "DC_LINK_CAPACITOR_HOTSPOTCASEDIFF_TEMPERATURE" 84 "PHASECURRENT_SHUNT_TEMPERATURE_MOMENTARY" 80 "DC_LINK_CAPACITOR_TEMPERATURE" 52 "EMIFILTER_DMC_TEMPERATURE" 48 "EMIFILTER_CMC_TEMPERATURE" 44 "DCLINK_SHUNT_TEMPERATURE" 40 "PHASECURRENT_SHUNT_TEMPERATURE" 36 "POWER_MODULE_TEMPERATURE" 32 "MOTOR_COIL_TEMPERATURE" 28 "BATTERY_FET_JUNCTION_TEMPERATURE" 24 "MAIN_BOARD_TEMPERATURE" 20 "REVERSE_BATTERY_FET_JUNCTION_TEMPERATURE" 12 "RELAY_FET_JUNCTION_TEMPERATURE" 8 "BRIDGE_FET_JUNCTION_TEMPERATURE" 4 "CORE1_DEGRADATION" 0 "NO_DEGRADATION_ON_THIS_ECU_SIDE" ;
VAL_ 1428 EPASTS_a265_degradedECU 3 "BOTH_ECU_SIDES" 2 "OTHER_ECU_SIDE" 1 "OWN_ECU_SIDE" 0 "NONE" ;
VAL_ 1428 EPASTS_a267_velocityEstimatorSta 5 "BACKUP_MOTOR" 4 "BACKUP_WHEELS_B" 3 "BACKUP_WHEELS_A" 2 "WHEELS_REDUCED" 1 "WHEELS_NORMAL" 0 "NOT_INITIALIZED" ;
